VERSION "ZCU_CANFD2"

NS_ :

BS_ :

BU_ :  ETC IHU ZCUD ZCUP

BO_ 427 ZCUDZCUCANFD2Fr34 : 64 ZCUD
 SG_ ActnOfHiBeamDrv : 343|1@0+ (1,0) [0|1] "" IHU
 SG_ ActnOfHiBeamDrv_UB : 342|1@0+ (1,0) [0|1] "" IHU
 SG_ ActnOfLedPosnLamp : 359|1@0+ (1,0) [0|1] "" IHU
 SG_ ActnOfLedPosnLamp_UB : 358|1@0+ (1,0) [0|1] "" IHU
 SG_ ActnOfLedStopLamp_UB : 341|1@0+ (1,0) [0|1] "" IHU
 SG_ ActnOfLedStopLampActnOfLedStopLamp : 340|1@0+ (1,0) [0|1] "" IHU
 SG_ ActnOfLedStopLampChks : 351|8@0+ (1.0,0.0) [0.0|255.0] "Unitless" IHU
 SG_ ActnOfLedStopLampCntr : 339|4@0+ (1.0,0.0) [0.0|15.0] "Unitless" IHU
 SG_ ActnOfLoBeamDrv_UB : 357|1@0+ (1,0) [0|1] "" IHU
 SG_ ActnOfLoBeamDrvChks : 367|8@0+ (1.0,0.0) [0.0|255.0] "Unitless" IHU
 SG_ ActnOfLoBeamDrvCntr : 355|4@0+ (1.0,0.0) [0.0|15.0] "Unitless" IHU
 SG_ ActnOfLoBeamDrvOnOff : 356|1@0+ (1,0) [0|1] "" IHU
 SG_ ActnOfStopLampDrv : 375|1@0+ (1,0) [0|1] "" IHU
 SG_ ActnOfStopLampDrv_UB : 374|1@0+ (1,0) [0|1] "" IHU
 SG_ ActnOfStopLampPass : 373|1@0+ (1,0) [0|1] "" IHU
 SG_ ActnOfStopLampPass_UB : 372|1@0+ (1,0) [0|1] "" IHU
 SG_ ActvnOfAhbc : 371|1@0+ (1,0) [0|1] "" IHU
 SG_ ActvnOfAhbc_UB : 370|1@0+ (1,0) [0|1] "" IHU
 SG_ ActvnOfRvsg : 369|1@0+ (1,0) [0|1] "" IHU
 SG_ ActvnOfRvsg_UB : 368|1@0+ (1,0) [0|1] "" IHU
 SG_ AntithftActvnReq : 334|1@0+ (1,0) [0|1] "" IHU
 SG_ AntithftActvnReq_UB : 333|1@0+ (1,0) [0|1] "" IHU
 SG_ BattLoSts_UB : 407|1@0+ (1,0) [0|1] "" IHU
 SG_ BattLoStsKey0 : 383|2@0+ (1,0) [0|3] "" IHU
 SG_ BattLoStsKey1 : 381|2@0+ (1,0) [0|3] "" IHU
 SG_ BattLoStsKey10 : 395|2@0+ (1,0) [0|3] "" IHU
 SG_ BattLoStsKey11 : 393|2@0+ (1,0) [0|3] "" IHU
 SG_ BattLoStsKey2 : 379|2@0+ (1,0) [0|3] "" IHU
 SG_ BattLoStsKey3 : 377|2@0+ (1,0) [0|3] "" IHU
 SG_ BattLoStsKey4 : 391|2@0+ (1,0) [0|3] "" IHU
 SG_ BattLoStsKey5 : 389|2@0+ (1,0) [0|3] "" IHU
 SG_ BattLoStsKey6 : 387|2@0+ (1,0) [0|3] "" IHU
 SG_ BattLoStsKey7 : 385|2@0+ (1,0) [0|3] "" IHU
 SG_ BattLoStsKey8 : 399|2@0+ (1,0) [0|3] "" IHU
 SG_ BattLoStsKey9 : 397|2@0+ (1,0) [0|3] "" IHU
 SG_ BexvSts_UB : 425|1@0+ (1,0) [0|1] "" IHU
 SG_ BexvStsExvActrPosn : 415|10@0+ (0.2,0.0) [0.0|100.0] "%" IHU
 SG_ BexvStsExvBlkErr : 417|1@0+ (1,0) [0|1] "" IHU
 SG_ BexvStsExvCalibSts : 421|2@0+ (1,0) [0|3] "" IHU
 SG_ BexvStsExvElecStsErr : 431|3@0+ (1,0) [0|7] "" IHU
 SG_ BexvStsExvMovSts : 416|1@0+ (1,0) [0|1] "" IHU
 SG_ BexvStsExvOvrTempErr : 428|1@0+ (1,0) [0|1] "" IHU
 SG_ BexvStsExvOvrTrvlErr : 427|1@0+ (1,0) [0|1] "" IHU
 SG_ BexvStsExvPreHeatgSts : 426|1@0+ (1,0) [0|1] "" IHU
 SG_ BexvStsExvVoltgRangErr : 419|2@0+ (1,0) [0|3] "" IHU
 SG_ BLEKeyBtnTrStsAndKeyId_UB : 406|1@0+ (1,0) [0|1] "" IHU
 SG_ BLEKeyBtnTrStsAndKeyIdBLEBtnSts : 405|2@0+ (1,0) [0|3] "" IHU
 SG_ BLEKeyBtnTrStsAndKeyIdKeyId3 : 403|4@0+ (1,0) [0|15] "" IHU
 SG_ BLEKeyReadStsToKeyRmnWrn_UB : 424|1@0+ (1,0) [0|1] "" IHU
 SG_ BLEKeyReadStsToKeyRmnWrnKey0 : 439|2@0+ (1,0) [0|3] "" IHU
 SG_ BLEKeyReadStsToKeyRmnWrnKey1 : 437|2@0+ (1,0) [0|3] "" IHU
 SG_ BLEKeyReadStsToKeyRmnWrnKey10 : 451|2@0+ (1,0) [0|3] "" IHU
 SG_ BLEKeyReadStsToKeyRmnWrnKey11 : 449|2@0+ (1,0) [0|3] "" IHU
 SG_ BLEKeyReadStsToKeyRmnWrnKey12 : 463|2@0+ (1,0) [0|3] "" IHU
 SG_ BLEKeyReadStsToKeyRmnWrnKey13 : 461|2@0+ (1,0) [0|3] "" IHU
 SG_ BLEKeyReadStsToKeyRmnWrnKey14 : 459|2@0+ (1,0) [0|3] "" IHU
 SG_ BLEKeyReadStsToKeyRmnWrnKey15 : 457|2@0+ (1,0) [0|3] "" IHU
 SG_ BLEKeyReadStsToKeyRmnWrnKey2 : 435|2@0+ (1,0) [0|3] "" IHU
 SG_ BLEKeyReadStsToKeyRmnWrnKey3 : 433|2@0+ (1,0) [0|3] "" IHU
 SG_ BLEKeyReadStsToKeyRmnWrnKey4 : 447|2@0+ (1,0) [0|3] "" IHU
 SG_ BLEKeyReadStsToKeyRmnWrnKey5 : 445|2@0+ (1,0) [0|3] "" IHU
 SG_ BLEKeyReadStsToKeyRmnWrnKey6 : 443|2@0+ (1,0) [0|3] "" IHU
 SG_ BLEKeyReadStsToKeyRmnWrnKey7 : 441|2@0+ (1,0) [0|3] "" IHU
 SG_ BLEKeyReadStsToKeyRmnWrnKey8 : 455|2@0+ (1,0) [0|3] "" IHU
 SG_ BLEKeyReadStsToKeyRmnWrnKey9 : 453|2@0+ (1,0) [0|3] "" IHU
 SG_ BLEKeyReadStsToVMM_UB : 503|1@0+ (1,0) [0|1] "" IHU
 SG_ BLEKeyReadStsToVMMKey0 : 471|2@0+ (1,0) [0|3] "" IHU
 SG_ BLEKeyReadStsToVMMKey1 : 469|2@0+ (1,0) [0|3] "" IHU
 SG_ BLEKeyReadStsToVMMKey10 : 483|2@0+ (1,0) [0|3] "" IHU
 SG_ BLEKeyReadStsToVMMKey11 : 481|2@0+ (1,0) [0|3] "" IHU
 SG_ BLEKeyReadStsToVMMKey12 : 495|2@0+ (1,0) [0|3] "" IHU
 SG_ BLEKeyReadStsToVMMKey13 : 493|2@0+ (1,0) [0|3] "" IHU
 SG_ BLEKeyReadStsToVMMKey14 : 491|2@0+ (1,0) [0|3] "" IHU
 SG_ BLEKeyReadStsToVMMKey15 : 489|2@0+ (1,0) [0|3] "" IHU
 SG_ BLEKeyReadStsToVMMKey2 : 467|2@0+ (1,0) [0|3] "" IHU
 SG_ BLEKeyReadStsToVMMKey3 : 465|2@0+ (1,0) [0|3] "" IHU
 SG_ BLEKeyReadStsToVMMKey4 : 479|2@0+ (1,0) [0|3] "" IHU
 SG_ BLEKeyReadStsToVMMKey5 : 477|2@0+ (1,0) [0|3] "" IHU
 SG_ BLEKeyReadStsToVMMKey6 : 475|2@0+ (1,0) [0|3] "" IHU
 SG_ BLEKeyReadStsToVMMKey7 : 473|2@0+ (1,0) [0|3] "" IHU
 SG_ BLEKeyReadStsToVMMKey8 : 487|2@0+ (1,0) [0|3] "" IHU
 SG_ BLEKeyReadStsToVMMKey9 : 485|2@0+ (1,0) [0|3] "" IHU
 SG_ BtnErsReq : 329|2@0+ (1,0) [0|3] "" IHU
 SG_ BtnErsReq_UB : 330|1@0+ (1,0) [0|1] "" IHU
 SG_ BtnTrSts : 332|1@0+ (1,0) [0|1] "" IHU
 SG_ BtnTrSts_UB : 331|1@0+ (1,0) [0|1] "" IHU
 SG_ CarLoctrAcoustReq : 511|8@0+ (1,0) [0|255] "" IHU
 SG_ CarLoctrAcoustReq_UB : 502|1@0+ (1,0) [0|1] "" IHU
 SG_ CarLoctrAcoustSts : 497|1@0+ (1,0) [0|1] "" IHU
 SG_ CarLoctrAcoustSts_UB : 496|1@0+ (1,0) [0|1] "" IHU
 SG_ CarLoctrExtrLiSts : 499|1@0+ (1,0) [0|1] "" IHU
 SG_ CarLoctrExtrLiSts_UB : 498|1@0+ (1,0) [0|1] "" IHU
 SG_ ChrgHndlStrtEna : 501|1@0+ (1,0) [0|1] "" IHU
 SG_ ChrgHndlStrtEna_UB : 500|1@0+ (1,0) [0|1] "" IHU
 SG_ VoltKL15 : 12|1@0+ (1,0) [0|1] "" IHU
 SG_ VoltKL15_UB : 11|1@0+ (1,0) [0|1] "" IHU
 SG_ WrcActvFlg : 7|8@0+ (1.0,0.0) [0.0|255.0] "Unitless" IHU
 SG_ WrcActvFlg_UB : 15|1@0+ (1,0) [0|1] "" IHU
 SG_ XcuAcc_UB : 10|1@0+ (1,0) [0|1] "" IHU
 SG_ XcuAccPadAnVolt : 23|8@0+ (0.1,0.0) [0.0|25.5] "Unitless" IHU
 SG_ XcuAccPwmDuty : 31|8@0+ (1.0,0.0) [0.0|255.0] "Unitless" IHU
 SG_ XcuCemWakupVolt : 39|8@0+ (0.1,0.0) [0.0|25.5] "Unitless" IHU
 SG_ XcuCemWakupVolt_UB : 9|1@0+ (1,0) [0|1] "" IHU
 SG_ XcuCharge_UB : 130|1@0+ (1,0) [0|1] "" IHU
 SG_ XcuChargeNVolt : 129|10@0+ (1.0,0.0) [0.0|1023.0] "Unitless" IHU
 SG_ XcuChargePVolt : 151|10@0+ (1.0,0.0) [0.0|1023.0] "Unitless" IHU
 SG_ XcuCpuLoad_UB : 8|1@0+ (1,0) [0|1] "" IHU
 SG_ XcuCpuLoadAvgVal : 47|8@0+ (1.0,0.0) [0.0|255.0] "Unitless" IHU
 SG_ XcuCpuLoadMaxVal : 55|8@0+ (1.0,0.0) [0.0|255.0] "Unitless" IHU
 SG_ XcuCpuLoadMinVal : 63|8@0+ (1.0,0.0) [0.0|255.0] "Unitless" IHU
 SG_ XcuDcWakupVolt : 71|8@0+ (0.1,0.0) [0.0|25.5] "Unitless" IHU
 SG_ XcuDcWakupVolt_UB : 135|1@0+ (1,0) [0|1] "" IHU
 SG_ XcuDiagEnblSts : 79|8@0+ (1.0,0.0) [0.0|255.0] "Unitless" IHU
 SG_ XcuDiagEnblSts_UB : 134|1@0+ (1,0) [0|1] "" IHU
 SG_ XcuDseWtTqProp_UB : 133|1@0+ (1,0) [0|1] "" IHU
 SG_ XcuDseWtTqPropFrnt : 87|16@0+ (1.0,-8000.0) [-8000.0|57535.0] "Unitless" IHU
 SG_ XcuDseWtTqPropRear : 103|16@0+ (1.0,-8000.0) [-8000.0|57535.0] "Unitless" IHU
 SG_ XcuHvilDuty : 119|8@0+ (1.0,0.0) [0.0|255.0] "Unitless" IHU
 SG_ XcuHvilDuty_UB : 132|1@0+ (1,0) [0|1] "" IHU
 SG_ XcuLvBatt3Volt : 127|8@0+ (0.1,0.0) [0.0|25.5] "Unitless" IHU
 SG_ XcuLvBatt3Volt_UB : 131|1@0+ (1,0) [0|1] "" IHU
 SG_ XcuPtSnr5v : 167|8@0+ (0.1,0.0) [0.0|25.5] "Unitless" IHU
 SG_ XcuPtSnr5v_UB : 157|1@0+ (1,0) [0|1] "" IHU
 SG_ XcuPwmFanDuty : 175|8@0+ (1.0,0.0) [0.0|255.0] "Unitless" IHU
 SG_ XcuPwmFanDuty_UB : 156|1@0+ (1,0) [0|1] "" IHU
 SG_ XcuReslovSplyVolt : 183|8@0+ (0.1,0.0) [0.0|25.5] "Unitless" IHU
 SG_ XcuReslovSplyVolt_UB : 155|1@0+ (1,0) [0|1] "" IHU
 SG_ XcuSfCEstWhTq_UB : 154|1@0+ (1,0) [0|1] "" IHU
 SG_ XcuSfCEstWhTqFrntBrkTq : 191|16@0+ (1.0,-8000.0) [-8000.0|57535.0] "Unitless" IHU
 SG_ XcuSfCEstWhTqFrntPropTq : 207|16@0+ (1.0,-8000.0) [-8000.0|57535.0] "Unitless" IHU
 SG_ XcuSfCEstWhTqReBrkTq : 223|16@0+ (1.0,-8000.0) [-8000.0|57535.0] "Unitless" IHU
 SG_ XcuSfCEstWhTqRePropTq : 239|16@0+ (1.0,-8000.0) [-8000.0|57535.0] "Unitless" IHU
 SG_ XCUTemp_UB : 153|1@0+ (1,0) [0|1] "" IHU
 SG_ XCUTempXcuMcuTemp : 255|8@0+ (1.0,-40.0) [-40.0|215.0] "degC" IHU
 SG_ XCUTempXcuPcbTemp : 263|8@0+ (1.0,-40.0) [-40.0|215.0] "degC" IHU
 SG_ XcuV_UB : 152|1@0+ (1,0) [0|1] "" IHU
 SG_ XcuVcc5vLsd : 271|8@0+ (0.1,0.0) [0.0|25.5] "Unitless" IHU
 SG_ XcuVcc5VSnr : 279|8@0+ (0.1,0.0) [0.0|25.5] "Unitless" IHU
 SG_ XcuVqco5vT35584 : 287|8@0+ (0.1,0.0) [0.0|25.5] "Unitless" IHU
 SG_ XcuVqt15vT35584 : 295|8@0+ (0.1,0.0) [0.0|25.5] "Unitless" IHU
 SG_ XcuVqt25vT35584 : 303|8@0+ (0.1,0.0) [0.0|25.5] "Unitless" IHU
 SG_ XcuVquc5vT35584 : 311|8@0+ (0.1,0.0) [0.0|25.5] "Unitless" IHU
 SG_ XcuVqvr5vT35584 : 319|8@0+ (0.1,0.0) [0.0|25.5] "Unitless" IHU
 SG_ XcuWakeupReqSrc : 327|8@0+ (1.0,0.0) [0.0|255.0] "Unitless" IHU
 SG_ XcuWakeupReqSrc_UB : 335|1@0+ (1,0) [0|1] "" IHU

BO_ 922 ZCUDZCUCANFD2Fr35 : 64 ZCUD
 SG_ BtnStsOHC_UB : 51|1@0+ (1,0) [0|1] "" IHU
 SG_ BtnStsOHCIntrLiSwtAllOnSts : 55|1@0+ (1,0) [0|1] "" IHU
 SG_ BtnStsOHCIntrLiSwtAutOnSts : 54|1@0+ (1,0) [0|1] "" IHU
 SG_ BtnStsOHCLiBtnReadingLe : 53|1@0+ (1,0) [0|1] "" IHU
 SG_ BtnStsOHCLiBtnReadingRi : 52|1@0+ (1,0) [0|1] "" IHU
 SG_ BtnStsOHCR_UB : 48|1@0+ (1,0) [0|1] "" IHU
 SG_ BtnStsOHCRLiBtnReadingLe : 50|1@0+ (1,0) [0|1] "" IHU
 SG_ BtnStsOHCRLiBtnReadingRi : 49|1@0+ (1,0) [0|1] "" IHU
 SG_ BtnStsOHTR_UB : 61|1@0+ (1,0) [0|1] "" IHU
 SG_ BtnStsOHTRLiBtnReadingLe : 63|1@0+ (1,0) [0|1] "" IHU
 SG_ BtnStsOHTRLiBtnReadingRi : 62|1@0+ (1,0) [0|1] "" IHU
 SG_ IntLightDrvSideDoorSupply : 7|7@0+ (1.0,0.0) [0.0|100.0] "Unitless" IHU
 SG_ IntLightDrvSideDoorSupply_UB : 0|1@0+ (1,0) [0|1] "" IHU
 SG_ IntLightDrvSideSupply : 15|7@0+ (1.0,0.0) [0.0|100.0] "Unitless" IHU
 SG_ IntLightDrvSideSupply_UB : 8|1@0+ (1,0) [0|1] "" IHU
 SG_ IntLightFootwellSupply : 23|7@0+ (1.0,0.0) [0.0|100.0] "Unitless" IHU
 SG_ IntLightFootwellSupply_UB : 16|1@0+ (1,0) [0|1] "" IHU
 SG_ IntLightLuggageSupply : 31|7@0+ (1.0,0.0) [0.0|100.0] "Unitless" IHU
 SG_ IntLightLuggageSupply_UB : 24|1@0+ (1,0) [0|1] "" IHU
 SG_ IntLightReDrvDoorSupply : 39|7@0+ (1.0,0.0) [0.0|100.0] "Unitless" IHU
 SG_ IntLightReDrvDoorSupply_UB : 32|1@0+ (1,0) [0|1] "" IHU
 SG_ IntLightReDrvSideSupply : 47|7@0+ (1.0,0.0) [0.0|100.0] "Unitless" IHU
 SG_ IntLightReDrvSideSupply_UB : 40|1@0+ (1,0) [0|1] "" IHU
 SG_ IntrLiCmdGroup_UB : 60|1@0+ (1,0) [0|1] "" IHU
 SG_ IntrLiCmdGroupIntrLiActvn : 59|1@0+ (1,0) [0|1] "" IHU
 SG_ IntrLiCmdGroupIntrLiRoofDim : 58|1@0+ (1,0) [0|1] "" IHU
 SG_ IntrLiCmdGroupIntrLiRoofDmdOff : 57|1@0+ (1,0) [0|1] "" IHU
 SG_ IntrMirrResp_UB : 56|1@0+ (1,0) [0|1] "" IHU
 SG_ IntrMirrRespIntrMirrDimPerc : 71|8@0+ (0.392156862745,0.0) [0.0|99.999999999975] "%" IHU
 SG_ IntrMirrRespIntrMirrIntFailr : 73|1@0+ (1,0) [0|1] "" IHU
 SG_ IntrMirrRespResdBoolean : 72|1@0+ (1,0) [0|1] "" IHU
 SG_ IntrMirrRespResdUInt6 : 79|6@0+ (1.0,0.0) [0.0|63.0] "Unitless" IHU
 SG_ LiLvrDiagc : 91|2@0+ (1,0) [0|3] "" IHU
 SG_ LiLvrDiagc_UB : 92|1@0+ (1,0) [0|1] "" IHU
 SG_ OHCFrBtnErrSts_UB : 83|1@0+ (1,0) [0|1] "" IHU
 SG_ OHCFrBtnErrStsIntrLiSwtAllOnSts : 87|1@0+ (1,0) [0|1] "" IHU
 SG_ OHCFrBtnErrStsIntrLiSwtAutOnSts : 86|1@0+ (1,0) [0|1] "" IHU
 SG_ OHCFrBtnErrStsLiBtnReadingLe : 85|1@0+ (1,0) [0|1] "" IHU
 SG_ OHCFrBtnErrStsLiBtnReadingRi : 84|1@0+ (1,0) [0|1] "" IHU
 SG_ OHCSecRowBtnErrSts_UB : 80|1@0+ (1,0) [0|1] "" IHU
 SG_ OHCSecRowBtnErrStsLiBtnReadingLe : 82|1@0+ (1,0) [0|1] "" IHU
 SG_ OHCSecRowBtnErrStsLiBtnReadingRi : 81|1@0+ (1,0) [0|1] "" IHU
 SG_ OHCThirdRowBtnErrSts_UB : 93|1@0+ (1,0) [0|1] "" IHU
 SG_ OHCThirdRowBtnErrStsLiBtnReadingLe : 95|1@0+ (1,0) [0|1] "" IHU
 SG_ OHCThirdRowBtnErrStsLiBtnReadingRi : 94|1@0+ (1,0) [0|1] "" IHU
 SG_ RainSnsrDiagc_UB : 96|1@0+ (1,0) [0|1] "" IHU
 SG_ RainSnsrDiagcRainSnsrHiTDetd : 89|1@0+ (1,0) [0|1] "" IHU
 SG_ RainSnsrDiagcRainSnsrHiVoltDetd : 88|1@0+ (1,0) [0|1] "" IHU
 SG_ RainSnsrErr_UB : 107|1@0+ (1,0) [0|1] "" IHU
 SG_ RainSnsrErrCalErr : 111|1@0+ (1,0) [0|1] "" IHU
 SG_ RainSnsrErrCalErrActv : 110|1@0+ (1,0) [0|1] "" IHU
 SG_ RainSnsrErrRainDetnErr : 109|1@0+ (1,0) [0|1] "" IHU
 SG_ RainSnsrErrRainDetnErrActv : 108|1@0+ (1,0) [0|1] "" IHU
 SG_ ReadLiErrSts_UB : 97|1@0+ (1,0) [0|1] "" IHU
 SG_ ReadLiErrStsReadLiStsFirstRowLe : 103|1@0+ (1,0) [0|1] "" IHU
 SG_ ReadLiErrStsReadLiStsFirstRowRi : 102|1@0+ (1,0) [0|1] "" IHU
 SG_ ReadLiErrStsReadLiStsSecondRowLe : 101|1@0+ (1,0) [0|1] "" IHU
 SG_ ReadLiErrStsReadLiStsSecondRowRi : 100|1@0+ (1,0) [0|1] "" IHU
 SG_ ReadLiErrStsReadLiStsThirdRowLe : 99|1@0+ (1,0) [0|1] "" IHU
 SG_ ReadLiErrStsReadLiStsThirdRowRi : 98|1@0+ (1,0) [0|1] "" IHU
 SG_ ReadLiIntensityVal_UB : 154|1@0+ (1,0) [0|1] "" IHU
 SG_ ReadLiIntensityValZone1 : 116|5@0+ (1.0,0.0) [0.0|31.0] "Unitless" IHU
 SG_ ReadLiIntensityValZone2 : 127|5@0+ (1.0,0.0) [0.0|31.0] "Unitless" IHU
 SG_ ReadLiIntensityValZone3 : 135|5@0+ (1.0,0.0) [0.0|31.0] "Unitless" IHU
 SG_ ReadLiIntensityValZone4 : 143|5@0+ (1.0,0.0) [0.0|31.0] "Unitless" IHU
 SG_ ReadLiIntensityValZone5 : 151|5@0+ (1.0,0.0) [0.0|31.0] "Unitless" IHU
 SG_ ReadLiIntensityValZone6 : 159|5@0+ (1.0,0.0) [0.0|31.0] "Unitless" IHU
 SG_ StsOfLogoFolwLoBeam : 105|2@0+ (1,0) [0|3] "" IHU
 SG_ StsOfLogoFolwLoBeam_UB : 106|1@0+ (1,0) [0|1] "" IHU
 SG_ WipgAutFrntMod : 119|2@0+ (1,0) [0|3] "" IHU
 SG_ WipgAutFrntMod_UB : 117|1@0+ (1,0) [0|1] "" IHU
 SG_ WiprLvrDiagc : 153|2@0+ (1,0) [0|3] "" IHU
 SG_ WiprLvrDiagc_UB : 167|1@0+ (1,0) [0|1] "" IHU

BO_ 1264 ZCUDZCUCANFD2Fr36 : 64 ZCUD
 SG_ BswAppVersion : 7|64@0+ (1.0,0.0) [0.0|18446744073709552000.0] "Unitless" IHU
 SG_ BswAppVersion_UB : 183|1@0+ (1,0) [0|1] "" IHU
 SG_ BswCalVersion : 71|64@0+ (1.0,0.0) [0.0|18446744073709552000.0] "Unitless" IHU
 SG_ BswCalVersion_UB : 182|1@0+ (1,0) [0|1] "" IHU
 SG_ BswRervedSignal : 135|32@0+ (1.0,0.0) [0.0|4294967295.0] "Unitless" IHU
 SG_ BswRervedSignal_UB : 181|1@0+ (1,0) [0|1] "" IHU
 SG_ VcEvFehMsgRedPerf : 167|16@0+ (1.0,0.0) [0.0|65535.0] "Unitless" IHU
 SG_ VcEvFehMsgRedPerf_UB : 180|1@0+ (1,0) [0|1] "" IHU

BO_ 431 ZCUDZCUCANFD2Fr37 : 64 ZCUD
 SG_ CarLoctrReq : 55|2@0+ (1.0,0.0) [0.0|3.0] "Unitless" IHU
 SG_ CarLoctrReq_UB : 63|1@0+ (1,0) [0|1] "" IHU
 SG_ CmprSpdIncrReq : 41|1@0+ (1,0) [0|1] "" IHU
 SG_ CmprSpdIncrReq_UB : 40|1@0+ (1,0) [0|1] "" IHU
 SG_ DecUsgModAut : 7|1@0+ (1,0) [0|1] "" IHU
 SG_ DecUsgModAut_UB : 6|1@0+ (1,0) [0|1] "" IHU
 SG_ DecUsgModAut2 : 5|1@0+ (1,0) [0|1] "" IHU
 SG_ DecUsgModAut2_UB : 4|1@0+ (1,0) [0|1] "" IHU
 SG_ DigKeyIntrVldDetd : 3|1@0+ (1,0) [0|1] "" IHU
 SG_ DigKeyIntrVldDetd_UB : 2|1@0+ (1,0) [0|1] "" IHU
 SG_ DlyClsReq : 1|1@0+ (1,0) [0|1] "" IHU
 SG_ DlyClsReq_UB : 0|1@0+ (1,0) [0|1] "" IHU
 SG_ DoorDrvrAcsKeylsReq : 15|2@0+ (1,0) [0|3] "" IHU
 SG_ DoorDrvrAcsKeylsReq_UB : 23|1@0+ (1,0) [0|1] "" IHU
 SG_ DoorDrvrAcsKeylsSts : 43|1@0+ (1,0) [0|1] "" IHU
 SG_ DoorDrvrAcsKeylsSts_UB : 42|1@0+ (1,0) [0|1] "" IHU
 SG_ DoorDrvrHndlCmd : 13|2@0+ (1,0) [0|3] "" IHU
 SG_ DoorDrvrHndlCmd_UB : 22|1@0+ (1,0) [0|1] "" IHU
 SG_ DoorDrvrOpenLowReqOutdSwt1 : 11|2@0+ (1,0) [0|3] "" IHU
 SG_ DoorDrvrOpenLowReqOutdSwt1_UB : 21|1@0+ (1,0) [0|1] "" IHU
 SG_ DoorDrvrOpenReqInsdSwt1 : 9|2@0+ (1,0) [0|3] "" IHU
 SG_ DoorDrvrOpenReqInsdSwt1_UB : 20|1@0+ (1,0) [0|1] "" IHU
 SG_ DoorDrvrRelsReq : 31|2@0+ (1,0) [0|3] "" IHU
 SG_ DoorDrvrRelsReq_UB : 19|1@0+ (1,0) [0|1] "" IHU
 SG_ DoorLeReAcsKeylsReq : 29|2@0+ (1,0) [0|3] "" IHU
 SG_ DoorLeReAcsKeylsReq_UB : 18|1@0+ (1,0) [0|1] "" IHU
 SG_ DoorLeReAcsKeylsSts : 45|1@0+ (1,0) [0|1] "" IHU
 SG_ DoorLeReAcsKeylsSts_UB : 44|1@0+ (1,0) [0|1] "" IHU
 SG_ DoorLeReOpenLowReqOutdSwt1 : 27|2@0+ (1,0) [0|3] "" IHU
 SG_ DoorLeReOpenLowReqOutdSwt1_UB : 17|1@0+ (1,0) [0|1] "" IHU
 SG_ DoorLeReOpenReqInsdSwt1 : 25|2@0+ (1,0) [0|3] "" IHU
 SG_ DoorLeReOpenReqInsdSwt1_UB : 16|1@0+ (1,0) [0|1] "" IHU
 SG_ DoorPassAcsKeylsReq : 39|2@0+ (1,0) [0|3] "" IHU
 SG_ DoorPassAcsKeylsReq_UB : 37|1@0+ (1,0) [0|1] "" IHU
 SG_ DoorPassAcsKeylsSts : 33|1@0+ (1,0) [0|1] "" IHU
 SG_ DoorPassAcsKeylsSts_UB : 32|1@0+ (1,0) [0|1] "" IHU
 SG_ DoorRiReAcsKeylsReq : 35|2@0+ (1,0) [0|3] "" IHU
 SG_ DoorRiReAcsKeylsReq_UB : 36|1@0+ (1,0) [0|1] "" IHU
 SG_ DoorRiReAcsKeylsSts : 47|1@0+ (1,0) [0|1] "" IHU
 SG_ DoorRiReAcsKeylsSts_UB : 46|1@0+ (1,0) [0|1] "" IHU
 SG_ DrvrIntrLockSngSwt : 59|1@0+ (1,0) [0|1] "" IHU
 SG_ DrvrIntrLockSngSwt_UB : 58|1@0+ (1,0) [0|1] "" IHU
 SG_ EasyInOutDrvrReq : 53|2@0+ (1,0) [0|3] "" IHU
 SG_ EasyInOutDrvrReq_UB : 62|1@0+ (1,0) [0|1] "" IHU
 SG_ EngActvnMod1WdReq : 51|2@0+ (1,0) [0|3] "" IHU
 SG_ EngActvnMod1WdReq_UB : 61|1@0+ (1,0) [0|1] "" IHU
 SG_ ErsLockReqByKey : 57|1@0+ (1,0) [0|1] "" IHU
 SG_ ErsLockReqByKey_UB : 56|1@0+ (1,0) [0|1] "" IHU
 SG_ FacQlyForDoorDrvrSts : 49|2@0+ (1,0) [0|3] "" IHU
 SG_ FacQlyForDoorDrvrSts_UB : 60|1@0+ (1,0) [0|1] "" IHU
 SG_ FbOfPrkgLiShow : 119|2@0+ (1,0) [0|3] "" IHU
 SG_ FbOfPrkgLiShow_UB : 117|1@0+ (1,0) [0|1] "" IHU
 SG_ GlvBoxIntrSwtSts : 77|1@0+ (1,0) [0|1] "" IHU
 SG_ GlvBoxIntrSwtSts_UB : 76|1@0+ (1,0) [0|1] "" IHU
 SG_ GrlAutoCalibReq : 75|1@0+ (1,0) [0|1] "" IHU
 SG_ GrlAutoCalibReq_UB : 74|1@0+ (1,0) [0|1] "" IHU
 SG_ GrlHldTrqActive : 73|1@0+ (1,0) [0|1] "" IHU
 SG_ GrlHldTrqActive_UB : 72|1@0+ (1,0) [0|1] "" IHU
 SG_ GrlShttrDmd_UB : 78|1@0+ (1,0) [0|1] "" IHU
 SG_ GrlShttrDmdShttrCalEna : 79|1@0+ (1,0) [0|1] "" IHU
 SG_ GrlShttrDmdShttrPosnReq : 71|8@0+ (1.0,0.0) [0.0|255.0] "Unitless" IHU
 SG_ GrlShttrMoveActive : 106|1@0+ (1,0) [0|1] "" IHU
 SG_ GrlShttrMoveActive_UB : 105|1@0+ (1,0) [0|1] "" IHU
 SG_ GrlShttrSts_UB : 104|1@0+ (1,0) [0|1] "" IHU
 SG_ GrlShttrStsShttrActrFlt : 95|1@0+ (1,0) [0|1] "" IHU
 SG_ GrlShttrStsShttrBlkd : 94|1@0+ (1,0) [0|1] "" IHU
 SG_ GrlShttrStsShttrCalActv : 93|1@0+ (1,0) [0|1] "" IHU
 SG_ GrlShttrStsShttrCalIndcd : 92|1@0+ (1,0) [0|1] "" IHU
 SG_ GrlShttrStsShttrElecErr : 91|1@0+ (1,0) [0|1] "" IHU
 SG_ GrlShttrStsShttrPosnRaw : 87|8@0+ (1.0,0.0) [0.0|255.0] "Unitless" IHU
 SG_ GrlShttrStsShttrSnsrFlt : 90|1@0+ (1,0) [0|1] "" IHU
 SG_ GrlShttrStsShttrTErr : 89|1@0+ (1,0) [0|1] "" IHU
 SG_ GrlShttrStsShttrULoErr : 88|1@0+ (1,0) [0|1] "" IHU
 SG_ HoodSwt1 : 115|2@0+ (1,0) [0|3] "" IHU
 SG_ HoodSwt1_UB : 116|1@0+ (1,0) [0|1] "" IHU
 SG_ KeyDiReq_UB : 107|1@0+ (1,0) [0|1] "" IHU
 SG_ KeyDiReqKey0 : 103|1@0+ (1,0) [0|1] "" IHU
 SG_ KeyDiReqKey1 : 102|1@0+ (1,0) [0|1] "" IHU
 SG_ KeyDiReqKey10 : 109|1@0+ (1,0) [0|1] "" IHU
 SG_ KeyDiReqKey11 : 108|1@0+ (1,0) [0|1] "" IHU
 SG_ KeyDiReqKey2 : 101|1@0+ (1,0) [0|1] "" IHU
 SG_ KeyDiReqKey3 : 100|1@0+ (1,0) [0|1] "" IHU
 SG_ KeyDiReqKey4 : 99|1@0+ (1,0) [0|1] "" IHU
 SG_ KeyDiReqKey5 : 98|1@0+ (1,0) [0|1] "" IHU
 SG_ KeyDiReqKey6 : 97|1@0+ (1,0) [0|1] "" IHU
 SG_ KeyDiReqKey7 : 96|1@0+ (1,0) [0|1] "" IHU
 SG_ KeyDiReqKey8 : 111|1@0+ (1,0) [0|1] "" IHU
 SG_ KeyDiReqKey9 : 110|1@0+ (1,0) [0|1] "" IHU
 SG_ KeyReadReqFromKeyRmn : 127|4@0+ (1,0) [0|15] "" IHU
 SG_ KeyReadReqFromKeyRmn_UB : 113|1@0+ (1,0) [0|1] "" IHU
 SG_ KeyReadReqFromKeyWarn : 123|4@0+ (1,0) [0|15] "" IHU
 SG_ KeyReadReqFromKeyWarn_UB : 112|1@0+ (1,0) [0|1] "" IHU
 SG_ KeyReadStsToKeyRmn_UB : 159|1@0+ (1,0) [0|1] "" IHU
 SG_ KeyReadStsToKeyRmnKey0 : 135|2@0+ (1,0) [0|3] "" IHU
 SG_ KeyReadStsToKeyRmnKey1 : 133|2@0+ (1,0) [0|3] "" IHU
 SG_ KeyReadStsToKeyRmnKey10 : 147|2@0+ (1,0) [0|3] "" IHU
 SG_ KeyReadStsToKeyRmnKey11 : 145|2@0+ (1,0) [0|3] "" IHU
 SG_ KeyReadStsToKeyRmnKey2 : 131|2@0+ (1,0) [0|3] "" IHU
 SG_ KeyReadStsToKeyRmnKey3 : 129|2@0+ (1,0) [0|3] "" IHU
 SG_ KeyReadStsToKeyRmnKey4 : 143|2@0+ (1,0) [0|3] "" IHU
 SG_ KeyReadStsToKeyRmnKey5 : 141|2@0+ (1,0) [0|3] "" IHU
 SG_ KeyReadStsToKeyRmnKey6 : 139|2@0+ (1,0) [0|3] "" IHU
 SG_ KeyReadStsToKeyRmnKey7 : 137|2@0+ (1,0) [0|3] "" IHU
 SG_ KeyReadStsToKeyRmnKey8 : 151|2@0+ (1,0) [0|3] "" IHU
 SG_ KeyReadStsToKeyRmnKey9 : 149|2@0+ (1,0) [0|3] "" IHU
 SG_ KeyReadStsToKeyWarn_UB : 158|1@0+ (1,0) [0|1] "" IHU
 SG_ KeyReadStsToKeyWarnKey0 : 167|2@0+ (1,0) [0|3] "" IHU
 SG_ KeyReadStsToKeyWarnKey1 : 165|2@0+ (1,0) [0|3] "" IHU
 SG_ KeyReadStsToKeyWarnKey10 : 179|2@0+ (1,0) [0|3] "" IHU
 SG_ KeyReadStsToKeyWarnKey11 : 177|2@0+ (1,0) [0|3] "" IHU
 SG_ KeyReadStsToKeyWarnKey2 : 163|2@0+ (1,0) [0|3] "" IHU
 SG_ KeyReadStsToKeyWarnKey3 : 161|2@0+ (1,0) [0|3] "" IHU
 SG_ KeyReadStsToKeyWarnKey4 : 175|2@0+ (1,0) [0|3] "" IHU
 SG_ KeyReadStsToKeyWarnKey5 : 173|2@0+ (1,0) [0|3] "" IHU
 SG_ KeyReadStsToKeyWarnKey6 : 171|2@0+ (1,0) [0|3] "" IHU
 SG_ KeyReadStsToKeyWarnKey7 : 169|2@0+ (1,0) [0|3] "" IHU
 SG_ KeyReadStsToKeyWarnKey8 : 183|2@0+ (1,0) [0|3] "" IHU
 SG_ KeyReadStsToKeyWarnKey9 : 181|2@0+ (1,0) [0|3] "" IHU
 SG_ KeyReadStsToVmm_UB : 157|1@0+ (1,0) [0|1] "" IHU
 SG_ KeyReadStsToVmmKey0 : 191|2@0+ (1,0) [0|3] "" IHU
 SG_ KeyReadStsToVmmKey1 : 189|2@0+ (1,0) [0|3] "" IHU
 SG_ KeyReadStsToVmmKey10 : 203|2@0+ (1,0) [0|3] "" IHU
 SG_ KeyReadStsToVmmKey11 : 201|2@0+ (1,0) [0|3] "" IHU
 SG_ KeyReadStsToVmmKey2 : 187|2@0+ (1,0) [0|3] "" IHU
 SG_ KeyReadStsToVmmKey3 : 185|2@0+ (1,0) [0|3] "" IHU
 SG_ KeyReadStsToVmmKey4 : 199|2@0+ (1,0) [0|3] "" IHU
 SG_ KeyReadStsToVmmKey5 : 197|2@0+ (1,0) [0|3] "" IHU
 SG_ KeyReadStsToVmmKey6 : 195|2@0+ (1,0) [0|3] "" IHU
 SG_ KeyReadStsToVmmKey7 : 193|2@0+ (1,0) [0|3] "" IHU
 SG_ KeyReadStsToVmmKey8 : 207|2@0+ (1,0) [0|3] "" IHU
 SG_ KeyReadStsToVmmKey9 : 205|2@0+ (1,0) [0|3] "" IHU
 SG_ KeyReadStsToVMMNFC_UB : 156|1@0+ (1,0) [0|1] "" IHU
 SG_ KeyReadStsToVMMNFCKey0 : 215|2@0+ (1,0) [0|3] "" IHU
 SG_ KeyReadStsToVMMNFCKey1 : 213|2@0+ (1,0) [0|3] "" IHU
 SG_ KeyReadStsToVMMNFCKey10 : 227|2@0+ (1,0) [0|3] "" IHU
 SG_ KeyReadStsToVMMNFCKey11 : 225|2@0+ (1,0) [0|3] "" IHU
 SG_ KeyReadStsToVMMNFCKey12 : 239|2@0+ (1,0) [0|3] "" IHU
 SG_ KeyReadStsToVMMNFCKey13 : 237|2@0+ (1,0) [0|3] "" IHU
 SG_ KeyReadStsToVMMNFCKey14 : 235|2@0+ (1,0) [0|3] "" IHU
 SG_ KeyReadStsToVMMNFCKey15 : 233|2@0+ (1,0) [0|3] "" IHU
 SG_ KeyReadStsToVMMNFCKey2 : 211|2@0+ (1,0) [0|3] "" IHU
 SG_ KeyReadStsToVMMNFCKey3 : 209|2@0+ (1,0) [0|3] "" IHU
 SG_ KeyReadStsToVMMNFCKey4 : 223|2@0+ (1,0) [0|3] "" IHU
 SG_ KeyReadStsToVMMNFCKey5 : 221|2@0+ (1,0) [0|3] "" IHU
 SG_ KeyReadStsToVMMNFCKey6 : 219|2@0+ (1,0) [0|3] "" IHU
 SG_ KeyReadStsToVMMNFCKey7 : 217|2@0+ (1,0) [0|3] "" IHU
 SG_ KeyReadStsToVMMNFCKey8 : 231|2@0+ (1,0) [0|3] "" IHU
 SG_ KeyReadStsToVMMNFCKey9 : 229|2@0+ (1,0) [0|3] "" IHU
 SG_ LiOprnMod : 247|2@0+ (1,0) [0|3] "" IHU
 SG_ LiOprnMod_UB : 245|1@0+ (1,0) [0|1] "" IHU
 SG_ MobDeBtnCarLctrSts : 244|1@0+ (1,0) [0|1] "" IHU
 SG_ MobDeBtnCarLctrSts_UB : 243|1@0+ (1,0) [0|1] "" IHU
 SG_ MobDeBtnPanicAlarmSts : 241|2@0+ (1,0) [0|3] "" IHU
 SG_ MobDeBtnPanicAlarmSts_UB : 242|1@0+ (1,0) [0|1] "" IHU
 SG_ MobDevAVPReq : 249|1@0+ (1,0) [0|1] "" IHU
 SG_ MobDevAVPReq_UB : 248|1@0+ (1,0) [0|1] "" IHU
 SG_ MobDevBtnLockStsAndKeyId_UB : 250|1@0+ (1,0) [0|1] "" IHU
 SG_ MobDevBtnLockStsAndKeyIdKeyId3 : 255|4@0+ (1,0) [0|15] "" IHU
 SG_ MobDevBtnLockStsAndKeyIdPsdNotPsd : 251|1@0+ (1,0) [0|1] "" IHU
 SG_ MobDevBtnTrReq : 327|3@0+ (1,0) [0|7] "" IHU
 SG_ MobDevBtnTrReq_UB : 324|1@0+ (1,0) [0|1] "" IHU
 SG_ MobDevBtnUnlckStsAndKeyId_UB : 258|1@0+ (1,0) [0|1] "" IHU
 SG_ MobDevBtnUnlckStsAndKeyIdKeyId3 : 263|4@0+ (1,0) [0|15] "" IHU
 SG_ MobDevBtnUnlckStsAndKeyIdPsdNotPsd : 259|1@0+ (1,0) [0|1] "" IHU
 SG_ MobDevChrgngLidOpnReq : 257|1@0+ (1,0) [0|1] "" IHU
 SG_ MobDevChrgngLidOpnReq_UB : 256|1@0+ (1,0) [0|1] "" IHU
 SG_ MobDevKeyDiReq_UB : 287|1@0+ (1,0) [0|1] "" IHU
 SG_ MobDevKeyDiReqKeySts0 : 271|1@0+ (1,0) [0|1] "" IHU
 SG_ MobDevKeyDiReqKeySts1 : 270|1@0+ (1,0) [0|1] "" IHU
 SG_ MobDevKeyDiReqKeySts10 : 277|1@0+ (1,0) [0|1] "" IHU
 SG_ MobDevKeyDiReqKeySts11 : 276|1@0+ (1,0) [0|1] "" IHU
 SG_ MobDevKeyDiReqKeySts12 : 275|1@0+ (1,0) [0|1] "" IHU
 SG_ MobDevKeyDiReqKeySts13 : 274|1@0+ (1,0) [0|1] "" IHU
 SG_ MobDevKeyDiReqKeySts14 : 273|1@0+ (1,0) [0|1] "" IHU
 SG_ MobDevKeyDiReqKeySts15 : 272|1@0+ (1,0) [0|1] "" IHU
 SG_ MobDevKeyDiReqKeySts2 : 269|1@0+ (1,0) [0|1] "" IHU
 SG_ MobDevKeyDiReqKeySts3 : 268|1@0+ (1,0) [0|1] "" IHU
 SG_ MobDevKeyDiReqKeySts4 : 267|1@0+ (1,0) [0|1] "" IHU
 SG_ MobDevKeyDiReqKeySts5 : 266|1@0+ (1,0) [0|1] "" IHU
 SG_ MobDevKeyDiReqKeySts6 : 265|1@0+ (1,0) [0|1] "" IHU
 SG_ MobDevKeyDiReqKeySts7 : 264|1@0+ (1,0) [0|1] "" IHU
 SG_ MobDevKeyDiReqKeySts8 : 279|1@0+ (1,0) [0|1] "" IHU
 SG_ MobDevKeyDiReqKeySts9 : 278|1@0+ (1,0) [0|1] "" IHU
 SG_ MobDevKeyEnaSts_UB : 286|1@0+ (1,0) [0|1] "" IHU
 SG_ MobDevKeyEnaStsKey0 : 295|2@0+ (1,0) [0|3] "" IHU
 SG_ MobDevKeyEnaStsKey1 : 293|2@0+ (1,0) [0|3] "" IHU
 SG_ MobDevKeyEnaStsKey10 : 307|2@0+ (1,0) [0|3] "" IHU
 SG_ MobDevKeyEnaStsKey11 : 305|2@0+ (1,0) [0|3] "" IHU
 SG_ MobDevKeyEnaStsKey12 : 319|2@0+ (1,0) [0|3] "" IHU
 SG_ MobDevKeyEnaStsKey13 : 317|2@0+ (1,0) [0|3] "" IHU
 SG_ MobDevKeyEnaStsKey14 : 315|2@0+ (1,0) [0|3] "" IHU
 SG_ MobDevKeyEnaStsKey15 : 313|2@0+ (1,0) [0|3] "" IHU
 SG_ MobDevKeyEnaStsKey2 : 291|2@0+ (1,0) [0|3] "" IHU
 SG_ MobDevKeyEnaStsKey3 : 289|2@0+ (1,0) [0|3] "" IHU
 SG_ MobDevKeyEnaStsKey4 : 303|2@0+ (1,0) [0|3] "" IHU
 SG_ MobDevKeyEnaStsKey5 : 301|2@0+ (1,0) [0|3] "" IHU
 SG_ MobDevKeyEnaStsKey6 : 299|2@0+ (1,0) [0|3] "" IHU
 SG_ MobDevKeyEnaStsKey7 : 297|2@0+ (1,0) [0|3] "" IHU
 SG_ MobDevKeyEnaStsKey8 : 311|2@0+ (1,0) [0|3] "" IHU
 SG_ MobDevKeyEnaStsKey9 : 309|2@0+ (1,0) [0|3] "" IHU
 SG_ MobDevOpenClsCmftReq : 285|2@0+ (1,0) [0|3] "" IHU
 SG_ MobDevOpenClsCmftReq_UB : 283|1@0+ (1,0) [0|1] "" IHU
 SG_ MobDevRoofOpnClsReq : 281|2@0+ (1,0) [0|3] "" IHU
 SG_ MobDevRoofOpnClsReq_UB : 282|1@0+ (1,0) [0|1] "" IHU
 SG_ MobDevVldUserStsToVMM : 384|1@0+ (1,0) [0|1] "" IHU
 SG_ MobDevVldUserStsToVMM_UB : 368|1@0+ (1,0) [0|1] "" IHU
 SG_ MobDevWinOpnClsReq : 323|2@0+ (1,0) [0|3] "" IHU
 SG_ MobDevWinOpnClsReq_UB : 321|1@0+ (1,0) [0|1] "" IHU
 SG_ NFCKeyReadStsToKeyRmnWrn_UB : 320|1@0+ (1,0) [0|1] "" IHU
 SG_ NFCKeyReadStsToKeyRmnWrnKey0 : 335|2@0+ (1,0) [0|3] "" IHU
 SG_ NFCKeyReadStsToKeyRmnWrnKey1 : 333|2@0+ (1,0) [0|3] "" IHU
 SG_ NFCKeyReadStsToKeyRmnWrnKey10 : 347|2@0+ (1,0) [0|3] "" IHU
 SG_ NFCKeyReadStsToKeyRmnWrnKey11 : 345|2@0+ (1,0) [0|3] "" IHU
 SG_ NFCKeyReadStsToKeyRmnWrnKey12 : 359|2@0+ (1,0) [0|3] "" IHU
 SG_ NFCKeyReadStsToKeyRmnWrnKey13 : 357|2@0+ (1,0) [0|3] "" IHU
 SG_ NFCKeyReadStsToKeyRmnWrnKey14 : 355|2@0+ (1,0) [0|3] "" IHU
 SG_ NFCKeyReadStsToKeyRmnWrnKey15 : 353|2@0+ (1,0) [0|3] "" IHU
 SG_ NFCKeyReadStsToKeyRmnWrnKey2 : 331|2@0+ (1,0) [0|3] "" IHU
 SG_ NFCKeyReadStsToKeyRmnWrnKey3 : 329|2@0+ (1,0) [0|3] "" IHU
 SG_ NFCKeyReadStsToKeyRmnWrnKey4 : 343|2@0+ (1,0) [0|3] "" IHU
 SG_ NFCKeyReadStsToKeyRmnWrnKey5 : 341|2@0+ (1,0) [0|3] "" IHU
 SG_ NFCKeyReadStsToKeyRmnWrnKey6 : 339|2@0+ (1,0) [0|3] "" IHU
 SG_ NFCKeyReadStsToKeyRmnWrnKey7 : 337|2@0+ (1,0) [0|3] "" IHU
 SG_ NFCKeyReadStsToKeyRmnWrnKey8 : 351|2@0+ (1,0) [0|3] "" IHU
 SG_ NFCKeyReadStsToKeyRmnWrnKey9 : 349|2@0+ (1,0) [0|3] "" IHU
 SG_ OutdBri_UB : 369|1@0+ (1,0) [0|1] "" IHU
 SG_ OutdBriChks : 367|8@0+ (1.0,0.0) [0.0|255.0] "Unitless" IHU
 SG_ OutdBriCntr : 375|4@0+ (1.0,0.0) [0.0|15.0] "Unitless" IHU
 SG_ OutdBriHw_UB : 385|1@0+ (1,0) [0|1] "" IHU
 SG_ OutdBriHwChks : 383|8@0+ (1.0,0.0) [0.0|255.0] "Unitless" IHU
 SG_ OutdBriHwCntr : 391|4@0+ (1.0,0.0) [0.0|15.0] "Unitless" IHU
 SG_ OutdBriHwOutdBriSts : 387|2@0+ (1,0) [0|3] "" IHU
 SG_ OutdBriSts : 371|2@0+ (1,0) [0|3] "" IHU
 SG_ SteerLockChk_UB : 454|1@0+ (1,0) [0|1] "" IHU
 SG_ SteerLockChkSteerLockDataChk0 : 399|8@0+ (1.0,0.0) [0.0|255.0] "Unitless" IHU
 SG_ SteerLockChkSteerLockDataChk1 : 407|8@0+ (1.0,0.0) [0.0|255.0] "Unitless" IHU
 SG_ SteerLockChkSteerLockDataChk2 : 415|8@0+ (1.0,0.0) [0.0|255.0] "Unitless" IHU
 SG_ SteerLockChkSteerLockDataChk3 : 423|8@0+ (1.0,0.0) [0.0|255.0] "Unitless" IHU
 SG_ SteerLockChkSteerLockDataChk4 : 431|8@0+ (1.0,0.0) [0.0|255.0] "Unitless" IHU
 SG_ SteerLockChkSteerLockDataChk5 : 439|8@0+ (1.0,0.0) [0.0|255.0] "Unitless" IHU
 SG_ SteerLockChkSteerLockDataChk6 : 447|8@0+ (1.0,0.0) [0.0|255.0] "Unitless" IHU
 SG_ SteerLockChkSts : 455|1@0+ (1,0) [0|1] "" IHU
 SG_ SteerLockReq_UB : 450|1@0+ (1,0) [0|1] "" IHU
 SG_ SteerLockReqCommand : 449|2@0+ (1,0) [0|3] "" IHU
 SG_ SteerLockReqSteerLockDataReq0 : 463|8@0+ (1.0,0.0) [0.0|255.0] "Unitless" IHU
 SG_ SteerLockReqSteerLockDataReq1 : 471|8@0+ (1.0,0.0) [0.0|255.0] "Unitless" IHU
 SG_ SteerLockReqSteerLockDataReq2 : 479|8@0+ (1.0,0.0) [0.0|255.0] "Unitless" IHU
 SG_ SteerLockReqSteerLockDataReq3 : 487|8@0+ (1.0,0.0) [0.0|255.0] "Unitless" IHU
 SG_ SteerLockReqSteerLockDataReq4 : 495|8@0+ (1.0,0.0) [0.0|255.0] "Unitless" IHU
 SG_ SteerLockReqSteerLockDataReq5 : 503|8@0+ (1.0,0.0) [0.0|255.0] "Unitless" IHU
 SG_ SteerLockReqSteerLockDataReq6 : 511|8@0+ (1.0,0.0) [0.0|255.0] "Unitless" IHU
 SG_ WinWshrLvrCmd : 453|2@0+ (1,0) [0|3] "" IHU
 SG_ WinWshrLvrCmd_UB : 451|1@0+ (1,0) [0|1] "" IHU

BO_ 1189 ZCUDZCUCANFD2Fr38 : 64 ZCUD
 SG_ EtpZeroCrc_UB : 127|1@0+ (1,0) [0|1] "" IHU
 SG_ EtpZeroCrc1 : 7|8@0+ (1.0,0.0) [0.0|255.0] "Unitless" IHU
 SG_ EtpZeroCrc2 : 15|8@0+ (1.0,0.0) [0.0|255.0] "Unitless" IHU
 SG_ EtpZeroCrcEtpZeroCrc : 23|8@0+ (1.0,0.0) [0.0|255.0] "Unitless" IHU
 SG_ EtpZeroDegrVal_UB : 126|1@0+ (1,0) [0|1] "" IHU
 SG_ EtpZeroDegrVal1 : 31|16@0+ (1.0,0.0) [0.0|65535.0] "Unitless" IHU
 SG_ EtpZeroDegrVal2 : 47|16@0+ (1.0,0.0) [0.0|65535.0] "Unitless" IHU
 SG_ EtpZeroDegrValEtpZeroDegrVal : 63|16@0+ (1.0,0.0) [0.0|65535.0] "Unitless" IHU
 SG_ EtpZeroSuccessFlag_UB : 125|1@0+ (1,0) [0|1] "" IHU
 SG_ EtpZeroSuccessFlag1 : 79|16@0+ (1.0,0.0) [0.0|65535.0] "Unitless" IHU
 SG_ EtpZeroSuccessFlag2 : 95|16@0+ (1.0,0.0) [0.0|65535.0] "Unitless" IHU
 SG_ EtpZeroSuccessFlagEtpZeroSuccessFlag : 111|16@0+ (1.0,0.0) [0.0|65535.0] "Unitless" IHU
 SG_ SnsrInclnCmd : 121|1@0+ (1,0) [0|1] "" IHU
 SG_ SnsrInclnCmd_UB : 120|1@0+ (1,0) [0|1] "" IHU
 SG_ SnsrIntrScanCmd_UB : 146|1@0+ (1,0) [0|1] "" IHU
 SG_ SnsrIntrScanCmdAirFanSts : 151|1@0+ (1,0) [0|1] "" IHU
 SG_ SnsrIntrScanCmdArmReq : 150|1@0+ (1,0) [0|1] "" IHU
 SG_ SnsrIntrScanCmdCurtRollUpDwn : 149|1@0+ (1,0) [0|1] "" IHU
 SG_ SnsrIntrScanCmdRoofPosn : 148|1@0+ (1,0) [0|1] "" IHU
 SG_ SnsrIntrScanCmdTemp : 143|8@0+ (1.0,0.0) [0.0|255.0] "Unitless" IHU
 SG_ SnsrIntrScanCmdWinPosn : 147|1@0+ (1,0) [0|1] "" IHU
 SG_ SnsrSoundrBattBackedCmd_UB : 153|1@0+ (1,0) [0|1] "" IHU
 SG_ SnsrSoundrBattBackedCmdArmCmd : 156|1@0+ (1,0) [0|1] "" IHU
 SG_ SnsrSoundrBattBackedCmdChirpTyp : 159|3@0+ (1.0,0.0) [0.0|7.0] "Unitless" IHU
 SG_ SnsrSoundrBattBackedCmdChrgReq : 155|1@0+ (1,0) [0|1] "" IHU
 SG_ SnsrSoundrBattBackedCmdSoundReq : 154|1@0+ (1,0) [0|1] "" IHU
 SG_ SunRoofAndCurtPosnCmd_UB : 128|1@0+ (1,0) [0|1] "" IHU
 SG_ SunRoofAndCurtPosnCmdOpenPerc : 135|5@0+ (1,0) [0|31] "" IHU
 SG_ SunRoofAndCurtPosnCmdSel : 130|2@0+ (1,0) [0|3] "" IHU
 SG_ SunRoofEna : 123|2@0+ (1,0) [0|3] "" IHU
 SG_ SunRoofEna_UB : 124|1@0+ (1,0) [0|1] "" IHU
 SG_ TCSDcdcactvdReq : 145|2@0+ (1,0) [0|3] "" IHU
 SG_ TCSDcdcactvdReq_UB : 152|1@0+ (1,0) [0|1] "" IHU
 SG_ TCSUsgModReq : 181|1@0+ (1,0) [0|1] "" IHU
 SG_ TCSUsgModReq_UB : 180|1@0+ (1,0) [0|1] "" IHU
 SG_ ThirdRowLeReadLiReq : 167|8@0+ (1.0,0.0) [0.0|100.0] "%" IHU
 SG_ ThirdRowLeReadLiReq_UB : 183|1@0+ (1,0) [0|1] "" IHU
 SG_ ThirdRowRiReadLiReq : 175|8@0+ (1.0,0.0) [0.0|100.0] "%" IHU
 SG_ ThirdRowRiReadLiReq_UB : 182|1@0+ (1,0) [0|1] "" IHU
 SG_ TrlrLiBrkActvt : 179|1@0+ (1,0) [0|1] "" IHU
 SG_ TrlrLiBrkActvt_UB : 178|1@0+ (1,0) [0|1] "" IHU
 SG_ TrlrLiFogActvt : 177|1@0+ (1,0) [0|1] "" IHU
 SG_ TrlrLiFogActvt_UB : 176|1@0+ (1,0) [0|1] "" IHU
 SG_ TrlrLiPosnActvt : 191|2@0+ (1,0) [0|3] "" IHU
 SG_ TrlrLiPosnActvt_UB : 189|1@0+ (1,0) [0|1] "" IHU
 SG_ TrlrLiRvsgActvt : 188|1@0+ (1,0) [0|1] "" IHU
 SG_ TrlrLiRvsgActvt_UB : 187|1@0+ (1,0) [0|1] "" IHU
 SG_ VcEvFehMsgHybridFlt : 199|24@0+ (1.0,0.0) [0.0|16777215.0] "Unitless" IHU
 SG_ VcEvFehMsgHybridFlt_UB : 186|1@0+ (1,0) [0|1] "" IHU
 SG_ VcEvFehMsgStopSafely : 223|8@0+ (1.0,0.0) [0.0|255.0] "Unitless" IHU
 SG_ VcEvFehMsgStopSafely_UB : 185|1@0+ (1,0) [0|1] "" IHU
 SG_ VcEvFunction21 : 231|16@0+ (1.0,0.0) [0.0|65535.0] "Unitless" IHU
 SG_ VcEvFunction21_UB : 184|1@0+ (1,0) [0|1] "" IHU
 SG_ VcEvPowerUpFail : 247|16@0+ (1.0,0.0) [0.0|65535.0] "Unitless" IHU
 SG_ VcEvPowerUpFail_UB : 327|1@0+ (1,0) [0|1] "" IHU
 SG_ VcEvPropStartInhibit : 263|8@0+ (1.0,0.0) [0.0|255.0] "Unitless" IHU
 SG_ VcEvPropStartInhibit_UB : 326|1@0+ (1,0) [0|1] "" IHU
 SG_ VcEvSymCC : 271|8@0+ (1.0,0.0) [0.0|255.0] "Unitless" IHU
 SG_ VcEvSymCC_UB : 325|1@0+ (1,0) [0|1] "" IHU
 SG_ VcEvSymRed : 279|16@0+ (1.0,0.0) [0.0|65535.0] "Unitless" IHU
 SG_ VcEvSymRed_UB : 324|1@0+ (1,0) [0|1] "" IHU
 SG_ VcEvUnexpctClearDCA : 295|16@0+ (1.0,0.0) [0.0|65535.0] "Unitless" IHU
 SG_ VcEvUnexpctClearDCA_UB : 323|1@0+ (1,0) [0|1] "" IHU
 SG_ VcEvUnexpPowerDown : 311|16@0+ (1.0,0.0) [0.0|65535.0] "Unitless" IHU
 SG_ VcEvUnexpPowerDown_UB : 322|1@0+ (1,0) [0|1] "" IHU
 SG_ WindCorrnVal_UB : 359|1@0+ (1,0) [0|1] "" IHU
 SG_ WindCorrnValAmb : 335|8@0+ (1.0,0.0) [0.0|255.0] "Unitless" IHU
 SG_ WindCorrnValFrnt : 343|8@0+ (1.0,0.0) [0.0|255.0] "Unitless" IHU
 SG_ WindCorrnValHud : 351|8@0+ (1.0,0.0) [0.0|255.0] "Unitless" IHU
 SG_ WinDsblLeftSts : 321|1@0+ (1,0) [0|1] "" IHU
 SG_ WinDsblLeftSts_UB : 320|1@0+ (1,0) [0|1] "" IHU
 SG_ WinHwSwtDrvrReDoor : 355|3@0+ (1,0) [0|7] "" IHU
 SG_ WinHwSwtDrvrReDoor_UB : 352|1@0+ (1,0) [0|1] "" IHU
 SG_ WipgPwrActvnNotSafe_UB : 358|1@0+ (1,0) [0|1] "" IHU
 SG_ WipgPwrActvnNotSafeAcsyMode : 357|1@0+ (1,0) [0|1] "" IHU
 SG_ WipgPwrActvnNotSafeDrvgMod : 356|1@0+ (1,0) [0|1] "" IHU
 SG_ WipgPwrActvnSafe_UB : 363|1@0+ (1,0) [0|1] "" IHU
 SG_ WipgPwrActvnSafeWipgPwrAcsyModSafe : 367|2@0+ (1,0) [0|3] "" IHU
 SG_ WipgPwrActvnSafeWipgPwrDrvgModSafe : 365|2@0+ (1,0) [0|3] "" IHU
 SG_ WiprActvMech : 362|1@0+ (1,0) [0|1] "" IHU
 SG_ WiprActvMech_UB : 361|1@0+ (1,0) [0|1] "" IHU
 SG_ WiprInPrkgPosnLo : 407|1@0+ (1,0) [0|1] "" IHU
 SG_ WiprInPrkgPosnLo_UB : 406|1@0+ (1,0) [0|1] "" IHU
 SG_ WiprInWipgArMech : 405|1@0+ (1,0) [0|1] "" IHU
 SG_ WiprInWipgArMech_UB : 404|1@0+ (1,0) [0|1] "" IHU
 SG_ WiprLvrComErrDetd : 403|1@0+ (1,0) [0|1] "" IHU
 SG_ WiprLvrComErrDetd_UB : 402|1@0+ (1,0) [0|1] "" IHU
 SG_ WiprLvrNodErrDetd : 401|1@0+ (1,0) [0|1] "" IHU
 SG_ WiprLvrNodErrDetd_UB : 400|1@0+ (1,0) [0|1] "" IHU
 SG_ WiprMotComErrDetd : 415|1@0+ (1,0) [0|1] "" IHU
 SG_ WiprMotComErrDetd_UB : 414|1@0+ (1,0) [0|1] "" IHU
 SG_ WiprMotErr : 413|1@0+ (1,0) [0|1] "" IHU
 SG_ WiprMotErr_UB : 412|1@0+ (1,0) [0|1] "" IHU
 SG_ WiprMotErrSafeMech : 411|2@0+ (1,0) [0|3] "" IHU
 SG_ WiprMotErrSafeMech_UB : 409|1@0+ (1,0) [0|1] "" IHU
 SG_ WiprMotFrntLvrCmdNotSafe_UB : 408|1@0+ (1,0) [0|1] "" IHU
 SG_ WiprMotFrntLvrCmdNotSafeLvrInHiSpdPosn : 423|1@0+ (1,0) [0|1] "" IHU
 SG_ WiprMotFrntLvrCmdNotSafeLvrInIntlPosn : 422|1@0+ (1,0) [0|1] "" IHU
 SG_ WiprMotFrntLvrCmdNotSafeLvrInLoSpdPosn : 421|1@0+ (1,0) [0|1] "" IHU
 SG_ WiprMotFrntLvrCmdNotSafeLvrInSnglStrokePos : 420|1@0+ (1,0) [0|1] "" IHU
 SG_ WiprMotFrntOffsAg : 431|4@0+ (1.0,0.0) [0.0|15.0] "Deg" IHU
 SG_ WiprMotFrntOffsAg_UB : 427|1@0+ (1,0) [0|1] "" IHU
 SG_ WiprMotIntlCmd : 419|3@0+ (1,0) [0|7] "" IHU
 SG_ WiprMotIntlCmd_UB : 416|1@0+ (1,0) [0|1] "" IHU
 SG_ WiprMotNodErrDetd : 426|1@0+ (1,0) [0|1] "" IHU
 SG_ WiprMotNodErrDetd_UB : 425|1@0+ (1,0) [0|1] "" IHU
 SG_ WiprMotRelayMech : 439|1@0+ (1,0) [0|1] "" IHU
 SG_ WiprMotRelayMech_UB : 438|1@0+ (1,0) [0|1] "" IHU
 SG_ WiprPosnForSrvReq : 437|1@0+ (1,0) [0|1] "" IHU
 SG_ WiprPosnForSrvReq_UB : 436|1@0+ (1,0) [0|1] "" IHU
 SG_ WiprReInWipgAr : 435|1@0+ (1,0) [0|1] "" IHU
 SG_ WiprReInWipgAr_UB : 434|1@0+ (1,0) [0|1] "" IHU
 SG_ WiprWshrMgrErrDetd : 433|1@0+ (1,0) [0|1] "" IHU
 SG_ WiprWshrMgrErrDetd_UB : 432|1@0+ (1,0) [0|1] "" IHU
 SG_ WshngCycActv : 455|1@0+ (1,0) [0|1] "" IHU
 SG_ WshngCycActv_UB : 454|1@0+ (1,0) [0|1] "" IHU
 SG_ WshngCycActvMech : 453|1@0+ (1,0) [0|1] "" IHU
 SG_ WshngCycActvMech_UB : 452|1@0+ (1,0) [0|1] "" IHU
 SG_ WshrFldLvlDetdLo : 451|1@0+ (1,0) [0|1] "" IHU
 SG_ WshrFldLvlDetdLo_UB : 450|1@0+ (1,0) [0|1] "" IHU
 SG_ WshrHeatgSig : 447|8@0+ (0.1,0.0) [0.0|25.0] "Volt" IHU
 SG_ WshrHeatgSig_UB : 424|1@0+ (1,0) [0|1] "" IHU
 SG_ WshrLvrPosnNotSafe : 449|1@0+ (1,0) [0|1] "" IHU
 SG_ WshrLvrPosnNotSafe_UB : 448|1@0+ (1,0) [0|1] "" IHU
 SG_ WshrLvrPosnSafe : 463|2@0+ (1,0) [0|3] "" IHU
 SG_ WshrLvrPosnSafe_UB : 461|1@0+ (1,0) [0|1] "" IHU
 SG_ XCUPcodeStatus : 375|32@0+ (1.0,0.0) [0.0|4294967295.0] "Unitless" IHU
 SG_ XCUPcodeStatus_UB : 360|1@0+ (1,0) [0|1] "" IHU

BO_ 1348 ZCUDZCUCANFD2VFCVectorFr : 8 ZCUD
 SG_ VFCVectorZCUDMBlockID : 1|2@0+ (1.0,0.0) [0.0|3.0] "Unitless" IHU
 SG_ VFCVectorZCUDMVFCid0 : 2|1@0+ (1,0) [0|1] "" IHU
 SG_ VFCVectorZCUDMVFCid1 : 3|1@0+ (1,0) [0|1] "" IHU
 SG_ VFCVectorZCUDMVFCid10 : 12|1@0+ (1,0) [0|1] "" IHU
 SG_ VFCVectorZCUDMVFCid11 : 13|1@0+ (1,0) [0|1] "" IHU
 SG_ VFCVectorZCUDMVFCid12 : 14|1@0+ (1,0) [0|1] "" IHU
 SG_ VFCVectorZCUDMVFCid13 : 15|1@0+ (1,0) [0|1] "" IHU
 SG_ VFCVectorZCUDMVFCid14 : 16|1@0+ (1,0) [0|1] "" IHU
 SG_ VFCVectorZCUDMVFCid15 : 17|1@0+ (1,0) [0|1] "" IHU
 SG_ VFCVectorZCUDMVFCid16 : 18|1@0+ (1,0) [0|1] "" IHU
 SG_ VFCVectorZCUDMVFCid17 : 19|1@0+ (1,0) [0|1] "" IHU
 SG_ VFCVectorZCUDMVFCid18 : 20|1@0+ (1,0) [0|1] "" IHU
 SG_ VFCVectorZCUDMVFCid19 : 21|1@0+ (1,0) [0|1] "" IHU
 SG_ VFCVectorZCUDMVFCid2 : 4|1@0+ (1,0) [0|1] "" IHU
 SG_ VFCVectorZCUDMVFCid20 : 22|1@0+ (1,0) [0|1] "" IHU
 SG_ VFCVectorZCUDMVFCid21 : 23|1@0+ (1,0) [0|1] "" IHU
 SG_ VFCVectorZCUDMVFCid22 : 24|1@0+ (1,0) [0|1] "" IHU
 SG_ VFCVectorZCUDMVFCid23 : 25|1@0+ (1,0) [0|1] "" IHU
 SG_ VFCVectorZCUDMVFCid24 : 26|1@0+ (1,0) [0|1] "" IHU
 SG_ VFCVectorZCUDMVFCid25 : 27|1@0+ (1,0) [0|1] "" IHU
 SG_ VFCVectorZCUDMVFCid26 : 28|1@0+ (1,0) [0|1] "" IHU
 SG_ VFCVectorZCUDMVFCid27 : 29|1@0+ (1,0) [0|1] "" IHU
 SG_ VFCVectorZCUDMVFCid28 : 30|1@0+ (1,0) [0|1] "" IHU
 SG_ VFCVectorZCUDMVFCid29 : 31|1@0+ (1,0) [0|1] "" IHU
 SG_ VFCVectorZCUDMVFCid3 : 5|1@0+ (1,0) [0|1] "" IHU
 SG_ VFCVectorZCUDMVFCid30 : 32|1@0+ (1,0) [0|1] "" IHU
 SG_ VFCVectorZCUDMVFCid31 : 33|1@0+ (1,0) [0|1] "" IHU
 SG_ VFCVectorZCUDMVFCid32 : 34|1@0+ (1,0) [0|1] "" IHU
 SG_ VFCVectorZCUDMVFCid33 : 35|1@0+ (1,0) [0|1] "" IHU
 SG_ VFCVectorZCUDMVFCid34 : 36|1@0+ (1,0) [0|1] "" IHU
 SG_ VFCVectorZCUDMVFCid35 : 37|1@0+ (1,0) [0|1] "" IHU
 SG_ VFCVectorZCUDMVFCid36 : 38|1@0+ (1,0) [0|1] "" IHU
 SG_ VFCVectorZCUDMVFCid37 : 39|1@0+ (1,0) [0|1] "" IHU
 SG_ VFCVectorZCUDMVFCid38 : 40|1@0+ (1,0) [0|1] "" IHU
 SG_ VFCVectorZCUDMVFCid39 : 41|1@0+ (1,0) [0|1] "" IHU
 SG_ VFCVectorZCUDMVFCid4 : 6|1@0+ (1,0) [0|1] "" IHU
 SG_ VFCVectorZCUDMVFCid40 : 42|1@0+ (1,0) [0|1] "" IHU
 SG_ VFCVectorZCUDMVFCid41 : 43|1@0+ (1,0) [0|1] "" IHU
 SG_ VFCVectorZCUDMVFCid42 : 44|1@0+ (1,0) [0|1] "" IHU
 SG_ VFCVectorZCUDMVFCid43 : 45|1@0+ (1,0) [0|1] "" IHU
 SG_ VFCVectorZCUDMVFCid44 : 46|1@0+ (1,0) [0|1] "" IHU
 SG_ VFCVectorZCUDMVFCid45 : 47|1@0+ (1,0) [0|1] "" IHU
 SG_ VFCVectorZCUDMVFCid46 : 48|1@0+ (1,0) [0|1] "" IHU
 SG_ VFCVectorZCUDMVFCid47 : 49|1@0+ (1,0) [0|1] "" IHU
 SG_ VFCVectorZCUDMVFCid48 : 50|1@0+ (1,0) [0|1] "" IHU
 SG_ VFCVectorZCUDMVFCid49 : 51|1@0+ (1,0) [0|1] "" IHU
 SG_ VFCVectorZCUDMVFCid5 : 7|1@0+ (1,0) [0|1] "" IHU
 SG_ VFCVectorZCUDMVFCid50 : 52|1@0+ (1,0) [0|1] "" IHU
 SG_ VFCVectorZCUDMVFCid51 : 53|1@0+ (1,0) [0|1] "" IHU
 SG_ VFCVectorZCUDMVFCid52 : 54|1@0+ (1,0) [0|1] "" IHU
 SG_ VFCVectorZCUDMVFCid53 : 55|1@0+ (1,0) [0|1] "" IHU
 SG_ VFCVectorZCUDMVFCid54 : 56|1@0+ (1,0) [0|1] "" IHU
 SG_ VFCVectorZCUDMVFCid55 : 57|1@0+ (1,0) [0|1] "" IHU
 SG_ VFCVectorZCUDMVFCid56 : 58|1@0+ (1,0) [0|1] "" IHU
 SG_ VFCVectorZCUDMVFCid57 : 59|1@0+ (1,0) [0|1] "" IHU
 SG_ VFCVectorZCUDMVFCid58 : 60|1@0+ (1,0) [0|1] "" IHU
 SG_ VFCVectorZCUDMVFCid59 : 61|1@0+ (1,0) [0|1] "" IHU
 SG_ VFCVectorZCUDMVFCid6 : 8|1@0+ (1,0) [0|1] "" IHU
 SG_ VFCVectorZCUDMVFCid60 : 62|1@0+ (1,0) [0|1] "" IHU
 SG_ VFCVectorZCUDMVFCid61 : 63|1@0+ (1,0) [0|1] "" IHU
 SG_ VFCVectorZCUDMVFCid7 : 9|1@0+ (1,0) [0|1] "" IHU
 SG_ VFCVectorZCUDMVFCid8 : 10|1@0+ (1,0) [0|1] "" IHU
 SG_ VFCVectorZCUDMVFCid9 : 11|1@0+ (1,0) [0|1] "" IHU

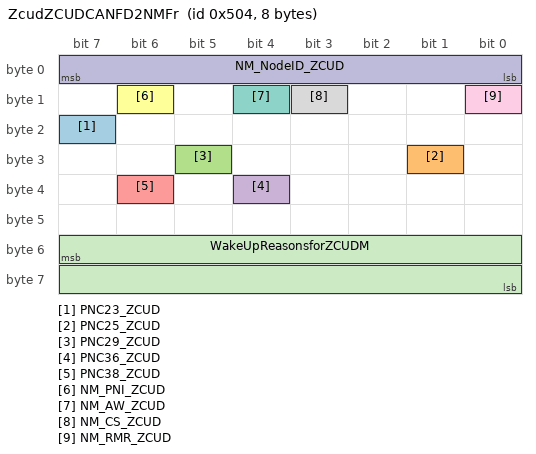
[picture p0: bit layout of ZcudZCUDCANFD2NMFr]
BO_ 1284 ZcudZCUDCANFD2NMFr : 8 ZCUD
 SG_ PNC23_ZCUD : 23|1@0+ (1,0) [0|0] "" Vector__XXX
 SG_ PNC25_ZCUD : 25|1@0+ (1,0) [0|0] "" Vector__XXX
 SG_ PNC29_ZCUD : 29|1@0+ (1,0) [0|0] "" Vector__XXX
 SG_ PNC36_ZCUD : 36|1@0+ (1,0) [0|0] "" Vector__XXX
 SG_ PNC38_ZCUD : 38|1@0+ (1,0) [0|0] "" Vector__XXX
 SG_ NM_PNI_ZCUD : 14|1@0+ (1,0) [0|0] "" Vector__XXX
 SG_ NM_AW_ZCUD : 12|1@0+ (1,0) [0|0] "" Vector__XXX
 SG_ NM_CS_ZCUD : 11|1@0+ (1,0) [0|0] "" Vector__XXX
 SG_ NM_RMR_ZCUD : 8|1@0+ (1,0) [0|0] "" Vector__XXX
 SG_ NM_NodeID_ZCUD : 7|8@0+ (1,0) [0|0] "" Vector__XXX

 SG_ WakeUpReasonsforZCUDM : 55|16@0+ (1,0) [0|65535] "" Vector__XXX

BO_ 1569 ZcudZcudsToDhuZCUCANFD2DiagResFr : 64 ZCUD

BO_ 1538 ZcupToDhuZCUCANFD2DiagResFr : 64 ZCUP

BO_ 1379 ZCUPZCUCANFD2DEVFr01 : 64 ZCUP
 SG_ ZCUPdevelpsignalgroupResp_UB : 504|1@0+ (1,0) [0|1] "" ETC
 SG_ ZCUPdevelpsignalgroupRespFunctiondevpsignalgroup1 : 7|8@0+ (1.0,0.0) [0.0|255.0] "Unitless" ETC
 SG_ ZCUPdevelpsignalgroupRespFunctiondevpsignalgroup2 : 15|8@0+ (1.0,0.0) [0.0|255.0] "Unitless" ETC
 SG_ ZCUPdevelpsignalgroupRespFunctiondevpsignalgroup3 : 23|8@0+ (1.0,0.0) [0.0|255.0] "Unitless" ETC
 SG_ ZCUPdevelpsignalgroupRespFunctiondevpsignalgroup4 : 31|8@0+ (1.0,0.0) [0.0|255.0] "Unitless" ETC
 SG_ ZCUPdevelpsignalgroupRespFunctiondevpsignalgroup5 : 39|8@0+ (1.0,0.0) [0.0|255.0] "Unitless" ETC
 SG_ ZCUPdevelpsignalgroupRespFunctiondevpsignalgroup6 : 47|8@0+ (1.0,0.0) [0.0|255.0] "Unitless" ETC
 SG_ ZCUPdevelpsignalgroupRespFunctiondevpsignalgroup7 : 55|8@0+ (1.0,0.0) [0.0|255.0] "Unitless" ETC
 SG_ ZCUPdevelpsignalgroupRespFunctiondevpsignalgroup8 : 63|8@0+ (1.0,0.0) [0.0|255.0] "Unitless" ETC

CM_ SG_ 427 ActnOfHiBeamDrv "Activate high beam of driver side";
CM_ SG_ 427 ActnOfLedPosnLamp "Activate LED Position Lamp.";
CM_ SG_ 427 ActnOfLedStopLampActnOfLedStopLamp "Activation of Stop Lamps by HCM";
CM_ SG_ 427 ActnOfLedStopLampChks "Stop Lamps Check Sum ASIL B";
CM_ SG_ 427 ActnOfLedStopLampCntr "Stop Lamps Counter ASIL B";
CM_ SG_ 427 ActnOfLoBeamDrvChks "Low Beam Check Sum ASIL B";
CM_ SG_ 427 ActnOfLoBeamDrvCntr "Low Beam Counter ASIL B";
CM_ SG_ 427 ActnOfLoBeamDrvOnOff "Activation of Low Beam function";
CM_ SG_ 427 ActnOfStopLampDrv "Activate stop Lamp of driver side";
CM_ SG_ 427 ActnOfStopLampPass "Activate stop Lamp of passenger side";
CM_ SG_ 427 ActvnOfAhbc "Activate Auto High Beam Control.";
CM_ SG_ 427 ActvnOfRvsg "Activation of Reverse Light";
CM_ SG_ 427 AntithftActvnReq "Set to On when all retries to get a valid mobilisation of target 1 (ECM-node) have failed.";
CM_ SG_ 427 BattLoStsKey0 "Battery Low warning information per key (battery OK, battery low, No new info).";
CM_ SG_ 427 BattLoStsKey1 "Battery Low warning information per key (battery OK, battery low, No new info).";
CM_ SG_ 427 BattLoStsKey10 "Battery Low warning information per key (battery OK, battery low, No new info).";
CM_ SG_ 427 BattLoStsKey11 "Battery Low warning information per key (battery OK, battery low, No new info).";
CM_ SG_ 427 BattLoStsKey2 "Battery Low warning information per key (battery OK, battery low, No new info).";
CM_ SG_ 427 BattLoStsKey3 "Battery Low warning information per key (battery OK, battery low, No new info).";
CM_ SG_ 427 BattLoStsKey4 "Battery Low warning information per key (battery OK, battery low, No new info).";
CM_ SG_ 427 BattLoStsKey5 "Battery Low warning information per key (battery OK, battery low, No new info).";
CM_ SG_ 427 BattLoStsKey6 "Battery Low warning information per key (battery OK, battery low, No new info).";
CM_ SG_ 427 BattLoStsKey7 "Battery Low warning information per key (battery OK, battery low, No new info).";
CM_ SG_ 427 BattLoStsKey8 "Battery Low warning information per key (battery OK, battery low, No new info).";
CM_ SG_ 427 BattLoStsKey9 "Battery Low warning information per key (battery OK, battery low, No new info).";
CM_ SG_ 427 BexvStsExvActrPosn "Bexv actual position";
CM_ SG_ 427 BexvStsExvBlkErr "Bexv blocked error";
CM_ SG_ 427 BexvStsExvCalibSts "Bexv calibration status.";
CM_ SG_ 427 BexvStsExvElecStsErr "Bexv electrical error";
CM_ SG_ 427 BexvStsExvMovSts "Bexv move status.";
CM_ SG_ 427 BexvStsExvOvrTempErr "Bexv over-temp error";
CM_ SG_ 427 BexvStsExvOvrTrvlErr "Bexv over-travel error";
CM_ SG_ 427 BexvStsExvPreHeatgSts "Bexv pre-heating status.";
CM_ SG_ 427 BexvStsExvVoltgRangErr "Bexv voltage range error";
CM_ SG_ 427 BLEKeyBtnTrStsAndKeyIdBLEBtnSts "button pressed status";
CM_ SG_ 427 BLEKeyBtnTrStsAndKeyIdKeyId3 "key id";
CM_ SG_ 427 BLEKeyReadStsToKeyRmnWrnKey0 "key read status";
CM_ SG_ 427 BLEKeyReadStsToKeyRmnWrnKey1 "key read status";
CM_ SG_ 427 BLEKeyReadStsToKeyRmnWrnKey10 "key read status";
CM_ SG_ 427 BLEKeyReadStsToKeyRmnWrnKey11 "key read status";
CM_ SG_ 427 BLEKeyReadStsToKeyRmnWrnKey12 "key read status";
CM_ SG_ 427 BLEKeyReadStsToKeyRmnWrnKey13 "key read status";
CM_ SG_ 427 BLEKeyReadStsToKeyRmnWrnKey14 "key read status";
CM_ SG_ 427 BLEKeyReadStsToKeyRmnWrnKey15 "key read status";
CM_ SG_ 427 BLEKeyReadStsToKeyRmnWrnKey2 "key read status";
CM_ SG_ 427 BLEKeyReadStsToKeyRmnWrnKey3 "key read status";
CM_ SG_ 427 BLEKeyReadStsToKeyRmnWrnKey4 "key read status";
CM_ SG_ 427 BLEKeyReadStsToKeyRmnWrnKey5 "key read status";
CM_ SG_ 427 BLEKeyReadStsToKeyRmnWrnKey6 "key read status";
CM_ SG_ 427 BLEKeyReadStsToKeyRmnWrnKey7 "key read status";
CM_ SG_ 427 BLEKeyReadStsToKeyRmnWrnKey8 "key read status";
CM_ SG_ 427 BLEKeyReadStsToKeyRmnWrnKey9 "key read status";
CM_ SG_ 427 BLEKeyReadStsToVMMKey0 "key0 read status";
CM_ SG_ 427 BLEKeyReadStsToVMMKey1 "key1 read status";
CM_ SG_ 427 BLEKeyReadStsToVMMKey10 "key10 read status";
CM_ SG_ 427 BLEKeyReadStsToVMMKey11 "key11 read status";
CM_ SG_ 427 BLEKeyReadStsToVMMKey12 "key12 read status";
CM_ SG_ 427 BLEKeyReadStsToVMMKey13 "key13 read status";
CM_ SG_ 427 BLEKeyReadStsToVMMKey14 "key14 read status";
CM_ SG_ 427 BLEKeyReadStsToVMMKey15 "key15 read status";
CM_ SG_ 427 BLEKeyReadStsToVMMKey2 "key2 read status";
CM_ SG_ 427 BLEKeyReadStsToVMMKey3 "key3 read status";
CM_ SG_ 427 BLEKeyReadStsToVMMKey4 "key4 read status";
CM_ SG_ 427 BLEKeyReadStsToVMMKey5 "key5 read status";
CM_ SG_ 427 BLEKeyReadStsToVMMKey6 "key6 read status";
CM_ SG_ 427 BLEKeyReadStsToVMMKey7 "key7 read status";
CM_ SG_ 427 BLEKeyReadStsToVMMKey8 "key8 read status";
CM_ SG_ 427 BLEKeyReadStsToVMMKey9 "key9 read status";
CM_ SG_ 427 BtnErsReq "Request Engine Remote Start from the Remote. Idle (ErsCmdNotSet), Start request (ErsCmdOn) and Stop request (ErsCmdOff). Some Logic is placed in the key, and the RF telegram holds the request for Start or Stop.";
CM_ SG_ 427 BtnTrSts "Trunk button on the remote (pressed - not pressed)";
CM_ SG_ 427 CarLoctrAcoustReq "Request from Car Locator to Sound Signaling to sound the vehicle horn when vehicle search is active.";
CM_ SG_ 427 CarLoctrAcoustSts "Inform theft protaction if the acoustic request was successful or not.";
CM_ SG_ 427 CarLoctrExtrLiSts "Car Locator Extr Light Status";
CM_ SG_ 427 ChrgHndlStrtEna "This data element is written by HV system to indicate a charge request to UsgModMgr.";
CM_ SG_ 427 VoltKL15 "Controller ignition status";
CM_ SG_ 427 WrcActvFlg "WRC Active Flag";
CM_ SG_ 427 XcuAccPadAnVolt "Acc_Pad Voltage";
CM_ SG_ 427 XcuAccPwmDuty "Acc_Pwm_Duty";
CM_ SG_ 427 XcuCemWakupVolt "CEM_Wakeup Voltage";
CM_ SG_ 427 XcuChargeNVolt "Charge_N Voltage";
CM_ SG_ 427 XcuChargePVolt "Charge_P Voltage";
CM_ SG_ 427 XcuCpuLoadAvgVal "CpuLoad average value";
CM_ SG_ 427 XcuCpuLoadMaxVal "CpuLoad Max value";
CM_ SG_ 427 XcuCpuLoadMinVal "CpuLoad Min value";
CM_ SG_ 427 XcuDcWakupVolt "DC_Wakeup Voltage";
CM_ SG_ 427 XcuDiagEnblSts "XcuDiagEnblSts";
CM_ SG_ 427 XcuDseWtTqPropFrnt "Actual front axle propulsion torque";
CM_ SG_ 427 XcuDseWtTqPropRear "Actual Propuslion Torque on rear wheels";
CM_ SG_ 427 XcuHvilDuty "HVIL Duty";
CM_ SG_ 427 XcuLvBatt3Volt "LvBatt3 Voltage";
CM_ SG_ 427 XcuPtSnr5v "PTSnr_5V power supply";
CM_ SG_ 427 XcuPwmFanDuty "Pwm Fan Duty";
CM_ SG_ 427 XcuReslovSplyVolt "Resolver Supply voltage";
CM_ SG_ 427 XcuSfCEstWhTqFrntBrkTq "Front wheel brake torque for function safety";
CM_ SG_ 427 XcuSfCEstWhTqFrntPropTq "Front wheel propulsive torque for function safety";
CM_ SG_ 427 XcuSfCEstWhTqReBrkTq "Rear wheel brake torque for function safety";
CM_ SG_ 427 XcuSfCEstWhTqRePropTq "Rear wheel propulsive torque for function safety";
CM_ SG_ 427 XCUTempXcuMcuTemp "MCU Temperature";
CM_ SG_ 427 XCUTempXcuPcbTemp "PCB Temperature";
CM_ SG_ 427 XcuVcc5vLsd "VCC5V_Lsd power supply";
CM_ SG_ 427 XcuVcc5VSnr "VCC5V_Sensor1 power supply";
CM_ SG_ 427 XcuVqco5vT35584 "5V power supply";
CM_ SG_ 427 XcuVqt15vT35584 "5V power supply";
CM_ SG_ 427 XcuVqt25vT35584 "5V power supply";
CM_ SG_ 427 XcuVquc5vT35584 "5V power supply";
CM_ SG_ 427 XcuVqvr5vT35584 "5V power supply";
CM_ SG_ 427 XcuWakeupReqSrc "Wakeup request source";
CM_ SG_ 922 BtnStsOHCIntrLiSwtAllOnSts " All On Switch status";
CM_ SG_ 922 BtnStsOHCIntrLiSwtAutOnSts " Auto On button status";
CM_ SG_ 922 BtnStsOHCLiBtnReadingLe " Left reading light button status";
CM_ SG_ 922 BtnStsOHCLiBtnReadingRi " Right reading light button status";
CM_ SG_ 922 BtnStsOHCRLiBtnReadingLe " Left reading light button status";
CM_ SG_ 922 BtnStsOHCRLiBtnReadingRi " Right reading light button status";
CM_ SG_ 922 BtnStsOHTRLiBtnReadingLe " Left reading light button status";
CM_ SG_ 922 BtnStsOHTRLiBtnReadingRi " Right reading light button status";
CM_ SG_ 922 IntLightDrvSideDoorSupply "PWM control status signal of Driver Side step lights illumination .";
CM_ SG_ 922 IntLightDrvSideSupply "PWM control status signal of Driver (Front and Rear)Side step lights illumination .";
CM_ SG_ 922 IntLightFootwellSupply "PWM control status signal of single-color Lamps illumination in Footwell.
";
CM_ SG_ 922 IntLightLuggageSupply "PWM control status signal of Luggage Illumination.";
CM_ SG_ 922 IntLightReDrvDoorSupply "PWM control status signal of Driver Side rear door step lights illumination .";
CM_ SG_ 922 IntLightReDrvSideSupply "PWM control status signal of Driver Rear Side step lights illumination .";
CM_ SG_ 922 IntrLiCmdGroupIntrLiActvn "Signalgroup that contains the signals IntrLiActvn, IntrLiRoofDim and IntrLiDmdOff. Which tells the interior lighting when and how to dim (speed) and when to force the illumination to go off.";
CM_ SG_ 922 IntrLiCmdGroupIntrLiRoofDim "Signalgroup that contains the signals IntrLiActvn, IntrLiRoofDim and IntrLiDmdOff. Which tells the interior lighting when and how to dim (speed) and when to force the illumination to go off.";
CM_ SG_ 922 IntrLiCmdGroupIntrLiRoofDmdOff "Signalgroup that contains the signals IntrLiActvn, IntrLiRoofDim and IntrLiDmdOff. Which tells the interior lighting when and how to dim (speed) and when to force the illumination to go off.";
CM_ SG_ 922 IntrMirrRespIntrMirrDimPerc "Response signals from IRMM (slave) to CEM (master). Dec 0 = 0 % (Mirror not dimmed), Dec 255 = 100 % (Mirror fully dimmed)";
CM_ SG_ 922 IntrMirrRespIntrMirrIntFailr "Response signals from IRMM (slave) to CEM (master). Internal failure: 0 = No fault, 1 = Internal failure";
CM_ SG_ 922 IntrMirrRespResdBoolean "Response signals from IRMM (slave) to CEM (master). Reserved for future use";
CM_ SG_ 922 IntrMirrRespResdUInt6 "Response signals from IRMM (slave) to CEM (master). Reserved for future use";
CM_ SG_ 922 LiLvrDiagc "Signal used for diagnostic - to make sure that light stalk is connected to SWM.
0-Lever not connected, 1-Lever button stuck, 2-Lever switch undefined(impossible combinations), 3-Lvr OK";
CM_ SG_ 922 OHCFrBtnErrStsIntrLiSwtAllOnSts "OHC All On Button Error";
CM_ SG_ 922 OHCFrBtnErrStsIntrLiSwtAutOnSts "OHC Auto On Button Error";
CM_ SG_ 922 OHCFrBtnErrStsLiBtnReadingLe "OHC Front Left Button Error";
CM_ SG_ 922 OHCFrBtnErrStsLiBtnReadingRi "OHC Front Right Button Error";
CM_ SG_ 922 OHCSecRowBtnErrStsLiBtnReadingLe "OHC Second Row Left Button Error";
CM_ SG_ 922 OHCSecRowBtnErrStsLiBtnReadingRi "OHC Second Row Right Button Error";
CM_ SG_ 922 OHCThirdRowBtnErrStsLiBtnReadingLe "OHC Third Row Left Button Error";
CM_ SG_ 922 OHCThirdRowBtnErrStsLiBtnReadingRi "OHC Third Row Right Button Error";
CM_ SG_ 922 RainSnsrDiagcRainSnsrHiTDetd " High temperature detected";
CM_ SG_ 922 RainSnsrDiagcRainSnsrHiVoltDetd " High voltage detected";
CM_ SG_ 922 RainSnsrErrCalErr "Rain Sensor Error.";
CM_ SG_ 922 RainSnsrErrCalErrActv "Rain Sensor Error.";
CM_ SG_ 922 RainSnsrErrRainDetnErr "Rain Sensor Error.";
CM_ SG_ 922 RainSnsrErrRainDetnErrActv "Rain Sensor Error.";
CM_ SG_ 922 ReadLiErrStsReadLiStsFirstRowLe "Frist Row Left reading light error";
CM_ SG_ 922 ReadLiErrStsReadLiStsFirstRowRi "Frist Row Right reading light error";
CM_ SG_ 922 ReadLiErrStsReadLiStsSecondRowLe "Second Row Left reading light error";
CM_ SG_ 922 ReadLiErrStsReadLiStsSecondRowRi "Second Row Right reading light error";
CM_ SG_ 922 ReadLiErrStsReadLiStsThirdRowLe "Third Row Left reading light error";
CM_ SG_ 922 ReadLiErrStsReadLiStsThirdRowRi "Third Row Right reading light error";
CM_ SG_ 922 ReadLiIntensityValZone1 "It indicates the intensity value of zone1 reading light";
CM_ SG_ 922 ReadLiIntensityValZone2 "It indicates the intensity value of zone2 reading light";
CM_ SG_ 922 ReadLiIntensityValZone3 "It indicates the intensity value of zone3 reading light";
CM_ SG_ 922 ReadLiIntensityValZone4 "It indicates the intensity value of zone4 reading light";
CM_ SG_ 922 ReadLiIntensityValZone5 "It indicates the intensity value of zone5 reading light";
CM_ SG_ 922 ReadLiIntensityValZone6 "It indicates the intensity value of zone6 reading light";
CM_ SG_ 922 StsOfLogoFolwLoBeam "status of logo light lit follow low beam";
CM_ SG_ 922 WipgAutFrntMod "Information regarding rain sensor operational mode.";
CM_ SG_ 922 WiprLvrDiagc "Signal used for diagnostic - to make sure that wiper stalk is connected to SWM.
0-Lever not connected, 1-Lever button stuck, 2-Lever switch undefined(impossible combinations), 3-Lvr OK";
CM_ SG_ 1264 BswAppVersion "Software version number

";
CM_ SG_ 1264 BswCalVersion "Calibration version number

";
CM_ SG_ 1264 BswRervedSignal "Bottom reserved signal

";
CM_ SG_ 1264 VcEvFehMsgRedPerf "Monitoring of Fault Information in Power Restricted High Voltage Systems

";
CM_ SG_ 431 CarLoctrReq "Car locator request from remote key. 0 Car locator not requested. 1 Activate Car locator. 2 Cancel Car locator. 3 Not used";
CM_ SG_ 431 CmprSpdIncrReq "Compressor Speed Increasing Request";
CM_ SG_ 431 DecUsgModAut "This signal is a request from subsystem Locking to subsystem VMM to decrease usage mode.
This request is made when user requests central locking of the vehicle and usage mode conditions for central locking are not fulfilled.
TRUE means that a request is currently made. Default value is FALSE.";
CM_ SG_ 431 DecUsgModAut2 "This signal is a request from subsystem Locking to subsystem VMM to decrease usage mode.(Only when approach lock can use this signal)
This request is made when user requests central locking of the vehicle and usage mode conditions for central locking are not fulfilled.
TRUE means that a request is currently made. Default value is FALSE.";
CM_ SG_ 431 DigKeyIntrVldDetd "Valid digital key internal vehicle detected.";
CM_ SG_ 431 DlyClsReq "request to close tailgate";
CM_ SG_ 431 DoorDrvrAcsKeylsReq "Request signal for passive locking and unlocking, read from driver door capacitive door handle.";
CM_ SG_ 431 DoorDrvrAcsKeylsSts "Status signal for pressed and not pressed, read from driver door capacitive flush door handle.";
CM_ SG_ 431 DoorDrvrHndlCmd "Shall send command to operate the deployable driver door handle according to
DoorDrvrHndlCmd
- Idle
- Deploy
- Retract";
CM_ SG_ 431 DoorDrvrOpenLowReqOutdSwt1 "DoorDrvrOpenLowReqOutdSwt1 - Driver Door Open Request from Outside Switch 1 - Traditional door (No Power operated). Button status of the outside driver door handle switch connection 1.
Psd - Pressed
NotPsd - Not Pressed
NoInfo1/2 - Invalid";
CM_ SG_ 431 DoorDrvrOpenReqInsdSwt1 "DoorDrvrOpenReqInsdSwt1 - Driver Door Open Request from Inside Switch 1
Button status of the inside driver door handle switch connection 1
Psd - Pressed
NotPsd - Not Pressed
NoInfo1/2 - Invalid";
CM_ SG_ 431 DoorDrvrRelsReq "DoorDrvrRelsReq - Driver Door Release Request
Request to release the driver door.
On - Release request
Off - No release request
Invalid1and2 - No release request";
CM_ SG_ 431 DoorLeReAcsKeylsReq "Request signal for passive locking and unlocking, read from driver side rear door capacitive door handle.";
CM_ SG_ 431 DoorLeReAcsKeylsSts "Status signal for pressed and not pressed, read from driver side rear door capacitive flush door handle.";
CM_ SG_ 431 DoorLeReOpenLowReqOutdSwt1 "DoorLeReOpenLowReqOutdSwt1 - Left Rear Door Open Request from Outside Switch 1 - Traditional door (No Power operated). Button status of the outside Left Rear door handle switch connection 1.
Psd - Pressed
NotPsd - Not Pressed
NoInfo1/2 - Invalid";
CM_ SG_ 431 DoorLeReOpenReqInsdSwt1 "DoorDrvrOpenReqInsdSwt1 - Left Rear Door Open Request from Inside Switch 1
Button status of the inside left rear door handle switch connection 1
Psd - Pressed
NotPsd - Not Pressed
NoInfo1/2 - Invalid";
CM_ SG_ 431 DoorPassAcsKeylsReq "Request signal for passive locking and unlocking, read from passenger door capacitive door handle.";
CM_ SG_ 431 DoorPassAcsKeylsSts "Status signal for pressed and not pressed, read from passenger door capacitive flush door handle.";
CM_ SG_ 431 DoorRiReAcsKeylsReq "Request signal for passive locking and unlocking, read from passenger side rear door capacitive door handle.";
CM_ SG_ 431 DoorRiReAcsKeylsSts "Status signal for pressed and not pressed, read from passenger side rear door capacitive flush door handle.";
CM_ SG_ 431 DrvrIntrLockSngSwt "Driver side interior central lock single button switch ";
CM_ SG_ 431 EasyInOutDrvrReq "Easy in out request";
CM_ SG_ 431 EngActvnMod1WdReq "Wake up signal sent to ECM";
CM_ SG_ 431 ErsLockReqByKey "Lock Request, by Engine remote start.
Logic in key gives that Engine Remote Start, can only be requested if lock button is pressed before.
Longer range on the Engine Remote Start message can result in only ERS start message is received (not lock request),
then Lock will be requested from RemInfo, if Engine Remote Start is requested without any Lock request.";
CM_ SG_ 431 FacQlyForDoorDrvrSts "Driver door status quality factor is set according to diagnosis.";
CM_ SG_ 431 FbOfPrkgLiShow "feedback to DHU which the status of Parking light show";
CM_ SG_ 431 GlvBoxIntrSwtSts "GlvBoxIntrSwtSts - Glove Box Interior Switch Status

Button status of the interior glove box opening switch:

Psd - Pressed
NotPsd - Not Pressed";
CM_ SG_ 431 GrlAutoCalibReq "AGM Automatic calibration request.";
CM_ SG_ 431 GrlHldTrqActive "AGM hold torque active.";
CM_ SG_ 431 GrlShttrDmdShttrCalEna "AGM shutter calculation enable";
CM_ SG_ 431 GrlShttrDmdShttrPosnReq "AGM shutter position request";
CM_ SG_ 431 GrlShttrMoveActive "Grill shutter move active.";
CM_ SG_ 431 GrlShttrStsShttrActrFlt "Indicate malfunctioning mechanical coupling between actuator and grill shutter vanes";
CM_ SG_ 431 GrlShttrStsShttrBlkd "Grill shutter actuator stuck";
CM_ SG_ 431 GrlShttrStsShttrCalActv "Grill shutter actuator end stop adaptation is ongoing";
CM_ SG_ 431 GrlShttrStsShttrCalIndcd "Indicate grill shutter actuator end stop adaptation necessary";
CM_ SG_ 431 GrlShttrStsShttrElecErr "Grill shutter actuator internal electrical fault";
CM_ SG_ 431 GrlShttrStsShttrPosnRaw "Current position of grill shutter actuator. ";
CM_ SG_ 431 GrlShttrStsShttrSnsrFlt "Grill shutter position sensor fault";
CM_ SG_ 431 GrlShttrStsShttrTErr "Grill shutter actuator over temperature";
CM_ SG_ 431 GrlShttrStsShttrULoErr "Grill shutter actuator supply voltage too low/high for movement";
CM_ SG_ 431 HoodSwt1 "Primary Hood Switch information.";
CM_ SG_ 431 KeyDiReqKey0 "Request key disabling, per key (On - disable, Off - not disabled)";
CM_ SG_ 431 KeyDiReqKey1 "Request key disabling, per key (On - disable, Off - not disabled)";
CM_ SG_ 431 KeyDiReqKey10 "Request key disabling, per key (On - disable, Off - not disabled)";
CM_ SG_ 431 KeyDiReqKey11 "Request key disabling, per key (On - disable, Off - not disabled)";
CM_ SG_ 431 KeyDiReqKey2 "Request key disabling, per key (On - disable, Off - not disabled)";
CM_ SG_ 431 KeyDiReqKey3 "Request key disabling, per key (On - disable, Off - not disabled)";
CM_ SG_ 431 KeyDiReqKey4 "Request key disabling, per key (On - disable, Off - not disabled)";
CM_ SG_ 431 KeyDiReqKey5 "Request key disabling, per key (On - disable, Off - not disabled)";
CM_ SG_ 431 KeyDiReqKey6 "Request key disabling, per key (On - disable, Off - not disabled)";
CM_ SG_ 431 KeyDiReqKey7 "Request key disabling, per key (On - disable, Off - not disabled)";
CM_ SG_ 431 KeyDiReqKey8 "Request key disabling, per key (On - disable, Off - not disabled)";
CM_ SG_ 431 KeyDiReqKey9 "Request key disabling, per key (On - disable, Off - not disabled)";
CM_ SG_ 431 KeyReadReqFromKeyRmn "Key search request from the Key Reminder function. Search is requested by location (Idle needed between each search). ";
CM_ SG_ 431 KeyReadReqFromKeyWarn "Key search request from the Key Warning function. Search is requested by location (Idle needed between each search). ";
CM_ SG_ 431 KeyReadStsToKeyRmnKey0 "Key search answer back to the Key Reminder function, per key ID.

KeyPrsntStsIdle - Idle (default value)
KeyPrsntStsInProgs - Search in progress
KeyPrsntStsNotPsnt - Key not present/found
KeyPrsntStsPrsnt - Key present/found";
CM_ SG_ 431 KeyReadStsToKeyRmnKey1 "Key search answer back to the Key Reminder function, per key ID.

KeyPrsntStsIdle - Idle (default value)
KeyPrsntStsInProgs - Search in progress
KeyPrsntStsNotPsnt - Key not present/found
KeyPrsntStsPrsnt - Key present/found";
CM_ SG_ 431 KeyReadStsToKeyRmnKey10 "Key search answer back to the Key Reminder function, per key ID.

KeyPrsntStsIdle - Idle (default value)
KeyPrsntStsInProgs - Search in progress
KeyPrsntStsNotPsnt - Key not present/found
KeyPrsntStsPrsnt - Key present/found";
CM_ SG_ 431 KeyReadStsToKeyRmnKey11 "Key search answer back to the Key Reminder function, per key ID.

KeyPrsntStsIdle - Idle (default value)
KeyPrsntStsInProgs - Search in progress
KeyPrsntStsNotPsnt - Key not present/found
KeyPrsntStsPrsnt - Key present/found";
CM_ SG_ 431 KeyReadStsToKeyRmnKey2 "Key search answer back to the Key Reminder function, per key ID.

KeyPrsntStsIdle - Idle (default value)
KeyPrsntStsInProgs - Search in progress
KeyPrsntStsNotPsnt - Key not present/found
KeyPrsntStsPrsnt - Key present/found";
CM_ SG_ 431 KeyReadStsToKeyRmnKey3 "Key search answer back to the Key Reminder function, per key ID.

KeyPrsntStsIdle - Idle (default value)
KeyPrsntStsInProgs - Search in progress
KeyPrsntStsNotPsnt - Key not present/found
KeyPrsntStsPrsnt - Key present/found";
CM_ SG_ 431 KeyReadStsToKeyRmnKey4 "Key search answer back to the Key Reminder function, per key ID.

KeyPrsntStsIdle - Idle (default value)
KeyPrsntStsInProgs - Search in progress
KeyPrsntStsNotPsnt - Key not present/found
KeyPrsntStsPrsnt - Key present/found";
CM_ SG_ 431 KeyReadStsToKeyRmnKey5 "Key search answer back to the Key Reminder function, per key ID.

KeyPrsntStsIdle - Idle (default value)
KeyPrsntStsInProgs - Search in progress
KeyPrsntStsNotPsnt - Key not present/found
KeyPrsntStsPrsnt - Key present/found";
CM_ SG_ 431 KeyReadStsToKeyRmnKey6 "Key search answer back to the Key Reminder function, per key ID.

KeyPrsntStsIdle - Idle (default value)
KeyPrsntStsInProgs - Search in progress
KeyPrsntStsNotPsnt - Key not present/found
KeyPrsntStsPrsnt - Key present/found";
CM_ SG_ 431 KeyReadStsToKeyRmnKey7 "Key search answer back to the Key Reminder function, per key ID.

KeyPrsntStsIdle - Idle (default value)
KeyPrsntStsInProgs - Search in progress
KeyPrsntStsNotPsnt - Key not present/found
KeyPrsntStsPrsnt - Key present/found";
CM_ SG_ 431 KeyReadStsToKeyRmnKey8 "Key search answer back to the Key Reminder function, per key ID.

KeyPrsntStsIdle - Idle (default value)
KeyPrsntStsInProgs - Search in progress
KeyPrsntStsNotPsnt - Key not present/found
KeyPrsntStsPrsnt - Key present/found";
CM_ SG_ 431 KeyReadStsToKeyRmnKey9 "Key search answer back to the Key Reminder function, per key ID.

KeyPrsntStsIdle - Idle (default value)
KeyPrsntStsInProgs - Search in progress
KeyPrsntStsNotPsnt - Key not present/found
KeyPrsntStsPrsnt - Key present/found";
CM_ SG_ 431 KeyReadStsToKeyWarnKey0 "Key search answer back to the Key Warning function, per key ID.

KeyPrsntStsIdle - Idle (default value)
KeyPrsntStsInProgs - Search in progress
KeyPrsntStsNotPsnt - Key not present/found
KeyPrsntStsPrsnt - Key present/found";
CM_ SG_ 431 KeyReadStsToKeyWarnKey1 "Key search answer back to the Key Warning function, per key ID.

KeyPrsntStsIdle - Idle (default value)
KeyPrsntStsInProgs - Search in progress
KeyPrsntStsNotPsnt - Key not present/found
KeyPrsntStsPrsnt - Key present/found";
CM_ SG_ 431 KeyReadStsToKeyWarnKey10 "Key search answer back to the Key Warning function, per key ID.

KeyPrsntStsIdle - Idle (default value)
KeyPrsntStsInProgs - Search in progress
KeyPrsntStsNotPsnt - Key not present/found
KeyPrsntStsPrsnt - Key present/found";
CM_ SG_ 431 KeyReadStsToKeyWarnKey11 "Key search answer back to the Key Warning function, per key ID.

KeyPrsntStsIdle - Idle (default value)
KeyPrsntStsInProgs - Search in progress
KeyPrsntStsNotPsnt - Key not present/found
KeyPrsntStsPrsnt - Key present/found";
CM_ SG_ 431 KeyReadStsToKeyWarnKey2 "Key search answer back to the Key Warning function, per key ID.

KeyPrsntStsIdle - Idle (default value)
KeyPrsntStsInProgs - Search in progress
KeyPrsntStsNotPsnt - Key not present/found
KeyPrsntStsPrsnt - Key present/found";
CM_ SG_ 431 KeyReadStsToKeyWarnKey3 "Key search answer back to the Key Warning function, per key ID.

KeyPrsntStsIdle - Idle (default value)
KeyPrsntStsInProgs - Search in progress
KeyPrsntStsNotPsnt - Key not present/found
KeyPrsntStsPrsnt - Key present/found";
CM_ SG_ 431 KeyReadStsToKeyWarnKey4 "Key search answer back to the Key Warning function, per key ID.

KeyPrsntStsIdle - Idle (default value)
KeyPrsntStsInProgs - Search in progress
KeyPrsntStsNotPsnt - Key not present/found
KeyPrsntStsPrsnt - Key present/found";
CM_ SG_ 431 KeyReadStsToKeyWarnKey5 "Key search answer back to the Key Warning function, per key ID.

KeyPrsntStsIdle - Idle (default value)
KeyPrsntStsInProgs - Search in progress
KeyPrsntStsNotPsnt - Key not present/found
KeyPrsntStsPrsnt - Key present/found";
CM_ SG_ 431 KeyReadStsToKeyWarnKey6 "Key search answer back to the Key Warning function, per key ID.

KeyPrsntStsIdle - Idle (default value)
KeyPrsntStsInProgs - Search in progress
KeyPrsntStsNotPsnt - Key not present/found
KeyPrsntStsPrsnt - Key present/found";
CM_ SG_ 431 KeyReadStsToKeyWarnKey7 "Key search answer back to the Key Warning function, per key ID.

KeyPrsntStsIdle - Idle (default value)
KeyPrsntStsInProgs - Search in progress
KeyPrsntStsNotPsnt - Key not present/found
KeyPrsntStsPrsnt - Key present/found";
CM_ SG_ 431 KeyReadStsToKeyWarnKey8 "Key search answer back to the Key Warning function, per key ID.

KeyPrsntStsIdle - Idle (default value)
KeyPrsntStsInProgs - Search in progress
KeyPrsntStsNotPsnt - Key not present/found
KeyPrsntStsPrsnt - Key present/found";
CM_ SG_ 431 KeyReadStsToKeyWarnKey9 "Key search answer back to the Key Warning function, per key ID.

KeyPrsntStsIdle - Idle (default value)
KeyPrsntStsInProgs - Search in progress
KeyPrsntStsNotPsnt - Key not present/found
KeyPrsntStsPrsnt - Key present/found";
CM_ SG_ 431 KeyReadStsToVmmKey0 "Key search answer back to the VMM Subsystem, per key ID.

KeyPrsntStsIdle - Idle (default value)
KeyPrsntStsInProgs - Search in progress
KeyPrsntStsNotPsnt - Key not present/found
KeyPrsntStsPrsnt - Key present/found";
CM_ SG_ 431 KeyReadStsToVmmKey1 "Key search answer back to the VMM Subsystem, per key ID.

KeyPrsntStsIdle - Idle (default value)
KeyPrsntStsInProgs - Search in progress
KeyPrsntStsNotPsnt - Key not present/found
KeyPrsntStsPrsnt - Key present/found";
CM_ SG_ 431 KeyReadStsToVmmKey10 "Key search answer back to the VMM Subsystem, per key ID.

KeyPrsntStsIdle - Idle (default value)
KeyPrsntStsInProgs - Search in progress
KeyPrsntStsNotPsnt - Key not present/found
KeyPrsntStsPrsnt - Key present/found";
CM_ SG_ 431 KeyReadStsToVmmKey11 "Key search answer back to the VMM Subsystem, per key ID.

KeyPrsntStsIdle - Idle (default value)
KeyPrsntStsInProgs - Search in progress
KeyPrsntStsNotPsnt - Key not present/found
KeyPrsntStsPrsnt - Key present/found";
CM_ SG_ 431 KeyReadStsToVmmKey2 "Key search answer back to the VMM Subsystem, per key ID.

KeyPrsntStsIdle - Idle (default value)
KeyPrsntStsInProgs - Search in progress
KeyPrsntStsNotPsnt - Key not present/found
KeyPrsntStsPrsnt - Key present/found";
CM_ SG_ 431 KeyReadStsToVmmKey3 "Key search answer back to the VMM Subsystem, per key ID.

KeyPrsntStsIdle - Idle (default value)
KeyPrsntStsInProgs - Search in progress
KeyPrsntStsNotPsnt - Key not present/found
KeyPrsntStsPrsnt - Key present/found";
CM_ SG_ 431 KeyReadStsToVmmKey4 "Key search answer back to the VMM Subsystem, per key ID.

KeyPrsntStsIdle - Idle (default value)
KeyPrsntStsInProgs - Search in progress
KeyPrsntStsNotPsnt - Key not present/found
KeyPrsntStsPrsnt - Key present/found";
CM_ SG_ 431 KeyReadStsToVmmKey5 "Key search answer back to the VMM Subsystem, per key ID.

KeyPrsntStsIdle - Idle (default value)
KeyPrsntStsInProgs - Search in progress
KeyPrsntStsNotPsnt - Key not present/found
KeyPrsntStsPrsnt - Key present/found";
CM_ SG_ 431 KeyReadStsToVmmKey6 "Key search answer back to the VMM Subsystem, per key ID.

KeyPrsntStsIdle - Idle (default value)
KeyPrsntStsInProgs - Search in progress
KeyPrsntStsNotPsnt - Key not present/found
KeyPrsntStsPrsnt - Key present/found";
CM_ SG_ 431 KeyReadStsToVmmKey7 "Key search answer back to the VMM Subsystem, per key ID.

KeyPrsntStsIdle - Idle (default value)
KeyPrsntStsInProgs - Search in progress
KeyPrsntStsNotPsnt - Key not present/found
KeyPrsntStsPrsnt - Key present/found";
CM_ SG_ 431 KeyReadStsToVmmKey8 "Key search answer back to the VMM Subsystem, per key ID.

KeyPrsntStsIdle - Idle (default value)
KeyPrsntStsInProgs - Search in progress
KeyPrsntStsNotPsnt - Key not present/found
KeyPrsntStsPrsnt - Key present/found";
CM_ SG_ 431 KeyReadStsToVmmKey9 "Key search answer back to the VMM Subsystem, per key ID.

KeyPrsntStsIdle - Idle (default value)
KeyPrsntStsInProgs - Search in progress
KeyPrsntStsNotPsnt - Key not present/found
KeyPrsntStsPrsnt - Key present/found";
CM_ SG_ 431 KeyReadStsToVMMNFCKey0 "key read status";
CM_ SG_ 431 KeyReadStsToVMMNFCKey1 "key read status";
CM_ SG_ 431 KeyReadStsToVMMNFCKey10 "key read status";
CM_ SG_ 431 KeyReadStsToVMMNFCKey11 "key read status";
CM_ SG_ 431 KeyReadStsToVMMNFCKey12 "key read status";
CM_ SG_ 431 KeyReadStsToVMMNFCKey13 "key read status";
CM_ SG_ 431 KeyReadStsToVMMNFCKey14 "key read status";
CM_ SG_ 431 KeyReadStsToVMMNFCKey15 "key read status";
CM_ SG_ 431 KeyReadStsToVMMNFCKey2 "key read status";
CM_ SG_ 431 KeyReadStsToVMMNFCKey3 "key read status";
CM_ SG_ 431 KeyReadStsToVMMNFCKey4 "key read status";
CM_ SG_ 431 KeyReadStsToVMMNFCKey5 "key read status";
CM_ SG_ 431 KeyReadStsToVMMNFCKey6 "key read status";
CM_ SG_ 431 KeyReadStsToVMMNFCKey7 "key read status";
CM_ SG_ 431 KeyReadStsToVMMNFCKey8 "key read status";
CM_ SG_ 431 KeyReadStsToVMMNFCKey9 "key read status";
CM_ SG_ 431 LiOprnMod "Information about day, night, twilight and tunnel detection.";
CM_ SG_ 431 MobDeBtnCarLctrSts "Mobile Device Car locator button pressed.";
CM_ SG_ 431 MobDeBtnPanicAlarmSts "Panic alarm button status";
CM_ SG_ 431 MobDevAVPReq "Automaic Remote Parking Request sent by telematics";
CM_ SG_ 431 MobDevBtnLockStsAndKeyIdKeyId3 "key id";
CM_ SG_ 431 MobDevBtnLockStsAndKeyIdPsdNotPsd "button pressed status";
CM_ SG_ 431 MobDevBtnTrReq "Trunk button on the Mobile Device.
0:Idle
1:Trunk Unlock/Open
2:Trunk Lock/Close
3:Trunk Stop
4:Trunk Enable";
CM_ SG_ 431 MobDevBtnUnlckStsAndKeyIdKeyId3 "key id";
CM_ SG_ 431 MobDevBtnUnlckStsAndKeyIdPsdNotPsd "button pressed status";
CM_ SG_ 431 MobDevChrgngLidOpnReq "Charge Lid Open request via BLE.";
CM_ SG_ 431 MobDevKeyDiReqKeySts0 "Request digital key disabling, per key (On - disable, Off - not disabled)";
CM_ SG_ 431 MobDevKeyDiReqKeySts1 "Request digital key disabling, per key (On - disable, Off - not disabled)";
CM_ SG_ 431 MobDevKeyDiReqKeySts10 "Request digital key disabling, per key (On - disable, Off - not disabled)";
CM_ SG_ 431 MobDevKeyDiReqKeySts11 "Request digital key disabling, per key (On - disable, Off - not disabled)";
CM_ SG_ 431 MobDevKeyDiReqKeySts12 "Request digital key disabling, per key (On - disable, Off - not disabled)";
CM_ SG_ 431 MobDevKeyDiReqKeySts13 "Request digital key disabling, per key (On - disable, Off - not disabled)";
CM_ SG_ 431 MobDevKeyDiReqKeySts14 "Request digital key disabling, per key (On - disable, Off - not disabled)";
CM_ SG_ 431 MobDevKeyDiReqKeySts15 "Request digital key disabling, per key (On - disable, Off - not disabled)";
CM_ SG_ 431 MobDevKeyDiReqKeySts2 "Request digital key disabling, per key (On - disable, Off - not disabled)";
CM_ SG_ 431 MobDevKeyDiReqKeySts3 "Request digital key disabling, per key (On - disable, Off - not disabled)";
CM_ SG_ 431 MobDevKeyDiReqKeySts4 "Request digital key disabling, per key (On - disable, Off - not disabled)";
CM_ SG_ 431 MobDevKeyDiReqKeySts5 "Request digital key disabling, per key (On - disable, Off - not disabled)";
CM_ SG_ 431 MobDevKeyDiReqKeySts6 "Request digital key disabling, per key (On - disable, Off - not disabled)";
CM_ SG_ 431 MobDevKeyDiReqKeySts7 "Request digital key disabling, per key (On - disable, Off - not disabled)";
CM_ SG_ 431 MobDevKeyDiReqKeySts8 "Request digital key disabling, per key (On - disable, Off - not disabled)";
CM_ SG_ 431 MobDevKeyDiReqKeySts9 "Request digital key disabling, per key (On - disable, Off - not disabled)";
CM_ SG_ 431 MobDevKeyEnaStsKey0 "key enabled status";
CM_ SG_ 431 MobDevKeyEnaStsKey1 "key enabled status";
CM_ SG_ 431 MobDevKeyEnaStsKey10 "key enabled status";
CM_ SG_ 431 MobDevKeyEnaStsKey11 "key enabled status";
CM_ SG_ 431 MobDevKeyEnaStsKey12 "key enabled status";
CM_ SG_ 431 MobDevKeyEnaStsKey13 "key enabled status";
CM_ SG_ 431 MobDevKeyEnaStsKey14 "key enabled status";
CM_ SG_ 431 MobDevKeyEnaStsKey15 "key enabled status";
CM_ SG_ 431 MobDevKeyEnaStsKey2 "key enabled status";
CM_ SG_ 431 MobDevKeyEnaStsKey3 "key enabled status";
CM_ SG_ 431 MobDevKeyEnaStsKey4 "key enabled status";
CM_ SG_ 431 MobDevKeyEnaStsKey5 "key enabled status";
CM_ SG_ 431 MobDevKeyEnaStsKey6 "key enabled status";
CM_ SG_ 431 MobDevKeyEnaStsKey7 "key enabled status";
CM_ SG_ 431 MobDevKeyEnaStsKey8 "key enabled status";
CM_ SG_ 431 MobDevKeyEnaStsKey9 "key enabled status";
CM_ SG_ 431 MobDevOpenClsCmftReq "Open Close Comfort Request by mobile device ";
CM_ SG_ 431 MobDevRoofOpnClsReq "Roof Open Close Request by Mobile Device";
CM_ SG_ 431 MobDevVldUserStsToVMM "Valid user request for Automaic Remote Parking sent by telematics";
CM_ SG_ 431 MobDevWinOpnClsReq "Power Windows Open Close Request by Mobile Device";
CM_ SG_ 431 NFCKeyReadStsToKeyRmnWrnKey0 "key read status";
CM_ SG_ 431 NFCKeyReadStsToKeyRmnWrnKey1 "key read status";
CM_ SG_ 431 NFCKeyReadStsToKeyRmnWrnKey10 "key read status";
CM_ SG_ 431 NFCKeyReadStsToKeyRmnWrnKey11 "key read status";
CM_ SG_ 431 NFCKeyReadStsToKeyRmnWrnKey12 "key read status";
CM_ SG_ 431 NFCKeyReadStsToKeyRmnWrnKey13 "key read status";
CM_ SG_ 431 NFCKeyReadStsToKeyRmnWrnKey14 "key read status";
CM_ SG_ 431 NFCKeyReadStsToKeyRmnWrnKey15 "key read status";
CM_ SG_ 431 NFCKeyReadStsToKeyRmnWrnKey2 "key read status";
CM_ SG_ 431 NFCKeyReadStsToKeyRmnWrnKey3 "key read status";
CM_ SG_ 431 NFCKeyReadStsToKeyRmnWrnKey4 "key read status";
CM_ SG_ 431 NFCKeyReadStsToKeyRmnWrnKey5 "key read status";
CM_ SG_ 431 NFCKeyReadStsToKeyRmnWrnKey6 "key read status";
CM_ SG_ 431 NFCKeyReadStsToKeyRmnWrnKey7 "key read status";
CM_ SG_ 431 NFCKeyReadStsToKeyRmnWrnKey8 "key read status";
CM_ SG_ 431 NFCKeyReadStsToKeyRmnWrnKey9 "key read status";
CM_ SG_ 431 OutdBriChks "Input for controlling lights on and off automatically. Checksum";
CM_ SG_ 431 OutdBriCntr "Input for controlling lights on and off automatically. Counter";
CM_ SG_ 431 OutdBriHwChks "Input for controlling lights on and off automatically. Checksum.";
CM_ SG_ 431 OutdBriHwCntr "Input for controlling lights on and off automatically. Counter.";
CM_ SG_ 431 OutdBriHwOutdBriSts "Input for controlling lights on and off automatically. Status information.";
CM_ SG_ 431 OutdBriSts "Input for controlling lights on and off automatically. Status information.";
CM_ SG_ 431 SteerLockChkSteerLockDataChk0 "Challenge from SCL to CEM Byte 0";
CM_ SG_ 431 SteerLockChkSteerLockDataChk1 "Challenge from SCL to CEM Byte 1";
CM_ SG_ 431 SteerLockChkSteerLockDataChk2 "Challenge from SCL to CEM Byte 2";
CM_ SG_ 431 SteerLockChkSteerLockDataChk3 "Challenge from SCL to CEM Byte 3";
CM_ SG_ 431 SteerLockChkSteerLockDataChk4 "Challenge from SCL to CEM Byte 4";
CM_ SG_ 431 SteerLockChkSteerLockDataChk5 "Challenge from SCL to CEM Byte 5";
CM_ SG_ 431 SteerLockChkSteerLockDataChk6 "Challenge from SCL to CEM Byte 6";
CM_ SG_ 431 SteerLockChkSts "Challenge from SCL to CEM Challenge available";
CM_ SG_ 431 SteerLockReqCommand "Command to lock or unlock SCL and 7 bytes response ";
CM_ SG_ 431 SteerLockReqSteerLockDataReq0 "Command to lock or unlock SCL and 7 bytes response  Byte 0";
CM_ SG_ 431 SteerLockReqSteerLockDataReq1 "Command to lock or unlock SCL and 7 bytes response  Byte 1";
CM_ SG_ 431 SteerLockReqSteerLockDataReq2 "Command to lock or unlock SCL and 7 bytes response  Byte 2";
CM_ SG_ 431 SteerLockReqSteerLockDataReq3 "Command to lock or unlock SCL and 7 bytes response  Byte 3";
CM_ SG_ 431 SteerLockReqSteerLockDataReq4 "Command to lock or unlock SCL and 7 bytes response  Byte 4";
CM_ SG_ 431 SteerLockReqSteerLockDataReq5 "Command to lock or unlock SCL and 7 bytes response  Byte 5";
CM_ SG_ 431 SteerLockReqSteerLockDataReq6 "Command to lock or unlock SCL and 7 bytes response  Byte 6";
CM_ SG_ 431 WinWshrLvrCmd "STALK SWITCH(slider in housing)
Wiper stalk moving PUSH/PULL
Activating front wash when pulling
Activating rear wash when pushing

";
CM_ SG_ 1189 EtpZeroCrc1 "Zero Checksum = Byte0 XOR Byte1";
CM_ SG_ 1189 EtpZeroCrc2 "Zero Checksum = Byte0 XOR Byte1";
CM_ SG_ 1189 EtpZeroCrcEtpZeroCrc "Zero Checksum = Byte0 XOR Byte1";
CM_ SG_ 1189 EtpZeroDegrVal1 "zero degree value ";
CM_ SG_ 1189 EtpZeroDegrVal2 "zero degree value ";
CM_ SG_ 1189 EtpZeroDegrValEtpZeroDegrVal "zero degree value ";
CM_ SG_ 1189 EtpZeroSuccessFlag1 "zero success flag";
CM_ SG_ 1189 EtpZeroSuccessFlag2 "zero success flag";
CM_ SG_ 1189 EtpZeroSuccessFlagEtpZeroSuccessFlag "zero success flag";
CM_ SG_ 1189 SnsrInclnCmd "Sensor command sent by CEM, to arm or disarm inclination sensor.";
CM_ SG_ 1189 SnsrIntrScanCmdAirFanSts "Command to IMS including arm and disarm request, climatisation status, window and roof and suncurtain position and outside temperature.";
CM_ SG_ 1189 SnsrIntrScanCmdArmReq "Command to IMS including arm and disarm request, climatisation status, window and roof and suncurtain position and outside temperature.";
CM_ SG_ 1189 SnsrIntrScanCmdCurtRollUpDwn "Command to IMS including arm and disarm request, climatisation status, window and roof and suncurtain position and outside temperature.";
CM_ SG_ 1189 SnsrIntrScanCmdRoofPosn "Command to IMS including arm and disarm request, climatisation status, window and roof and suncurtain position and outside temperature.";
CM_ SG_ 1189 SnsrIntrScanCmdTemp "Command to IMS including arm and disarm request, climatisation status, window and roof and suncurtain position and outside temperature.";
CM_ SG_ 1189 SnsrIntrScanCmdWinPosn "Command to IMS including arm and disarm request, climatisation status, window and roof and suncurtain position and outside temperature.";
CM_ SG_ 1189 SnsrSoundrBattBackedCmdArmCmd "Command to BBS including arm and disarm request, sound request, charging allowed signal and chirp request.";
CM_ SG_ 1189 SnsrSoundrBattBackedCmdChirpTyp "Command to BBS including arm and disarm request, sound request, charging allowed signal and chirp request.";
CM_ SG_ 1189 SnsrSoundrBattBackedCmdChrgReq "Command to BBS including arm and disarm request, sound request, charging allowed signal and chirp request.";
CM_ SG_ 1189 SnsrSoundrBattBackedCmdSoundReq "Command to BBS including arm and disarm request, sound request, charging allowed signal and chirp request.";
CM_ SG_ 1189 SunRoofAndCurtPosnCmdOpenPerc "What is the target position";
CM_ SG_ 1189 SunRoofAndCurtPosnCmdSel "Should the Roof or the Curtain listen to the percentage commans";
CM_ SG_ 1189 SunRoofEna "Authorize the glass panel to move";
CM_ SG_ 1189 TCSDcdcactvdReq "TCSDcdcactvdReq";
CM_ SG_ 1189 TCSUsgModReq "TCSUsgModReq";
CM_ SG_ 1189 ThirdRowLeReadLiReq "The Third row Left side reading light request with intensity level.";
CM_ SG_ 1189 ThirdRowRiReadLiReq "The Third row right side reading light request with intensity level.";
CM_ SG_ 1189 TrlrLiBrkActvt "Brake Light request for trailer if connected.";
CM_ SG_ 1189 TrlrLiFogActvt "Controls the trailer foglight on and off.";
CM_ SG_ 1189 TrlrLiPosnActvt "Activation of rear position light including rear SML (Side Marker Light).";
CM_ SG_ 1189 TrlrLiRvsgActvt "Activation of reverse light.";
CM_ SG_ 1189 VcEvFehMsgHybridFlt "Monitoring of Fault Information of High Voltage Front High Voltage System on Vehicles

";
CM_ SG_ 1189 VcEvFehMsgStopSafely "Monitoring of High Voltage System Fault Information during Vehicle Operation

";
CM_ SG_ 1189 VcEvFunction21 "Monitoring of Fault Information in Vehicle Charging High Voltage Systems

";
CM_ SG_ 1189 VcEvPowerUpFail "Unable to power on fault information monitoring

";
CM_ SG_ 1189 VcEvPropStartInhibit "Power system unavailable fault information monitoring

";
CM_ SG_ 1189 VcEvSymCC "Cruise fault information monitoring

";
CM_ SG_ 1189 VcEvSymRed "Torque monitoring fault information monitoring

";
CM_ SG_ 1189 VcEvUnexpctClearDCA "Accidental clearing of DCA fault information monitoring

";
CM_ SG_ 1189 VcEvUnexpPowerDown "Accidental high-voltage fault information monitoring

";
CM_ SG_ 1189 WindCorrnValAmb "Three different windscreen correction values used to calibrate the light sensors in the rain sensor for different windscreen types. Windscreen correction value ambient light sensor";
CM_ SG_ 1189 WindCorrnValFrnt "Three different windscreen correction values used to calibrate the light sensors in the rain sensor for different windscreen types. Windscreen correction value front light sensor";
CM_ SG_ 1189 WindCorrnValHud "Three different windscreen correction values used to calibrate the light sensors in the rain sensor for different windscreen types. Windscreen correction value HUD sensor";
CM_ SG_ 1189 WinDsblLeftSts "Signal sent from the rear driver door module to the Driver door module that informs of the local status of the power window disable functionality.
";
CM_ SG_ 1189 WinHwSwtDrvrReDoor "Signal from the driver rear door hardwired switch to the door control modules containing the state of the window switches. ";
CM_ SG_ 1189 WipgPwrActvnNotSafeAcsyMode "Convenience Mode or above (Terminal X)";
CM_ SG_ 1189 WipgPwrActvnNotSafeDrvgMod "Driving Mode (Terminal 15)";
CM_ SG_ 1189 WipgPwrActvnSafeWipgPwrAcsyModSafe "Signals controlling operational mode of the wiper motor. Convenience mode or above (former Terminal X)";
CM_ SG_ 1189 WipgPwrActvnSafeWipgPwrDrvgModSafe "Signals controlling operational mode of the wiper motor. Driving mode (former Terminal 15)";
CM_ SG_ 1189 WiprActvMech "Information regarding if the Mechanical wiper is active or not.";
CM_ SG_ 1189 WiprInPrkgPosnLo "Wiper position on the windscreen. Wiper lever in, below or above extended parking position";
CM_ SG_ 1189 WiprInWipgArMech "Information regarding wiper position on the windscreen.
";
CM_ SG_ 1189 WiprLvrComErrDetd "Wiper Lever Communication Error Detected.";
CM_ SG_ 1189 WiprLvrNodErrDetd "Wiper Lever Node Error Detected.";
CM_ SG_ 1189 WiprMotComErrDetd "Wiper Motor Communication Error Detected.";
CM_ SG_ 1189 WiprMotErr "Sends information if there is a wiper relay detected";
CM_ SG_ 1189 WiprMotErrSafeMech "Wiper Motor Error.";
CM_ SG_ 1189 WiprMotFrntLvrCmdNotSafeLvrInHiSpdPosn "Wiper Lever In High Speed Position";
CM_ SG_ 1189 WiprMotFrntLvrCmdNotSafeLvrInIntlPosn "Stalk in Interval Position";
CM_ SG_ 1189 WiprMotFrntLvrCmdNotSafeLvrInLoSpdPosn "Wiper Lever in Low Speed Position";
CM_ SG_ 1189 WiprMotFrntLvrCmdNotSafeLvrInSnglStrokePos "Wiper level in Single Stroke";
CM_ SG_ 1189 WiprMotFrntOffsAg "Information used to calibrate the upper reversal position of the wiper arm ";
CM_ SG_ 1189 WiprMotIntlCmd "Rain sensor rensitivity ring setting on the wiper stalk as selected by the driver.";
CM_ SG_ 1189 WiprMotNodErrDetd "Wiper Motor Node Error Detected.";
CM_ SG_ 1189 WiprMotRelayMech "Detects if there is a wiper relay installed";
CM_ SG_ 1189 WiprPosnForSrvReq "Request to the wiper motor to raise the wiper arm to a service position";
CM_ SG_ 1189 WiprReInWipgAr "Information regarding rear wiper position.";
CM_ SG_ 1189 WiprWshrMgrErrDetd "Wiper Washer Manager Error Detected.";
CM_ SG_ 1189 WshngCycActv "Off, No front washing cycle active. On, Front washing active (pre-washing, washing or afterwiping)";
CM_ SG_ 1189 WshngCycActvMech "Information regarding front washing cycle active or not.";
CM_ SG_ 1189 WshrFldLvlDetdLo "Internal raw data in CEM with the washer fluid level low detection information.";
CM_ SG_ 1189 WshrHeatgSig "Control the heated nozzles (RMS voltage 0-16V)";
CM_ SG_ 1189 WshrLvrPosnNotSafe "Indicates when front washing is requested so that front wiping will be started by the wiper motor.";
CM_ SG_ 1189 WshrLvrPosnSafe "Washer Lever Position.";
CM_ SG_ 1189 XCUPcodeStatus "XCU internal DTC rotation display";
CM_ SG_ 1348 VFCVectorZCUDMBlockID "BlockID";
CM_ SG_ 1348 VFCVectorZCUDMVFCid0 "SettingsComfort";
CM_ SG_ 1348 VFCVectorZCUDMVFCid1 "ParkingDrivingClimatization";
CM_ SG_ 1348 VFCVectorZCUDMVFCid10 "ExteriorLighting";
CM_ SG_ 1348 VFCVectorZCUDMVFCid11 "VFC11";
CM_ SG_ 1348 VFCVectorZCUDMVFCid12 "Alarm";
CM_ SG_ 1348 VFCVectorZCUDMVFCid13 "VFC13";
CM_ SG_ 1348 VFCVectorZCUDMVFCid14 "InteriorLighting";
CM_ SG_ 1348 VFCVectorZCUDMVFCid15 "VFC15";
CM_ SG_ 1348 VFCVectorZCUDMVFCid16 "Locking";
CM_ SG_ 1348 VFCVectorZCUDMVFCid17 "RemoteKeyFunctionality";
CM_ SG_ 1348 VFCVectorZCUDMVFCid18 "PropulsionStart";
CM_ SG_ 1348 VFCVectorZCUDMVFCid19 "VFC19";
CM_ SG_ 1348 VFCVectorZCUDMVFCid2 "PostClimatisation";
CM_ SG_ 1348 VFCVectorZCUDMVFCid20 "VFC20";
CM_ SG_ 1348 VFCVectorZCUDMVFCid21 "PowerClosures";
CM_ SG_ 1348 VFCVectorZCUDMVFCid22 "VehicleDriving";
CM_ SG_ 1348 VFCVectorZCUDMVFCid23 "VFC23";
CM_ SG_ 1348 VFCVectorZCUDMVFCid24 "SettingsProfile";
CM_ SG_ 1348 VFCVectorZCUDMVFCid25 "SeatComfortFunctions";
CM_ SG_ 1348 VFCVectorZCUDMVFCid26 "Brake";
CM_ SG_ 1348 VFCVectorZCUDMVFCid27 "InfotainmentPoll";
CM_ SG_ 1348 VFCVectorZCUDMVFCid28 "HVEnergyStorage";
CM_ SG_ 1348 VFCVectorZCUDMVFCid29 "VFC29";
CM_ SG_ 1348 VFCVectorZCUDMVFCid3 "PowertrainParkingClimatization";
CM_ SG_ 1348 VFCVectorZCUDMVFCid30 "TelematicsConnectivity";
CM_ SG_ 1348 VFCVectorZCUDMVFCid31 "VFC31";
CM_ SG_ 1348 VFCVectorZCUDMVFCid32 "VFC32";
CM_ SG_ 1348 VFCVectorZCUDMVFCid33 "Diagnostics";
CM_ SG_ 1348 VFCVectorZCUDMVFCid34 "VehicleModeManagement";
CM_ SG_ 1348 VFCVectorZCUDMVFCid35 "TrailerCaravanFunctions";
CM_ SG_ 1348 VFCVectorZCUDMVFCid36 "Immobilizer";
CM_ SG_ 1348 VFCVectorZCUDMVFCid37 "Windows";
CM_ SG_ 1348 VFCVectorZCUDMVFCid38 "Visibility";
CM_ SG_ 1348 VFCVectorZCUDMVFCid39 "VFC39";
CM_ SG_ 1348 VFCVectorZCUDMVFCid4 "VFC4";
CM_ SG_ 1348 VFCVectorZCUDMVFCid40 "VFC40";
CM_ SG_ 1348 VFCVectorZCUDMVFCid41 "InfotainmentPush";
CM_ SG_ 1348 VFCVectorZCUDMVFCid42 "ChargingHV";
CM_ SG_ 1348 VFCVectorZCUDMVFCid43 "BodyPreClimatisation";
CM_ SG_ 1348 VFCVectorZCUDMVFCid44 "Crash";
CM_ SG_ 1348 VFCVectorZCUDMVFCid45 "GlobalShortDuration";
CM_ SG_ 1348 VFCVectorZCUDMVFCid46 "ExteriorLightsHazard";
CM_ SG_ 1348 VFCVectorZCUDMVFCid47 "VFC47";
CM_ SG_ 1348 VFCVectorZCUDMVFCid48 "DoorOpenWarning";
CM_ SG_ 1348 VFCVectorZCUDMVFCid49 "ChargingLVInit";
CM_ SG_ 1348 VFCVectorZCUDMVFCid5 "VFC5";
CM_ SG_ 1348 VFCVectorZCUDMVFCid50 "VFC50";
CM_ SG_ 1348 VFCVectorZCUDMVFCid51 "VFC51";
CM_ SG_ 1348 VFCVectorZCUDMVFCid52 "HVBatteryThermalEventWarning";
CM_ SG_ 1348 VFCVectorZCUDMVFCid53 "VisualAssist";
CM_ SG_ 1348 VFCVectorZCUDMVFCid54 "PassiveSafety";
CM_ SG_ 1348 VFCVectorZCUDMVFCid55 "LifeDetection";
CM_ SG_ 1348 VFCVectorZCUDMVFCid56 "BackboneFlexray";
CM_ SG_ 1348 VFCVectorZCUDMVFCid57 "Functionmarket";
CM_ SG_ 1348 VFCVectorZCUDMVFCid58 "VFCid58";
CM_ SG_ 1348 VFCVectorZCUDMVFCid59 "VFCid59";
CM_ SG_ 1348 VFCVectorZCUDMVFCid6 "SettingsVehicle";
CM_ SG_ 1348 VFCVectorZCUDMVFCid60 "VFCid60";
CM_ SG_ 1348 VFCVectorZCUDMVFCid61 "VFCid61";
CM_ SG_ 1348 VFCVectorZCUDMVFCid7 "VFC7";
CM_ SG_ 1348 VFCVectorZCUDMVFCid8 "VFC8";
CM_ SG_ 1348 VFCVectorZCUDMVFCid9 "IPWakeup";
CM_ SG_ 1284 WakeUpReasonsforZCUDM "WakeUpReasons";
CM_ SG_ 1379 ZCUPdevelpsignalgroupRespFunctiondevpsignalgroup1 "develop signal group";
CM_ SG_ 1379 ZCUPdevelpsignalgroupRespFunctiondevpsignalgroup2 "develop signal group";
CM_ SG_ 1379 ZCUPdevelpsignalgroupRespFunctiondevpsignalgroup3 "develop signal group";
CM_ SG_ 1379 ZCUPdevelpsignalgroupRespFunctiondevpsignalgroup4 "develop signal group";
CM_ SG_ 1379 ZCUPdevelpsignalgroupRespFunctiondevpsignalgroup5 "develop signal group";
CM_ SG_ 1379 ZCUPdevelpsignalgroupRespFunctiondevpsignalgroup6 "develop signal group";
CM_ SG_ 1379 ZCUPdevelpsignalgroupRespFunctiondevpsignalgroup7 "develop signal group";
CM_ SG_ 1379 ZCUPdevelpsignalgroupRespFunctiondevpsignalgroup8 "develop signal group";
BA_DEF_ BO_ "CANFD_BRS" ENUM "0","1";
BA_DEF_ BO_ "GenMsgCycleTime" INT 0 65536;
BA_DEF_ BO_ "GenMsgDelayTime" INT 0 65536;
BA_DEF_ BO_ "GenMsgSendType" ENUM "cyclic", "spontaneous", "not-used", "not-used", "not-used", "cyclicAndSpontaneous", "not-used", "cyclicIfActive", "NoMsgSendType";
BA_DEF_ BO_ "GenMsgStartDelayTime" INT 0 65536;
BA_DEF_ BO_ "VFrameFormat" ENUM "StandardCAN","ExtendedCAN","reserved","J1939PG","reserved","reserved","reserved","reserved","reserved","reserved","reserved","reserved","reserved","reserved","StandardCAN_FD","ExtendedCAN_FD";
BA_DEF_ SG_ "GenSigSendType" ENUM "Cyclic","OnWrite","OnWriteWithRepetition","OnChange","OnChangeWithRepetition","IfActive","IfActiveWithRepetition","NoSigSendType";
BA_DEF_ SG_ "GenSigStartValue" HEX 0 80000000;
BA_DEF_ BO_ "GenMsgILSupport" ENUM "No","Yes";
BA_DEF_ BO_ "NmAsrMessage" ENUM "No","Yes";
BA_DEF_ SG_ "GenSigFuncType" ENUM "NoFunction","n/a","n/a","n/a","n/a","n/a","n/a","n/a","n/a","n/a","n/a","n/a","n/a","n/a","n/a","CHK","CNTR","n/a","n/a","n/a","CNTR_AR_01","CRC_AR_01_BOTH","CRC_AR_01_ALT","CRC_AR_01_LOW","CRC_AR_01_NIBBLE","CNTR_AR_04","CRC_AR_04A","CNTR_AR_05","CRC_AR_05";
BA_DEF_ SG_ "GenSigDataID" STRING;
BA_DEF_DEF_ "CANFD_BRS" "1";
BA_DEF_DEF_ "GenSigStartValue" 0;
BA_DEF_DEF_ "VFrameFormat" "J1939PG";
BA_DEF_DEF_ "GenSigSendType" "NoSigSendType";
BA_DEF_DEF_ "GenMsgCycleTime" 0;
BA_DEF_DEF_ "GenMsgDelayTime" 0;
BA_DEF_DEF_ "GenMsgStartDelayTime" 0;
BA_DEF_DEF_ "GenMsgSendType" "NoMsgSendType";
BA_DEF_DEF_ "GenMsgILSupport" "Yes";
BA_DEF_DEF_ "NmAsrMessage" "No";
BA_DEF_DEF_ "GenSigFuncType" "NoFunction";
BA_DEF_DEF_ "GenSigDataID" "";

BA_ "GenMsgCycleTime" BO_ 427 100.000;
BA_ "GenMsgSendType" BO_ 427 0;
BA_ "VFrameFormat" BO_ 427 14;

BA_ "GenMsgCycleTime" BO_ 922 800.000;
BA_ "GenMsgSendType" BO_ 922 0;
BA_ "VFrameFormat" BO_ 922 14;

BA_ "GenMsgCycleTime" BO_ 1264 10000.000;
BA_ "GenMsgSendType" BO_ 1264 0;
BA_ "VFrameFormat" BO_ 1264 14;

BA_ "GenMsgCycleTime" BO_ 431 100.000;
BA_ "GenMsgSendType" BO_ 431 0;
BA_ "VFrameFormat" BO_ 431 14;

BA_ "GenMsgCycleTime" BO_ 1189 1000.000;
BA_ "GenMsgSendType" BO_ 1189 0;
BA_ "VFrameFormat" BO_ 1189 14;

BA_ "GenMsgCycleTime" BO_ 1348 500.000;
BA_ "GenMsgSendType" BO_ 1348 0;
BA_ "VFrameFormat" BO_ 1348 0;

BA_ "GenMsgDelayTime" BO_ 1379 100.000;
BA_ "GenMsgSendType" BO_ 1379 1;
BA_ "VFrameFormat" BO_ 1379 14;

BA_ "GenMsgDelayTime" BO_ 1284 20.000;
BA_ "GenMsgSendType" BO_ 1284 1;
BA_ "VFrameFormat" BO_ 1284 0;

BA_ "GenMsgDelayTime" BO_ 1569 5.000;
BA_ "GenMsgSendType" BO_ 1569 1;
BA_ "VFrameFormat" BO_ 1569 14;

BA_ "GenMsgDelayTime" BO_ 1538 5.000;
BA_ "GenMsgSendType" BO_ 1538 1;
BA_ "VFrameFormat" BO_ 1538 14;
BA_ "GenMsgILSupport" BO_ 1284 0;
BA_ "NmAsrMessage" BO_ 1284 1;
BA_ "GenSigSendType" SG_ 427 ActnOfHiBeamDrv 0;
BA_ "GenSigSendType" SG_ 427 ActnOfLedPosnLamp 0;
BA_ "GenSigSendType" SG_ 427 ActnOfLedStopLampActnOfLedStopLamp 0;
BA_ "GenSigSendType" SG_ 427 ActnOfLedStopLampChks 0;
BA_ "GenSigSendType" SG_ 427 ActnOfLedStopLampCntr 0;
BA_ "GenSigSendType" SG_ 427 ActnOfLoBeamDrvChks 0;
BA_ "GenSigSendType" SG_ 427 ActnOfLoBeamDrvCntr 0;
BA_ "GenSigSendType" SG_ 427 ActnOfLoBeamDrvOnOff 0;
BA_ "GenSigSendType" SG_ 427 ActnOfStopLampDrv 0;
BA_ "GenSigSendType" SG_ 427 ActnOfStopLampPass 0;
BA_ "GenSigSendType" SG_ 427 ActvnOfAhbc 0;
BA_ "GenSigSendType" SG_ 427 ActvnOfRvsg 0;
BA_ "GenSigSendType" SG_ 427 AntithftActvnReq 0;
BA_ "GenSigSendType" SG_ 427 BLEKeyBtnTrStsAndKeyIdBLEBtnSts 0;
BA_ "GenSigSendType" SG_ 427 BLEKeyBtnTrStsAndKeyIdKeyId3 0;
BA_ "GenSigSendType" SG_ 427 BLEKeyReadStsToKeyRmnWrnKey0 0;
BA_ "GenSigSendType" SG_ 427 BLEKeyReadStsToKeyRmnWrnKey1 0;
BA_ "GenSigSendType" SG_ 427 BLEKeyReadStsToKeyRmnWrnKey10 0;
BA_ "GenSigSendType" SG_ 427 BLEKeyReadStsToKeyRmnWrnKey11 0;
BA_ "GenSigSendType" SG_ 427 BLEKeyReadStsToKeyRmnWrnKey12 0;
BA_ "GenSigSendType" SG_ 427 BLEKeyReadStsToKeyRmnWrnKey13 0;
BA_ "GenSigSendType" SG_ 427 BLEKeyReadStsToKeyRmnWrnKey14 0;
BA_ "GenSigSendType" SG_ 427 BLEKeyReadStsToKeyRmnWrnKey15 0;
BA_ "GenSigSendType" SG_ 427 BLEKeyReadStsToKeyRmnWrnKey2 0;
BA_ "GenSigSendType" SG_ 427 BLEKeyReadStsToKeyRmnWrnKey3 0;
BA_ "GenSigSendType" SG_ 427 BLEKeyReadStsToKeyRmnWrnKey4 0;
BA_ "GenSigSendType" SG_ 427 BLEKeyReadStsToKeyRmnWrnKey5 0;
BA_ "GenSigSendType" SG_ 427 BLEKeyReadStsToKeyRmnWrnKey6 0;
BA_ "GenSigSendType" SG_ 427 BLEKeyReadStsToKeyRmnWrnKey7 0;
BA_ "GenSigSendType" SG_ 427 BLEKeyReadStsToKeyRmnWrnKey8 0;
BA_ "GenSigSendType" SG_ 427 BLEKeyReadStsToKeyRmnWrnKey9 0;
BA_ "GenSigSendType" SG_ 427 BLEKeyReadStsToVMMKey0 0;
BA_ "GenSigSendType" SG_ 427 BLEKeyReadStsToVMMKey1 0;
BA_ "GenSigSendType" SG_ 427 BLEKeyReadStsToVMMKey10 0;
BA_ "GenSigSendType" SG_ 427 BLEKeyReadStsToVMMKey11 0;
BA_ "GenSigSendType" SG_ 427 BLEKeyReadStsToVMMKey12 0;
BA_ "GenSigSendType" SG_ 427 BLEKeyReadStsToVMMKey13 0;
BA_ "GenSigSendType" SG_ 427 BLEKeyReadStsToVMMKey14 0;
BA_ "GenSigSendType" SG_ 427 BLEKeyReadStsToVMMKey15 0;
BA_ "GenSigSendType" SG_ 427 BLEKeyReadStsToVMMKey2 0;
BA_ "GenSigSendType" SG_ 427 BLEKeyReadStsToVMMKey3 0;
BA_ "GenSigSendType" SG_ 427 BLEKeyReadStsToVMMKey4 0;
BA_ "GenSigSendType" SG_ 427 BLEKeyReadStsToVMMKey5 0;
BA_ "GenSigSendType" SG_ 427 BLEKeyReadStsToVMMKey6 0;
BA_ "GenSigSendType" SG_ 427 BLEKeyReadStsToVMMKey7 0;
BA_ "GenSigSendType" SG_ 427 BLEKeyReadStsToVMMKey8 0;
BA_ "GenSigSendType" SG_ 427 BLEKeyReadStsToVMMKey9 0;
BA_ "GenSigSendType" SG_ 427 BattLoStsKey0 0;
BA_ "GenSigSendType" SG_ 427 BattLoStsKey1 0;
BA_ "GenSigSendType" SG_ 427 BattLoStsKey10 0;
BA_ "GenSigSendType" SG_ 427 BattLoStsKey11 0;
BA_ "GenSigSendType" SG_ 427 BattLoStsKey2 0;
BA_ "GenSigSendType" SG_ 427 BattLoStsKey3 0;
BA_ "GenSigSendType" SG_ 427 BattLoStsKey4 0;
BA_ "GenSigSendType" SG_ 427 BattLoStsKey5 0;
BA_ "GenSigSendType" SG_ 427 BattLoStsKey6 0;
BA_ "GenSigSendType" SG_ 427 BattLoStsKey7 0;
BA_ "GenSigSendType" SG_ 427 BattLoStsKey8 0;
BA_ "GenSigSendType" SG_ 427 BattLoStsKey9 0;
BA_ "GenSigSendType" SG_ 427 BexvStsExvActrPosn 0;
BA_ "GenSigSendType" SG_ 427 BexvStsExvBlkErr 0;
BA_ "GenSigSendType" SG_ 427 BexvStsExvCalibSts 0;
BA_ "GenSigSendType" SG_ 427 BexvStsExvElecStsErr 0;
BA_ "GenSigSendType" SG_ 427 BexvStsExvMovSts 0;
BA_ "GenSigSendType" SG_ 427 BexvStsExvOvrTempErr 0;
BA_ "GenSigSendType" SG_ 427 BexvStsExvOvrTrvlErr 0;
BA_ "GenSigSendType" SG_ 427 BexvStsExvPreHeatgSts 0;
BA_ "GenSigSendType" SG_ 427 BexvStsExvVoltgRangErr 0;
BA_ "GenSigSendType" SG_ 1264 BswAppVersion 0;
BA_ "GenSigSendType" SG_ 1264 BswCalVersion 0;
BA_ "GenSigSendType" SG_ 1264 BswRervedSignal 0;
BA_ "GenSigSendType" SG_ 427 BtnErsReq 0;
BA_ "GenSigSendType" SG_ 922 BtnStsOHCIntrLiSwtAllOnSts 0;
BA_ "GenSigSendType" SG_ 922 BtnStsOHCIntrLiSwtAutOnSts 0;
BA_ "GenSigSendType" SG_ 922 BtnStsOHCLiBtnReadingLe 0;
BA_ "GenSigSendType" SG_ 922 BtnStsOHCLiBtnReadingRi 0;
BA_ "GenSigSendType" SG_ 922 BtnStsOHCRLiBtnReadingLe 0;
BA_ "GenSigSendType" SG_ 922 BtnStsOHCRLiBtnReadingRi 0;
BA_ "GenSigSendType" SG_ 922 BtnStsOHTRLiBtnReadingLe 0;
BA_ "GenSigSendType" SG_ 922 BtnStsOHTRLiBtnReadingRi 0;
BA_ "GenSigSendType" SG_ 427 BtnTrSts 0;
BA_ "GenSigSendType" SG_ 427 CarLoctrAcoustReq 0;
BA_ "GenSigSendType" SG_ 427 CarLoctrAcoustSts 0;
BA_ "GenSigSendType" SG_ 427 CarLoctrExtrLiSts 0;
BA_ "GenSigSendType" SG_ 431 CarLoctrReq 0;
BA_ "GenSigSendType" SG_ 427 ChrgHndlStrtEna 0;
BA_ "GenSigSendType" SG_ 431 CmprSpdIncrReq 0;
BA_ "GenSigSendType" SG_ 431 DecUsgModAut 0;
BA_ "GenSigSendType" SG_ 431 DecUsgModAut2 0;
BA_ "GenSigSendType" SG_ 431 DigKeyIntrVldDetd 0;
BA_ "GenSigSendType" SG_ 431 DlyClsReq 0;
BA_ "GenSigSendType" SG_ 431 DoorDrvrAcsKeylsReq 0;
BA_ "GenSigSendType" SG_ 431 DoorDrvrAcsKeylsSts 0;
BA_ "GenSigSendType" SG_ 431 DoorDrvrHndlCmd 0;
BA_ "GenSigSendType" SG_ 431 DoorDrvrOpenLowReqOutdSwt1 0;
BA_ "GenSigStartValue" SG_ 431 DoorDrvrOpenLowReqOutdSwt1 2;
BA_ "GenSigSendType" SG_ 431 DoorDrvrOpenReqInsdSwt1 0;
BA_ "GenSigStartValue" SG_ 431 DoorDrvrOpenReqInsdSwt1 2;
BA_ "GenSigSendType" SG_ 431 DoorDrvrRelsReq 0;
BA_ "GenSigSendType" SG_ 431 DoorLeReAcsKeylsReq 0;
BA_ "GenSigSendType" SG_ 431 DoorLeReAcsKeylsSts 0;
BA_ "GenSigSendType" SG_ 431 DoorLeReOpenLowReqOutdSwt1 0;
BA_ "GenSigStartValue" SG_ 431 DoorLeReOpenLowReqOutdSwt1 2;
BA_ "GenSigSendType" SG_ 431 DoorLeReOpenReqInsdSwt1 0;
BA_ "GenSigStartValue" SG_ 431 DoorLeReOpenReqInsdSwt1 2;
BA_ "GenSigSendType" SG_ 431 DoorPassAcsKeylsReq 0;
BA_ "GenSigSendType" SG_ 431 DoorPassAcsKeylsSts 0;
BA_ "GenSigSendType" SG_ 431 DoorRiReAcsKeylsReq 0;
BA_ "GenSigSendType" SG_ 431 DoorRiReAcsKeylsSts 0;
BA_ "GenSigSendType" SG_ 431 DrvrIntrLockSngSwt 0;
BA_ "GenSigSendType" SG_ 431 EasyInOutDrvrReq 0;
BA_ "GenSigSendType" SG_ 431 EngActvnMod1WdReq 0;
BA_ "GenSigSendType" SG_ 431 ErsLockReqByKey 0;
BA_ "GenSigSendType" SG_ 1189 EtpZeroCrc1 0;
BA_ "GenSigSendType" SG_ 1189 EtpZeroCrc2 0;
BA_ "GenSigSendType" SG_ 1189 EtpZeroCrcEtpZeroCrc 0;
BA_ "GenSigSendType" SG_ 1189 EtpZeroDegrVal1 0;
BA_ "GenSigSendType" SG_ 1189 EtpZeroDegrVal2 0;
BA_ "GenSigSendType" SG_ 1189 EtpZeroDegrValEtpZeroDegrVal 0;
BA_ "GenSigSendType" SG_ 1189 EtpZeroSuccessFlag1 0;
BA_ "GenSigSendType" SG_ 1189 EtpZeroSuccessFlag2 0;
BA_ "GenSigSendType" SG_ 1189 EtpZeroSuccessFlagEtpZeroSuccessFlag 0;
BA_ "GenSigSendType" SG_ 431 FacQlyForDoorDrvrSts 0;
BA_ "GenSigSendType" SG_ 431 FbOfPrkgLiShow 0;
BA_ "GenSigSendType" SG_ 431 GlvBoxIntrSwtSts 0;
BA_ "GenSigSendType" SG_ 431 GrlAutoCalibReq 0;
BA_ "GenSigSendType" SG_ 431 GrlHldTrqActive 0;
BA_ "GenSigSendType" SG_ 431 GrlShttrDmdShttrCalEna 0;
BA_ "GenSigSendType" SG_ 431 GrlShttrDmdShttrPosnReq 0;
BA_ "GenSigSendType" SG_ 431 GrlShttrMoveActive 0;
BA_ "GenSigSendType" SG_ 431 GrlShttrStsShttrActrFlt 0;
BA_ "GenSigSendType" SG_ 431 GrlShttrStsShttrBlkd 0;
BA_ "GenSigSendType" SG_ 431 GrlShttrStsShttrCalActv 0;
BA_ "GenSigSendType" SG_ 431 GrlShttrStsShttrCalIndcd 0;
BA_ "GenSigSendType" SG_ 431 GrlShttrStsShttrElecErr 0;
BA_ "GenSigSendType" SG_ 431 GrlShttrStsShttrPosnRaw 0;
BA_ "GenSigSendType" SG_ 431 GrlShttrStsShttrSnsrFlt 0;
BA_ "GenSigSendType" SG_ 431 GrlShttrStsShttrTErr 0;
BA_ "GenSigSendType" SG_ 431 GrlShttrStsShttrULoErr 0;
BA_ "GenSigSendType" SG_ 431 HoodSwt1 0;
BA_ "GenSigSendType" SG_ 922 IntLightDrvSideDoorSupply 0;
BA_ "GenSigSendType" SG_ 922 IntLightDrvSideSupply 0;
BA_ "GenSigSendType" SG_ 922 IntLightFootwellSupply 0;
BA_ "GenSigSendType" SG_ 922 IntLightLuggageSupply 0;
BA_ "GenSigSendType" SG_ 922 IntLightReDrvDoorSupply 0;
BA_ "GenSigSendType" SG_ 922 IntLightReDrvSideSupply 0;
BA_ "GenSigSendType" SG_ 922 IntrLiCmdGroupIntrLiActvn 0;
BA_ "GenSigSendType" SG_ 922 IntrLiCmdGroupIntrLiRoofDim 0;
BA_ "GenSigSendType" SG_ 922 IntrLiCmdGroupIntrLiRoofDmdOff 0;
BA_ "GenSigSendType" SG_ 922 IntrMirrRespIntrMirrDimPerc 0;
BA_ "GenSigSendType" SG_ 922 IntrMirrRespIntrMirrIntFailr 0;
BA_ "GenSigSendType" SG_ 922 IntrMirrRespResdBoolean 0;
BA_ "GenSigSendType" SG_ 922 IntrMirrRespResdUInt6 0;
BA_ "GenSigSendType" SG_ 431 KeyDiReqKey0 0;
BA_ "GenSigSendType" SG_ 431 KeyDiReqKey1 0;
BA_ "GenSigSendType" SG_ 431 KeyDiReqKey10 0;
BA_ "GenSigSendType" SG_ 431 KeyDiReqKey11 0;
BA_ "GenSigSendType" SG_ 431 KeyDiReqKey2 0;
BA_ "GenSigSendType" SG_ 431 KeyDiReqKey3 0;
BA_ "GenSigSendType" SG_ 431 KeyDiReqKey4 0;
BA_ "GenSigSendType" SG_ 431 KeyDiReqKey5 0;
BA_ "GenSigSendType" SG_ 431 KeyDiReqKey6 0;
BA_ "GenSigSendType" SG_ 431 KeyDiReqKey7 0;
BA_ "GenSigSendType" SG_ 431 KeyDiReqKey8 0;
BA_ "GenSigSendType" SG_ 431 KeyDiReqKey9 0;
BA_ "GenSigSendType" SG_ 431 KeyReadReqFromKeyRmn 0;
BA_ "GenSigSendType" SG_ 431 KeyReadReqFromKeyWarn 0;
BA_ "GenSigSendType" SG_ 431 KeyReadStsToKeyRmnKey0 0;
BA_ "GenSigSendType" SG_ 431 KeyReadStsToKeyRmnKey1 0;
BA_ "GenSigSendType" SG_ 431 KeyReadStsToKeyRmnKey10 0;
BA_ "GenSigSendType" SG_ 431 KeyReadStsToKeyRmnKey11 0;
BA_ "GenSigSendType" SG_ 431 KeyReadStsToKeyRmnKey2 0;
BA_ "GenSigSendType" SG_ 431 KeyReadStsToKeyRmnKey3 0;
BA_ "GenSigSendType" SG_ 431 KeyReadStsToKeyRmnKey4 0;
BA_ "GenSigSendType" SG_ 431 KeyReadStsToKeyRmnKey5 0;
BA_ "GenSigSendType" SG_ 431 KeyReadStsToKeyRmnKey6 0;
BA_ "GenSigSendType" SG_ 431 KeyReadStsToKeyRmnKey7 0;
BA_ "GenSigSendType" SG_ 431 KeyReadStsToKeyRmnKey8 0;
BA_ "GenSigSendType" SG_ 431 KeyReadStsToKeyRmnKey9 0;
BA_ "GenSigSendType" SG_ 431 KeyReadStsToKeyWarnKey0 0;
BA_ "GenSigSendType" SG_ 431 KeyReadStsToKeyWarnKey1 0;
BA_ "GenSigSendType" SG_ 431 KeyReadStsToKeyWarnKey10 0;
BA_ "GenSigSendType" SG_ 431 KeyReadStsToKeyWarnKey11 0;
BA_ "GenSigSendType" SG_ 431 KeyReadStsToKeyWarnKey2 0;
BA_ "GenSigSendType" SG_ 431 KeyReadStsToKeyWarnKey3 0;
BA_ "GenSigSendType" SG_ 431 KeyReadStsToKeyWarnKey4 0;
BA_ "GenSigSendType" SG_ 431 KeyReadStsToKeyWarnKey5 0;
BA_ "GenSigSendType" SG_ 431 KeyReadStsToKeyWarnKey6 0;
BA_ "GenSigSendType" SG_ 431 KeyReadStsToKeyWarnKey7 0;
BA_ "GenSigSendType" SG_ 431 KeyReadStsToKeyWarnKey8 0;
BA_ "GenSigSendType" SG_ 431 KeyReadStsToKeyWarnKey9 0;
BA_ "GenSigSendType" SG_ 431 KeyReadStsToVMMNFCKey0 0;
BA_ "GenSigSendType" SG_ 431 KeyReadStsToVMMNFCKey1 0;
BA_ "GenSigSendType" SG_ 431 KeyReadStsToVMMNFCKey10 0;
BA_ "GenSigSendType" SG_ 431 KeyReadStsToVMMNFCKey11 0;
BA_ "GenSigSendType" SG_ 431 KeyReadStsToVMMNFCKey12 0;
BA_ "GenSigSendType" SG_ 431 KeyReadStsToVMMNFCKey13 0;
BA_ "GenSigSendType" SG_ 431 KeyReadStsToVMMNFCKey14 0;
BA_ "GenSigSendType" SG_ 431 KeyReadStsToVMMNFCKey15 0;
BA_ "GenSigSendType" SG_ 431 KeyReadStsToVMMNFCKey2 0;
BA_ "GenSigSendType" SG_ 431 KeyReadStsToVMMNFCKey3 0;
BA_ "GenSigSendType" SG_ 431 KeyReadStsToVMMNFCKey4 0;
BA_ "GenSigSendType" SG_ 431 KeyReadStsToVMMNFCKey5 0;
BA_ "GenSigSendType" SG_ 431 KeyReadStsToVMMNFCKey6 0;
BA_ "GenSigSendType" SG_ 431 KeyReadStsToVMMNFCKey7 0;
BA_ "GenSigSendType" SG_ 431 KeyReadStsToVMMNFCKey8 0;
BA_ "GenSigSendType" SG_ 431 KeyReadStsToVMMNFCKey9 0;
BA_ "GenSigSendType" SG_ 431 KeyReadStsToVmmKey0 0;
BA_ "GenSigSendType" SG_ 431 KeyReadStsToVmmKey1 0;
BA_ "GenSigSendType" SG_ 431 KeyReadStsToVmmKey10 0;
BA_ "GenSigSendType" SG_ 431 KeyReadStsToVmmKey11 0;
BA_ "GenSigSendType" SG_ 431 KeyReadStsToVmmKey2 0;
BA_ "GenSigSendType" SG_ 431 KeyReadStsToVmmKey3 0;
BA_ "GenSigSendType" SG_ 431 KeyReadStsToVmmKey4 0;
BA_ "GenSigSendType" SG_ 431 KeyReadStsToVmmKey5 0;
BA_ "GenSigSendType" SG_ 431 KeyReadStsToVmmKey6 0;
BA_ "GenSigSendType" SG_ 431 KeyReadStsToVmmKey7 0;
BA_ "GenSigSendType" SG_ 431 KeyReadStsToVmmKey8 0;
BA_ "GenSigSendType" SG_ 431 KeyReadStsToVmmKey9 0;
BA_ "GenSigSendType" SG_ 922 LiLvrDiagc 0;
BA_ "GenSigStartValue" SG_ 922 LiLvrDiagc 3;
BA_ "GenSigSendType" SG_ 431 LiOprnMod 0;
BA_ "GenSigSendType" SG_ 431 MobDeBtnCarLctrSts 0;
BA_ "GenSigSendType" SG_ 431 MobDeBtnPanicAlarmSts 0;
BA_ "GenSigSendType" SG_ 431 MobDevAVPReq 0;
BA_ "GenSigSendType" SG_ 431 MobDevBtnLockStsAndKeyIdKeyId3 0;
BA_ "GenSigSendType" SG_ 431 MobDevBtnLockStsAndKeyIdPsdNotPsd 0;
BA_ "GenSigSendType" SG_ 431 MobDevBtnTrReq 0;
BA_ "GenSigSendType" SG_ 431 MobDevBtnUnlckStsAndKeyIdKeyId3 0;
BA_ "GenSigSendType" SG_ 431 MobDevBtnUnlckStsAndKeyIdPsdNotPsd 0;
BA_ "GenSigSendType" SG_ 431 MobDevChrgngLidOpnReq 0;
BA_ "GenSigSendType" SG_ 431 MobDevKeyDiReqKeySts0 0;
BA_ "GenSigSendType" SG_ 431 MobDevKeyDiReqKeySts1 0;
BA_ "GenSigSendType" SG_ 431 MobDevKeyDiReqKeySts10 0;
BA_ "GenSigSendType" SG_ 431 MobDevKeyDiReqKeySts11 0;
BA_ "GenSigSendType" SG_ 431 MobDevKeyDiReqKeySts12 0;
BA_ "GenSigSendType" SG_ 431 MobDevKeyDiReqKeySts13 0;
BA_ "GenSigSendType" SG_ 431 MobDevKeyDiReqKeySts14 0;
BA_ "GenSigSendType" SG_ 431 MobDevKeyDiReqKeySts15 0;
BA_ "GenSigSendType" SG_ 431 MobDevKeyDiReqKeySts2 0;
BA_ "GenSigSendType" SG_ 431 MobDevKeyDiReqKeySts3 0;
BA_ "GenSigSendType" SG_ 431 MobDevKeyDiReqKeySts4 0;
BA_ "GenSigSendType" SG_ 431 MobDevKeyDiReqKeySts5 0;
BA_ "GenSigSendType" SG_ 431 MobDevKeyDiReqKeySts6 0;
BA_ "GenSigSendType" SG_ 431 MobDevKeyDiReqKeySts7 0;
BA_ "GenSigSendType" SG_ 431 MobDevKeyDiReqKeySts8 0;
BA_ "GenSigSendType" SG_ 431 MobDevKeyDiReqKeySts9 0;
BA_ "GenSigSendType" SG_ 431 MobDevKeyEnaStsKey0 0;
BA_ "GenSigSendType" SG_ 431 MobDevKeyEnaStsKey1 0;
BA_ "GenSigSendType" SG_ 431 MobDevKeyEnaStsKey10 0;
BA_ "GenSigSendType" SG_ 431 MobDevKeyEnaStsKey11 0;
BA_ "GenSigSendType" SG_ 431 MobDevKeyEnaStsKey12 0;
BA_ "GenSigSendType" SG_ 431 MobDevKeyEnaStsKey13 0;
BA_ "GenSigSendType" SG_ 431 MobDevKeyEnaStsKey14 0;
BA_ "GenSigSendType" SG_ 431 MobDevKeyEnaStsKey15 0;
BA_ "GenSigSendType" SG_ 431 MobDevKeyEnaStsKey2 0;
BA_ "GenSigSendType" SG_ 431 MobDevKeyEnaStsKey3 0;
BA_ "GenSigSendType" SG_ 431 MobDevKeyEnaStsKey4 0;
BA_ "GenSigSendType" SG_ 431 MobDevKeyEnaStsKey5 0;
BA_ "GenSigSendType" SG_ 431 MobDevKeyEnaStsKey6 0;
BA_ "GenSigSendType" SG_ 431 MobDevKeyEnaStsKey7 0;
BA_ "GenSigSendType" SG_ 431 MobDevKeyEnaStsKey8 0;
BA_ "GenSigSendType" SG_ 431 MobDevKeyEnaStsKey9 0;
BA_ "GenSigSendType" SG_ 431 MobDevOpenClsCmftReq 0;
BA_ "GenSigSendType" SG_ 431 MobDevRoofOpnClsReq 0;
BA_ "GenSigSendType" SG_ 431 MobDevVldUserStsToVMM 0;
BA_ "GenSigSendType" SG_ 431 MobDevWinOpnClsReq 0;
BA_ "GenSigSendType" SG_ 431 NFCKeyReadStsToKeyRmnWrnKey0 0;
BA_ "GenSigSendType" SG_ 431 NFCKeyReadStsToKeyRmnWrnKey1 0;
BA_ "GenSigSendType" SG_ 431 NFCKeyReadStsToKeyRmnWrnKey10 0;
BA_ "GenSigSendType" SG_ 431 NFCKeyReadStsToKeyRmnWrnKey11 0;
BA_ "GenSigSendType" SG_ 431 NFCKeyReadStsToKeyRmnWrnKey12 0;
BA_ "GenSigSendType" SG_ 431 NFCKeyReadStsToKeyRmnWrnKey13 0;
BA_ "GenSigSendType" SG_ 431 NFCKeyReadStsToKeyRmnWrnKey14 0;
BA_ "GenSigSendType" SG_ 431 NFCKeyReadStsToKeyRmnWrnKey15 0;
BA_ "GenSigSendType" SG_ 431 NFCKeyReadStsToKeyRmnWrnKey2 0;
BA_ "GenSigSendType" SG_ 431 NFCKeyReadStsToKeyRmnWrnKey3 0;
BA_ "GenSigSendType" SG_ 431 NFCKeyReadStsToKeyRmnWrnKey4 0;
BA_ "GenSigSendType" SG_ 431 NFCKeyReadStsToKeyRmnWrnKey5 0;
BA_ "GenSigSendType" SG_ 431 NFCKeyReadStsToKeyRmnWrnKey6 0;
BA_ "GenSigSendType" SG_ 431 NFCKeyReadStsToKeyRmnWrnKey7 0;
BA_ "GenSigSendType" SG_ 431 NFCKeyReadStsToKeyRmnWrnKey8 0;
BA_ "GenSigSendType" SG_ 431 NFCKeyReadStsToKeyRmnWrnKey9 0;
BA_ "GenSigSendType" SG_ 922 OHCFrBtnErrStsIntrLiSwtAllOnSts 0;
BA_ "GenSigSendType" SG_ 922 OHCFrBtnErrStsIntrLiSwtAutOnSts 0;
BA_ "GenSigSendType" SG_ 922 OHCFrBtnErrStsLiBtnReadingLe 0;
BA_ "GenSigSendType" SG_ 922 OHCFrBtnErrStsLiBtnReadingRi 0;
BA_ "GenSigSendType" SG_ 922 OHCSecRowBtnErrStsLiBtnReadingLe 0;
BA_ "GenSigSendType" SG_ 922 OHCSecRowBtnErrStsLiBtnReadingRi 0;
BA_ "GenSigSendType" SG_ 922 OHCThirdRowBtnErrStsLiBtnReadingLe 0;
BA_ "GenSigSendType" SG_ 922 OHCThirdRowBtnErrStsLiBtnReadingRi 0;
BA_ "GenSigDataID" SG_ 431 OutdBriChks "0x1F42";
BA_ "GenSigFuncType" SG_ 431 OutdBriChks 15;
BA_ "GenSigSendType" SG_ 431 OutdBriChks 0;
BA_ "GenSigFuncType" SG_ 431 OutdBriCntr 16;
BA_ "GenSigSendType" SG_ 431 OutdBriCntr 0;
BA_ "GenSigSendType" SG_ 431 OutdBriHwChks 0;
BA_ "GenSigSendType" SG_ 431 OutdBriHwCntr 0;
BA_ "GenSigSendType" SG_ 431 OutdBriHwOutdBriSts 0;
BA_ "GenSigSendType" SG_ 431 OutdBriSts 0;
BA_ "GenSigSendType" SG_ 922 RainSnsrDiagcRainSnsrHiTDetd 0;
BA_ "GenSigSendType" SG_ 922 RainSnsrDiagcRainSnsrHiVoltDetd 0;
BA_ "GenSigSendType" SG_ 922 RainSnsrErrCalErr 0;
BA_ "GenSigSendType" SG_ 922 RainSnsrErrCalErrActv 0;
BA_ "GenSigSendType" SG_ 922 RainSnsrErrRainDetnErr 0;
BA_ "GenSigSendType" SG_ 922 RainSnsrErrRainDetnErrActv 0;
BA_ "GenSigSendType" SG_ 922 ReadLiErrStsReadLiStsFirstRowLe 0;
BA_ "GenSigSendType" SG_ 922 ReadLiErrStsReadLiStsFirstRowRi 0;
BA_ "GenSigSendType" SG_ 922 ReadLiErrStsReadLiStsSecondRowLe 0;
BA_ "GenSigSendType" SG_ 922 ReadLiErrStsReadLiStsSecondRowRi 0;
BA_ "GenSigSendType" SG_ 922 ReadLiErrStsReadLiStsThirdRowLe 0;
BA_ "GenSigSendType" SG_ 922 ReadLiErrStsReadLiStsThirdRowRi 0;
BA_ "GenSigSendType" SG_ 922 ReadLiIntensityValZone1 0;
BA_ "GenSigSendType" SG_ 922 ReadLiIntensityValZone2 0;
BA_ "GenSigSendType" SG_ 922 ReadLiIntensityValZone3 0;
BA_ "GenSigSendType" SG_ 922 ReadLiIntensityValZone4 0;
BA_ "GenSigSendType" SG_ 922 ReadLiIntensityValZone5 0;
BA_ "GenSigSendType" SG_ 922 ReadLiIntensityValZone6 0;
BA_ "GenSigSendType" SG_ 1189 SnsrInclnCmd 0;
BA_ "GenSigSendType" SG_ 1189 SnsrIntrScanCmdAirFanSts 0;
BA_ "GenSigSendType" SG_ 1189 SnsrIntrScanCmdArmReq 0;
BA_ "GenSigSendType" SG_ 1189 SnsrIntrScanCmdCurtRollUpDwn 0;
BA_ "GenSigSendType" SG_ 1189 SnsrIntrScanCmdRoofPosn 0;
BA_ "GenSigSendType" SG_ 1189 SnsrIntrScanCmdTemp 0;
BA_ "GenSigSendType" SG_ 1189 SnsrIntrScanCmdWinPosn 0;
BA_ "GenSigSendType" SG_ 1189 SnsrSoundrBattBackedCmdArmCmd 0;
BA_ "GenSigSendType" SG_ 1189 SnsrSoundrBattBackedCmdChirpTyp 0;
BA_ "GenSigSendType" SG_ 1189 SnsrSoundrBattBackedCmdChrgReq 0;
BA_ "GenSigSendType" SG_ 1189 SnsrSoundrBattBackedCmdSoundReq 0;
BA_ "GenSigSendType" SG_ 431 SteerLockChkSteerLockDataChk0 0;
BA_ "GenSigSendType" SG_ 431 SteerLockChkSteerLockDataChk1 0;
BA_ "GenSigSendType" SG_ 431 SteerLockChkSteerLockDataChk2 0;
BA_ "GenSigSendType" SG_ 431 SteerLockChkSteerLockDataChk3 0;
BA_ "GenSigSendType" SG_ 431 SteerLockChkSteerLockDataChk4 0;
BA_ "GenSigSendType" SG_ 431 SteerLockChkSteerLockDataChk5 0;
BA_ "GenSigSendType" SG_ 431 SteerLockChkSteerLockDataChk6 0;
BA_ "GenSigSendType" SG_ 431 SteerLockChkSts 0;
BA_ "GenSigSendType" SG_ 431 SteerLockReqCommand 0;
BA_ "GenSigSendType" SG_ 431 SteerLockReqSteerLockDataReq0 0;
BA_ "GenSigSendType" SG_ 431 SteerLockReqSteerLockDataReq1 0;
BA_ "GenSigSendType" SG_ 431 SteerLockReqSteerLockDataReq2 0;
BA_ "GenSigSendType" SG_ 431 SteerLockReqSteerLockDataReq3 0;
BA_ "GenSigSendType" SG_ 431 SteerLockReqSteerLockDataReq4 0;
BA_ "GenSigSendType" SG_ 431 SteerLockReqSteerLockDataReq5 0;
BA_ "GenSigSendType" SG_ 431 SteerLockReqSteerLockDataReq6 0;
BA_ "GenSigSendType" SG_ 922 StsOfLogoFolwLoBeam 0;
BA_ "GenSigSendType" SG_ 1189 SunRoofAndCurtPosnCmdOpenPerc 0;
BA_ "GenSigSendType" SG_ 1189 SunRoofAndCurtPosnCmdSel 0;
BA_ "GenSigSendType" SG_ 1189 SunRoofEna 0;
BA_ "GenSigSendType" SG_ 1189 TCSDcdcactvdReq 0;
BA_ "GenSigSendType" SG_ 1189 TCSUsgModReq 0;
BA_ "GenSigSendType" SG_ 1189 ThirdRowLeReadLiReq 0;
BA_ "GenSigSendType" SG_ 1189 ThirdRowRiReadLiReq 0;
BA_ "GenSigSendType" SG_ 1189 TrlrLiBrkActvt 0;
BA_ "GenSigSendType" SG_ 1189 TrlrLiFogActvt 0;
BA_ "GenSigSendType" SG_ 1189 TrlrLiPosnActvt 0;
BA_ "GenSigStartValue" SG_ 1189 TrlrLiPosnActvt 1;
BA_ "GenSigSendType" SG_ 1189 TrlrLiRvsgActvt 0;
BA_ "GenSigSendType" SG_ 1348 VFCVectorZCUDMBlockID 0;
BA_ "GenSigSendType" SG_ 1348 VFCVectorZCUDMVFCid0 0;
BA_ "GenSigSendType" SG_ 1348 VFCVectorZCUDMVFCid1 0;
BA_ "GenSigSendType" SG_ 1348 VFCVectorZCUDMVFCid10 0;
BA_ "GenSigSendType" SG_ 1348 VFCVectorZCUDMVFCid11 0;
BA_ "GenSigSendType" SG_ 1348 VFCVectorZCUDMVFCid12 0;
BA_ "GenSigSendType" SG_ 1348 VFCVectorZCUDMVFCid13 0;
BA_ "GenSigSendType" SG_ 1348 VFCVectorZCUDMVFCid14 0;
BA_ "GenSigSendType" SG_ 1348 VFCVectorZCUDMVFCid15 0;
BA_ "GenSigSendType" SG_ 1348 VFCVectorZCUDMVFCid16 0;
BA_ "GenSigSendType" SG_ 1348 VFCVectorZCUDMVFCid17 0;
BA_ "GenSigSendType" SG_ 1348 VFCVectorZCUDMVFCid18 0;
BA_ "GenSigSendType" SG_ 1348 VFCVectorZCUDMVFCid19 0;
BA_ "GenSigSendType" SG_ 1348 VFCVectorZCUDMVFCid2 0;
BA_ "GenSigSendType" SG_ 1348 VFCVectorZCUDMVFCid20 0;
BA_ "GenSigSendType" SG_ 1348 VFCVectorZCUDMVFCid21 0;
BA_ "GenSigSendType" SG_ 1348 VFCVectorZCUDMVFCid22 0;
BA_ "GenSigSendType" SG_ 1348 VFCVectorZCUDMVFCid23 0;
BA_ "GenSigSendType" SG_ 1348 VFCVectorZCUDMVFCid24 0;
BA_ "GenSigSendType" SG_ 1348 VFCVectorZCUDMVFCid25 0;
BA_ "GenSigSendType" SG_ 1348 VFCVectorZCUDMVFCid26 0;
BA_ "GenSigSendType" SG_ 1348 VFCVectorZCUDMVFCid27 0;
BA_ "GenSigSendType" SG_ 1348 VFCVectorZCUDMVFCid28 0;
BA_ "GenSigSendType" SG_ 1348 VFCVectorZCUDMVFCid29 0;
BA_ "GenSigSendType" SG_ 1348 VFCVectorZCUDMVFCid3 0;
BA_ "GenSigSendType" SG_ 1348 VFCVectorZCUDMVFCid30 0;
BA_ "GenSigSendType" SG_ 1348 VFCVectorZCUDMVFCid31 0;
BA_ "GenSigSendType" SG_ 1348 VFCVectorZCUDMVFCid32 0;
BA_ "GenSigSendType" SG_ 1348 VFCVectorZCUDMVFCid33 0;
BA_ "GenSigSendType" SG_ 1348 VFCVectorZCUDMVFCid34 0;
BA_ "GenSigSendType" SG_ 1348 VFCVectorZCUDMVFCid35 0;
BA_ "GenSigSendType" SG_ 1348 VFCVectorZCUDMVFCid36 0;
BA_ "GenSigSendType" SG_ 1348 VFCVectorZCUDMVFCid37 0;
BA_ "GenSigSendType" SG_ 1348 VFCVectorZCUDMVFCid38 0;
BA_ "GenSigSendType" SG_ 1348 VFCVectorZCUDMVFCid39 0;
BA_ "GenSigSendType" SG_ 1348 VFCVectorZCUDMVFCid4 0;
BA_ "GenSigSendType" SG_ 1348 VFCVectorZCUDMVFCid40 0;
BA_ "GenSigSendType" SG_ 1348 VFCVectorZCUDMVFCid41 0;
BA_ "GenSigSendType" SG_ 1348 VFCVectorZCUDMVFCid42 0;
BA_ "GenSigSendType" SG_ 1348 VFCVectorZCUDMVFCid43 0;
BA_ "GenSigSendType" SG_ 1348 VFCVectorZCUDMVFCid44 0;
BA_ "GenSigSendType" SG_ 1348 VFCVectorZCUDMVFCid45 0;
BA_ "GenSigSendType" SG_ 1348 VFCVectorZCUDMVFCid46 0;
BA_ "GenSigSendType" SG_ 1348 VFCVectorZCUDMVFCid47 0;
BA_ "GenSigSendType" SG_ 1348 VFCVectorZCUDMVFCid48 0;
BA_ "GenSigSendType" SG_ 1348 VFCVectorZCUDMVFCid49 0;
BA_ "GenSigSendType" SG_ 1348 VFCVectorZCUDMVFCid5 0;
BA_ "GenSigSendType" SG_ 1348 VFCVectorZCUDMVFCid50 0;
BA_ "GenSigSendType" SG_ 1348 VFCVectorZCUDMVFCid51 0;
BA_ "GenSigSendType" SG_ 1348 VFCVectorZCUDMVFCid52 0;
BA_ "GenSigSendType" SG_ 1348 VFCVectorZCUDMVFCid53 0;
BA_ "GenSigSendType" SG_ 1348 VFCVectorZCUDMVFCid54 0;
BA_ "GenSigSendType" SG_ 1348 VFCVectorZCUDMVFCid55 0;
BA_ "GenSigSendType" SG_ 1348 VFCVectorZCUDMVFCid56 0;
BA_ "GenSigSendType" SG_ 1348 VFCVectorZCUDMVFCid57 0;
BA_ "GenSigSendType" SG_ 1348 VFCVectorZCUDMVFCid58 0;
BA_ "GenSigSendType" SG_ 1348 VFCVectorZCUDMVFCid59 0;
BA_ "GenSigSendType" SG_ 1348 VFCVectorZCUDMVFCid6 0;
BA_ "GenSigSendType" SG_ 1348 VFCVectorZCUDMVFCid60 0;
BA_ "GenSigSendType" SG_ 1348 VFCVectorZCUDMVFCid61 0;
BA_ "GenSigSendType" SG_ 1348 VFCVectorZCUDMVFCid7 0;
BA_ "GenSigSendType" SG_ 1348 VFCVectorZCUDMVFCid8 0;
BA_ "GenSigSendType" SG_ 1348 VFCVectorZCUDMVFCid9 0;
BA_ "GenSigSendType" SG_ 1189 VcEvFehMsgHybridFlt 0;
BA_ "GenSigSendType" SG_ 1264 VcEvFehMsgRedPerf 0;
BA_ "GenSigSendType" SG_ 1189 VcEvFehMsgStopSafely 0;
BA_ "GenSigSendType" SG_ 1189 VcEvFunction21 0;
BA_ "GenSigSendType" SG_ 1189 VcEvPowerUpFail 0;
BA_ "GenSigSendType" SG_ 1189 VcEvPropStartInhibit 0;
BA_ "GenSigSendType" SG_ 1189 VcEvSymCC 0;
BA_ "GenSigSendType" SG_ 1189 VcEvSymRed 0;
BA_ "GenSigSendType" SG_ 1189 VcEvUnexpPowerDown 0;
BA_ "GenSigSendType" SG_ 1189 VcEvUnexpctClearDCA 0;
BA_ "GenSigSendType" SG_ 427 VoltKL15 0;
BA_ "GenSigSendType" SG_ 1284 WakeUpReasonsforZCUDM 0;
BA_ "GenSigSendType" SG_ 1189 WinDsblLeftSts 0;
BA_ "GenSigSendType" SG_ 1189 WinHwSwtDrvrReDoor 0;
BA_ "GenSigSendType" SG_ 431 WinWshrLvrCmd 0;
BA_ "GenSigSendType" SG_ 1189 WindCorrnValAmb 0;
BA_ "GenSigSendType" SG_ 1189 WindCorrnValFrnt 0;
BA_ "GenSigSendType" SG_ 1189 WindCorrnValHud 0;
BA_ "GenSigSendType" SG_ 922 WipgAutFrntMod 0;
BA_ "GenSigSendType" SG_ 1189 WipgPwrActvnNotSafeAcsyMode 0;
BA_ "GenSigSendType" SG_ 1189 WipgPwrActvnNotSafeDrvgMod 0;
BA_ "GenSigSendType" SG_ 1189 WipgPwrActvnSafeWipgPwrAcsyModSafe 0;
BA_ "GenSigStartValue" SG_ 1189 WipgPwrActvnSafeWipgPwrAcsyModSafe 1;
BA_ "GenSigSendType" SG_ 1189 WipgPwrActvnSafeWipgPwrDrvgModSafe 0;
BA_ "GenSigStartValue" SG_ 1189 WipgPwrActvnSafeWipgPwrDrvgModSafe 1;
BA_ "GenSigSendType" SG_ 1189 WiprActvMech 0;
BA_ "GenSigSendType" SG_ 1189 WiprInPrkgPosnLo 0;
BA_ "GenSigSendType" SG_ 1189 WiprInWipgArMech 0;
BA_ "GenSigSendType" SG_ 1189 WiprLvrComErrDetd 0;
BA_ "GenSigSendType" SG_ 922 WiprLvrDiagc 0;
BA_ "GenSigStartValue" SG_ 922 WiprLvrDiagc 3;
BA_ "GenSigSendType" SG_ 1189 WiprLvrNodErrDetd 0;
BA_ "GenSigSendType" SG_ 1189 WiprMotComErrDetd 0;
BA_ "GenSigSendType" SG_ 1189 WiprMotErr 0;
BA_ "GenSigSendType" SG_ 1189 WiprMotErrSafeMech 0;
BA_ "GenSigSendType" SG_ 1189 WiprMotFrntLvrCmdNotSafeLvrInHiSpdPosn 0;
BA_ "GenSigSendType" SG_ 1189 WiprMotFrntLvrCmdNotSafeLvrInIntlPosn 0;
BA_ "GenSigSendType" SG_ 1189 WiprMotFrntLvrCmdNotSafeLvrInLoSpdPosn 0;
BA_ "GenSigSendType" SG_ 1189 WiprMotFrntLvrCmdNotSafeLvrInSnglStrokePos 0;
BA_ "GenSigSendType" SG_ 1189 WiprMotFrntOffsAg 0;
BA_ "GenSigSendType" SG_ 1189 WiprMotIntlCmd 0;
BA_ "GenSigSendType" SG_ 1189 WiprMotNodErrDetd 0;
BA_ "GenSigSendType" SG_ 1189 WiprMotRelayMech 0;
BA_ "GenSigStartValue" SG_ 1189 WiprMotRelayMech 1;
BA_ "GenSigSendType" SG_ 1189 WiprPosnForSrvReq 0;
BA_ "GenSigSendType" SG_ 1189 WiprReInWipgAr 0;
BA_ "GenSigSendType" SG_ 1189 WiprWshrMgrErrDetd 0;
BA_ "GenSigSendType" SG_ 427 WrcActvFlg 0;
BA_ "GenSigSendType" SG_ 1189 WshngCycActv 0;
BA_ "GenSigSendType" SG_ 1189 WshngCycActvMech 0;
BA_ "GenSigSendType" SG_ 1189 WshrFldLvlDetdLo 0;
BA_ "GenSigSendType" SG_ 1189 WshrHeatgSig 0;
BA_ "GenSigSendType" SG_ 1189 WshrLvrPosnNotSafe 0;
BA_ "GenSigSendType" SG_ 1189 WshrLvrPosnSafe 0;
BA_ "GenSigStartValue" SG_ 1189 WshrLvrPosnSafe 1;
BA_ "GenSigSendType" SG_ 1189 XCUPcodeStatus 0;
BA_ "GenSigSendType" SG_ 427 XCUTempXcuMcuTemp 0;
BA_ "GenSigStartValue" SG_ 427 XCUTempXcuMcuTemp 40;
BA_ "GenSigSendType" SG_ 427 XCUTempXcuPcbTemp 0;
BA_ "GenSigStartValue" SG_ 427 XCUTempXcuPcbTemp 40;
BA_ "GenSigSendType" SG_ 427 XcuAccPadAnVolt 0;
BA_ "GenSigSendType" SG_ 427 XcuAccPwmDuty 0;
BA_ "GenSigSendType" SG_ 427 XcuCemWakupVolt 0;
BA_ "GenSigSendType" SG_ 427 XcuChargeNVolt 0;
BA_ "GenSigSendType" SG_ 427 XcuChargePVolt 0;
BA_ "GenSigSendType" SG_ 427 XcuCpuLoadAvgVal 0;
BA_ "GenSigSendType" SG_ 427 XcuCpuLoadMaxVal 0;
BA_ "GenSigSendType" SG_ 427 XcuCpuLoadMinVal 0;
BA_ "GenSigSendType" SG_ 427 XcuDcWakupVolt 0;
BA_ "GenSigSendType" SG_ 427 XcuDiagEnblSts 0;
BA_ "GenSigSendType" SG_ 427 XcuDseWtTqPropFrnt 0;
BA_ "GenSigStartValue" SG_ 427 XcuDseWtTqPropFrnt 8000;
BA_ "GenSigSendType" SG_ 427 XcuDseWtTqPropRear 0;
BA_ "GenSigStartValue" SG_ 427 XcuDseWtTqPropRear 8000;
BA_ "GenSigSendType" SG_ 427 XcuHvilDuty 0;
BA_ "GenSigSendType" SG_ 427 XcuLvBatt3Volt 0;
BA_ "GenSigSendType" SG_ 427 XcuPtSnr5v 0;
BA_ "GenSigSendType" SG_ 427 XcuPwmFanDuty 0;
BA_ "GenSigSendType" SG_ 427 XcuReslovSplyVolt 0;
BA_ "GenSigSendType" SG_ 427 XcuSfCEstWhTqFrntBrkTq 0;
BA_ "GenSigStartValue" SG_ 427 XcuSfCEstWhTqFrntBrkTq 8000;
BA_ "GenSigSendType" SG_ 427 XcuSfCEstWhTqFrntPropTq 0;
BA_ "GenSigStartValue" SG_ 427 XcuSfCEstWhTqFrntPropTq 8000;
BA_ "GenSigSendType" SG_ 427 XcuSfCEstWhTqReBrkTq 0;
BA_ "GenSigStartValue" SG_ 427 XcuSfCEstWhTqReBrkTq 8000;
BA_ "GenSigSendType" SG_ 427 XcuSfCEstWhTqRePropTq 0;
BA_ "GenSigStartValue" SG_ 427 XcuSfCEstWhTqRePropTq 8000;
BA_ "GenSigSendType" SG_ 427 XcuVcc5VSnr 0;
BA_ "GenSigSendType" SG_ 427 XcuVcc5vLsd 0;
BA_ "GenSigSendType" SG_ 427 XcuVqco5vT35584 0;
BA_ "GenSigSendType" SG_ 427 XcuVqt15vT35584 0;
BA_ "GenSigSendType" SG_ 427 XcuVqt25vT35584 0;
BA_ "GenSigSendType" SG_ 427 XcuVquc5vT35584 0;
BA_ "GenSigSendType" SG_ 427 XcuVqvr5vT35584 0;
BA_ "GenSigSendType" SG_ 427 XcuWakeupReqSrc 0;
BA_ "GenSigSendType" SG_ 1379 ZCUPdevelpsignalgroupRespFunctiondevpsignalgroup1 1;
BA_ "GenSigSendType" SG_ 1379 ZCUPdevelpsignalgroupRespFunctiondevpsignalgroup2 1;
BA_ "GenSigSendType" SG_ 1379 ZCUPdevelpsignalgroupRespFunctiondevpsignalgroup3 1;
BA_ "GenSigSendType" SG_ 1379 ZCUPdevelpsignalgroupRespFunctiondevpsignalgroup4 1;
BA_ "GenSigSendType" SG_ 1379 ZCUPdevelpsignalgroupRespFunctiondevpsignalgroup5 1;
BA_ "GenSigSendType" SG_ 1379 ZCUPdevelpsignalgroupRespFunctiondevpsignalgroup6 1;
BA_ "GenSigSendType" SG_ 1379 ZCUPdevelpsignalgroupRespFunctiondevpsignalgroup7 1;
BA_ "GenSigSendType" SG_ 1379 ZCUPdevelpsignalgroupRespFunctiondevpsignalgroup8 1;
VAL_ 427 ActnOfHiBeamDrv 0 "OnOff1_Off" 1 "OnOff1_On";
VAL_ 427 ActnOfLedPosnLamp 0 "OnOff1_Off" 1 "OnOff1_On";
VAL_ 427 ActnOfLedStopLampActnOfLedStopLamp 0 "OnOff1_Off" 1 "OnOff1_On";
VAL_ 427 ActnOfLoBeamDrvOnOff 0 "OnOff1_Off" 1 "OnOff1_On";
VAL_ 427 ActnOfStopLampDrv 0 "OnOff1_Off" 1 "OnOff1_On";
VAL_ 427 ActnOfStopLampPass 0 "OnOff1_Off" 1 "OnOff1_On";
VAL_ 427 ActvnOfAhbc 0 "OnOff1_Off" 1 "OnOff1_On";
VAL_ 427 ActvnOfRvsg 0 "OnOff1_Off" 1 "OnOff1_On";
VAL_ 427 AntithftActvnReq 0 "OnOff1_Off" 1 "OnOff1_On";
VAL_ 427 BattLoStsKey0 0 "KeyBattStsUkwn" 1 "KeyBattStsOk" 2 "KeyBattStsLo";
VAL_ 427 BattLoStsKey1 0 "KeyBattStsUkwn" 1 "KeyBattStsOk" 2 "KeyBattStsLo";
VAL_ 427 BattLoStsKey10 0 "KeyBattStsUkwn" 1 "KeyBattStsOk" 2 "KeyBattStsLo";
VAL_ 427 BattLoStsKey11 0 "KeyBattStsUkwn" 1 "KeyBattStsOk" 2 "KeyBattStsLo";
VAL_ 427 BattLoStsKey2 0 "KeyBattStsUkwn" 1 "KeyBattStsOk" 2 "KeyBattStsLo";
VAL_ 427 BattLoStsKey3 0 "KeyBattStsUkwn" 1 "KeyBattStsOk" 2 "KeyBattStsLo";
VAL_ 427 BattLoStsKey4 0 "KeyBattStsUkwn" 1 "KeyBattStsOk" 2 "KeyBattStsLo";
VAL_ 427 BattLoStsKey5 0 "KeyBattStsUkwn" 1 "KeyBattStsOk" 2 "KeyBattStsLo";
VAL_ 427 BattLoStsKey6 0 "KeyBattStsUkwn" 1 "KeyBattStsOk" 2 "KeyBattStsLo";
VAL_ 427 BattLoStsKey7 0 "KeyBattStsUkwn" 1 "KeyBattStsOk" 2 "KeyBattStsLo";
VAL_ 427 BattLoStsKey8 0 "KeyBattStsUkwn" 1 "KeyBattStsOk" 2 "KeyBattStsLo";
VAL_ 427 BattLoStsKey9 0 "KeyBattStsUkwn" 1 "KeyBattStsOk" 2 "KeyBattStsLo";
VAL_ 427 BexvStsExvBlkErr 0 "Err1_NoErr" 1 "Err1_Err";
VAL_ 427 BexvStsExvCalibSts 0 "ExvCalibSts_NotInitialized" 1 "ExvCalibSts_InitializationInProcess" 2 "ExvCalibSts_Initialized" 3 "ExvCalibSts_Reserved";
VAL_ 427 BexvStsExvElecStsErr 0 "ExvElecStsErr_NoError" 1 "ExvElecStsErr_OpenCircuit" 2 "ExvElecStsErr_ShortCircuit" 3 "ExvElecStsErr_OverTemperatureShutdown" 4 "ExvElecStsErr_IndeterminateElectricFault" 5 "ExvElecStsErr_Reserved";
VAL_ 427 BexvStsExvMovSts 0 "ExvMovSts_NotMove" 1 "ExvMovSts_Moving";
VAL_ 427 BexvStsExvOvrTempErr 0 "Err1_NoErr" 1 "Err1_Err";
VAL_ 427 BexvStsExvOvrTrvlErr 0 "Err1_NoErr" 1 "Err1_Err";
VAL_ 427 BexvStsExvPreHeatgSts 0 "OnOff1_Off" 1 "OnOff1_On";
VAL_ 427 BexvStsExvVoltgRangErr 0 "VoltgRangErr_NoErr" 1 "VoltgRangErr_UnderVoltageErr" 2 "VoltgRangErr_OverVoltageErr" 3 "VoltgRangErr_Reserved";
VAL_ 427 BLEKeyBtnTrStsAndKeyIdBLEBtnSts 0 "BLEBtnSts_NotPsd" 1 "BLEBtnSts_ShoPsd" 2 "BLEBtnSts_LongPsd";
VAL_ 427 BLEKeyBtnTrStsAndKeyIdKeyId3 0 "KeyId3_Key0" 1 "KeyId3_Key1" 2 "KeyId3_Key2" 3 "KeyId3_Key3" 4 "KeyId3_Key4" 5 "KeyId3_Key5" 6 "KeyId3_Key6" 7 "KeyId3_Key7" 8 "KeyId3_Key8" 9 "KeyId3_Key9" 10 "KeyId3_Key10" 11 "KeyId3_Key11" 12 "KeyId3_Key12" 13 "KeyId3_Key13" 14 "KeyId3_Key14" 15 "KeyId3_Key15";
VAL_ 427 BLEKeyReadStsToKeyRmnWrnKey0 0 "KeyPrsntSts1_KeyPrsntStsIdle" 1 "KeyPrsntSts1_KeyPrsntStsInProgs" 2 "KeyPrsntSts1_KeyPrsntStsNotPrsnt" 3 "KeyPrsntSts1_KeyPrsntStsPrsnt";
VAL_ 427 BLEKeyReadStsToKeyRmnWrnKey1 0 "KeyPrsntSts1_KeyPrsntStsIdle" 1 "KeyPrsntSts1_KeyPrsntStsInProgs" 2 "KeyPrsntSts1_KeyPrsntStsNotPrsnt" 3 "KeyPrsntSts1_KeyPrsntStsPrsnt";
VAL_ 427 BLEKeyReadStsToKeyRmnWrnKey10 0 "KeyPrsntSts1_KeyPrsntStsIdle" 1 "KeyPrsntSts1_KeyPrsntStsInProgs" 2 "KeyPrsntSts1_KeyPrsntStsNotPrsnt" 3 "KeyPrsntSts1_KeyPrsntStsPrsnt";
VAL_ 427 BLEKeyReadStsToKeyRmnWrnKey11 0 "KeyPrsntSts1_KeyPrsntStsIdle" 1 "KeyPrsntSts1_KeyPrsntStsInProgs" 2 "KeyPrsntSts1_KeyPrsntStsNotPrsnt" 3 "KeyPrsntSts1_KeyPrsntStsPrsnt";
VAL_ 427 BLEKeyReadStsToKeyRmnWrnKey12 0 "KeyPrsntSts1_KeyPrsntStsIdle" 1 "KeyPrsntSts1_KeyPrsntStsInProgs" 2 "KeyPrsntSts1_KeyPrsntStsNotPrsnt" 3 "KeyPrsntSts1_KeyPrsntStsPrsnt";
VAL_ 427 BLEKeyReadStsToKeyRmnWrnKey13 0 "KeyPrsntSts1_KeyPrsntStsIdle" 1 "KeyPrsntSts1_KeyPrsntStsInProgs" 2 "KeyPrsntSts1_KeyPrsntStsNotPrsnt" 3 "KeyPrsntSts1_KeyPrsntStsPrsnt";
VAL_ 427 BLEKeyReadStsToKeyRmnWrnKey14 0 "KeyPrsntSts1_KeyPrsntStsIdle" 1 "KeyPrsntSts1_KeyPrsntStsInProgs" 2 "KeyPrsntSts1_KeyPrsntStsNotPrsnt" 3 "KeyPrsntSts1_KeyPrsntStsPrsnt";
VAL_ 427 BLEKeyReadStsToKeyRmnWrnKey15 0 "KeyPrsntSts1_KeyPrsntStsIdle" 1 "KeyPrsntSts1_KeyPrsntStsInProgs" 2 "KeyPrsntSts1_KeyPrsntStsNotPrsnt" 3 "KeyPrsntSts1_KeyPrsntStsPrsnt";
VAL_ 427 BLEKeyReadStsToKeyRmnWrnKey2 0 "KeyPrsntSts1_KeyPrsntStsIdle" 1 "KeyPrsntSts1_KeyPrsntStsInProgs" 2 "KeyPrsntSts1_KeyPrsntStsNotPrsnt" 3 "KeyPrsntSts1_KeyPrsntStsPrsnt";
VAL_ 427 BLEKeyReadStsToKeyRmnWrnKey3 0 "KeyPrsntSts1_KeyPrsntStsIdle" 1 "KeyPrsntSts1_KeyPrsntStsInProgs" 2 "KeyPrsntSts1_KeyPrsntStsNotPrsnt" 3 "KeyPrsntSts1_KeyPrsntStsPrsnt";
VAL_ 427 BLEKeyReadStsToKeyRmnWrnKey4 0 "KeyPrsntSts1_KeyPrsntStsIdle" 1 "KeyPrsntSts1_KeyPrsntStsInProgs" 2 "KeyPrsntSts1_KeyPrsntStsNotPrsnt" 3 "KeyPrsntSts1_KeyPrsntStsPrsnt";
VAL_ 427 BLEKeyReadStsToKeyRmnWrnKey5 0 "KeyPrsntSts1_KeyPrsntStsIdle" 1 "KeyPrsntSts1_KeyPrsntStsInProgs" 2 "KeyPrsntSts1_KeyPrsntStsNotPrsnt" 3 "KeyPrsntSts1_KeyPrsntStsPrsnt";
VAL_ 427 BLEKeyReadStsToKeyRmnWrnKey6 0 "KeyPrsntSts1_KeyPrsntStsIdle" 1 "KeyPrsntSts1_KeyPrsntStsInProgs" 2 "KeyPrsntSts1_KeyPrsntStsNotPrsnt" 3 "KeyPrsntSts1_KeyPrsntStsPrsnt";
VAL_ 427 BLEKeyReadStsToKeyRmnWrnKey7 0 "KeyPrsntSts1_KeyPrsntStsIdle" 1 "KeyPrsntSts1_KeyPrsntStsInProgs" 2 "KeyPrsntSts1_KeyPrsntStsNotPrsnt" 3 "KeyPrsntSts1_KeyPrsntStsPrsnt";
VAL_ 427 BLEKeyReadStsToKeyRmnWrnKey8 0 "KeyPrsntSts1_KeyPrsntStsIdle" 1 "KeyPrsntSts1_KeyPrsntStsInProgs" 2 "KeyPrsntSts1_KeyPrsntStsNotPrsnt" 3 "KeyPrsntSts1_KeyPrsntStsPrsnt";
VAL_ 427 BLEKeyReadStsToKeyRmnWrnKey9 0 "KeyPrsntSts1_KeyPrsntStsIdle" 1 "KeyPrsntSts1_KeyPrsntStsInProgs" 2 "KeyPrsntSts1_KeyPrsntStsNotPrsnt" 3 "KeyPrsntSts1_KeyPrsntStsPrsnt";
VAL_ 427 BLEKeyReadStsToVMMKey0 0 "KeyPrsntSts1_KeyPrsntStsIdle" 1 "KeyPrsntSts1_KeyPrsntStsInProgs" 2 "KeyPrsntSts1_KeyPrsntStsNotPrsnt" 3 "KeyPrsntSts1_KeyPrsntStsPrsnt";
VAL_ 427 BLEKeyReadStsToVMMKey1 0 "KeyPrsntSts1_KeyPrsntStsIdle" 1 "KeyPrsntSts1_KeyPrsntStsInProgs" 2 "KeyPrsntSts1_KeyPrsntStsNotPrsnt" 3 "KeyPrsntSts1_KeyPrsntStsPrsnt";
VAL_ 427 BLEKeyReadStsToVMMKey10 0 "KeyPrsntSts1_KeyPrsntStsIdle" 1 "KeyPrsntSts1_KeyPrsntStsInProgs" 2 "KeyPrsntSts1_KeyPrsntStsNotPrsnt" 3 "KeyPrsntSts1_KeyPrsntStsPrsnt";
VAL_ 427 BLEKeyReadStsToVMMKey11 0 "KeyPrsntSts1_KeyPrsntStsIdle" 1 "KeyPrsntSts1_KeyPrsntStsInProgs" 2 "KeyPrsntSts1_KeyPrsntStsNotPrsnt" 3 "KeyPrsntSts1_KeyPrsntStsPrsnt";
VAL_ 427 BLEKeyReadStsToVMMKey12 0 "KeyPrsntSts1_KeyPrsntStsIdle" 1 "KeyPrsntSts1_KeyPrsntStsInProgs" 2 "KeyPrsntSts1_KeyPrsntStsNotPrsnt" 3 "KeyPrsntSts1_KeyPrsntStsPrsnt";
VAL_ 427 BLEKeyReadStsToVMMKey13 0 "KeyPrsntSts1_KeyPrsntStsIdle" 1 "KeyPrsntSts1_KeyPrsntStsInProgs" 2 "KeyPrsntSts1_KeyPrsntStsNotPrsnt" 3 "KeyPrsntSts1_KeyPrsntStsPrsnt";
VAL_ 427 BLEKeyReadStsToVMMKey14 0 "KeyPrsntSts1_KeyPrsntStsIdle" 1 "KeyPrsntSts1_KeyPrsntStsInProgs" 2 "KeyPrsntSts1_KeyPrsntStsNotPrsnt" 3 "KeyPrsntSts1_KeyPrsntStsPrsnt";
VAL_ 427 BLEKeyReadStsToVMMKey15 0 "KeyPrsntSts1_KeyPrsntStsIdle" 1 "KeyPrsntSts1_KeyPrsntStsInProgs" 2 "KeyPrsntSts1_KeyPrsntStsNotPrsnt" 3 "KeyPrsntSts1_KeyPrsntStsPrsnt";
VAL_ 427 BLEKeyReadStsToVMMKey2 0 "KeyPrsntSts1_KeyPrsntStsIdle" 1 "KeyPrsntSts1_KeyPrsntStsInProgs" 2 "KeyPrsntSts1_KeyPrsntStsNotPrsnt" 3 "KeyPrsntSts1_KeyPrsntStsPrsnt";
VAL_ 427 BLEKeyReadStsToVMMKey3 0 "KeyPrsntSts1_KeyPrsntStsIdle" 1 "KeyPrsntSts1_KeyPrsntStsInProgs" 2 "KeyPrsntSts1_KeyPrsntStsNotPrsnt" 3 "KeyPrsntSts1_KeyPrsntStsPrsnt";
VAL_ 427 BLEKeyReadStsToVMMKey4 0 "KeyPrsntSts1_KeyPrsntStsIdle" 1 "KeyPrsntSts1_KeyPrsntStsInProgs" 2 "KeyPrsntSts1_KeyPrsntStsNotPrsnt" 3 "KeyPrsntSts1_KeyPrsntStsPrsnt";
VAL_ 427 BLEKeyReadStsToVMMKey5 0 "KeyPrsntSts1_KeyPrsntStsIdle" 1 "KeyPrsntSts1_KeyPrsntStsInProgs" 2 "KeyPrsntSts1_KeyPrsntStsNotPrsnt" 3 "KeyPrsntSts1_KeyPrsntStsPrsnt";
VAL_ 427 BLEKeyReadStsToVMMKey6 0 "KeyPrsntSts1_KeyPrsntStsIdle" 1 "KeyPrsntSts1_KeyPrsntStsInProgs" 2 "KeyPrsntSts1_KeyPrsntStsNotPrsnt" 3 "KeyPrsntSts1_KeyPrsntStsPrsnt";
VAL_ 427 BLEKeyReadStsToVMMKey7 0 "KeyPrsntSts1_KeyPrsntStsIdle" 1 "KeyPrsntSts1_KeyPrsntStsInProgs" 2 "KeyPrsntSts1_KeyPrsntStsNotPrsnt" 3 "KeyPrsntSts1_KeyPrsntStsPrsnt";
VAL_ 427 BLEKeyReadStsToVMMKey8 0 "KeyPrsntSts1_KeyPrsntStsIdle" 1 "KeyPrsntSts1_KeyPrsntStsInProgs" 2 "KeyPrsntSts1_KeyPrsntStsNotPrsnt" 3 "KeyPrsntSts1_KeyPrsntStsPrsnt";
VAL_ 427 BLEKeyReadStsToVMMKey9 0 "KeyPrsntSts1_KeyPrsntStsIdle" 1 "KeyPrsntSts1_KeyPrsntStsInProgs" 2 "KeyPrsntSts1_KeyPrsntStsNotPrsnt" 3 "KeyPrsntSts1_KeyPrsntStsPrsnt";
VAL_ 427 BtnErsReq 0 "ErsCmd_ErsCmdNotSet" 1 "ErsCmd_ErsCmdOn" 2 "ErsCmd_ErsCmdOff";
VAL_ 427 BtnTrSts 0 "PsdNotPsd1_NotPsd" 1 "PsdNotPsd1_Psd";
VAL_ 427 CarLoctrAcoustReq 0 "AlrmAcoustReq_AlrmAcoustReqOff" 1 "AlrmAcoustReq_AlrmAcoustReq1";
VAL_ 427 CarLoctrAcoustSts 0 "Boolean_FALSE" 1 "Boolean_TRUE";
VAL_ 427 CarLoctrExtrLiSts 0 "Boolean_FALSE" 1 "Boolean_TRUE";
VAL_ 427 ChrgHndlStrtEna 0 "ChrgHndlStrtEna_PwrUpNotEna" 1 "ChrgHndlStrtEna_PwrUpEna";
VAL_ 427 VoltKL15 0 "OnOff1_Off" 1 "OnOff1_On";
VAL_ 922 BtnStsOHCIntrLiSwtAllOnSts 0 "BtnStsSngTyp_Idle" 1 "BtnStsSngTyp_BtnPsd";
VAL_ 922 BtnStsOHCIntrLiSwtAutOnSts 0 "BtnStsSngTyp_Idle" 1 "BtnStsSngTyp_BtnPsd";
VAL_ 922 BtnStsOHCLiBtnReadingLe 0 "BtnStsSngTyp_Idle" 1 "BtnStsSngTyp_BtnPsd";
VAL_ 922 BtnStsOHCLiBtnReadingRi 0 "BtnStsSngTyp_Idle" 1 "BtnStsSngTyp_BtnPsd";
VAL_ 922 BtnStsOHCRLiBtnReadingLe 0 "BtnStsSngTyp_Idle" 1 "BtnStsSngTyp_BtnPsd";
VAL_ 922 BtnStsOHCRLiBtnReadingRi 0 "BtnStsSngTyp_Idle" 1 "BtnStsSngTyp_BtnPsd";
VAL_ 922 BtnStsOHTRLiBtnReadingLe 0 "BtnStsSngTyp_Idle" 1 "BtnStsSngTyp_BtnPsd";
VAL_ 922 BtnStsOHTRLiBtnReadingRi 0 "BtnStsSngTyp_Idle" 1 "BtnStsSngTyp_BtnPsd";
VAL_ 922 IntrLiCmdGroupIntrLiActvn 0 "Boolean_FALSE" 1 "Boolean_TRUE";
VAL_ 922 IntrLiCmdGroupIntrLiRoofDim 0 "Boolean_FALSE" 1 "Boolean_TRUE";
VAL_ 922 IntrLiCmdGroupIntrLiRoofDmdOff 0 "Boolean_FALSE" 1 "Boolean_TRUE";
VAL_ 922 IntrMirrRespIntrMirrIntFailr 0 "FailrNoFailr1_NoFailr" 1 "FailrNoFailr1_Failr";
VAL_ 922 IntrMirrRespResdBoolean 0 "Boolean_FALSE" 1 "Boolean_TRUE";
VAL_ 922 LiLvrDiagc 0 "LiLvrDiagc_LiLvrNotConnect" 1 "LiLvrDiagc_LiLvrBtnStuck" 2 "LiLvrDiagc_LiLvrSwtUndefd" 3 "LiLvrDiagc_LiLvrOk";
VAL_ 922 OHCFrBtnErrStsIntrLiSwtAllOnSts 0 "BtnStsSngTyp_Idle" 1 "BtnStsSngTyp_BtnPsd";
VAL_ 922 OHCFrBtnErrStsIntrLiSwtAutOnSts 0 "BtnStsSngTyp_Idle" 1 "BtnStsSngTyp_BtnPsd";
VAL_ 922 OHCFrBtnErrStsLiBtnReadingLe 0 "BtnStsSngTyp_Idle" 1 "BtnStsSngTyp_BtnPsd";
VAL_ 922 OHCFrBtnErrStsLiBtnReadingRi 0 "BtnStsSngTyp_Idle" 1 "BtnStsSngTyp_BtnPsd";
VAL_ 922 OHCSecRowBtnErrStsLiBtnReadingLe 0 "BtnStsSngTyp_Idle" 1 "BtnStsSngTyp_BtnPsd";
VAL_ 922 OHCSecRowBtnErrStsLiBtnReadingRi 0 "BtnStsSngTyp_Idle" 1 "BtnStsSngTyp_BtnPsd";
VAL_ 922 OHCThirdRowBtnErrStsLiBtnReadingLe 0 "BtnStsSngTyp_Idle" 1 "BtnStsSngTyp_BtnPsd";
VAL_ 922 OHCThirdRowBtnErrStsLiBtnReadingRi 0 "BtnStsSngTyp_Idle" 1 "BtnStsSngTyp_BtnPsd";
VAL_ 922 RainSnsrDiagcRainSnsrHiTDetd 0 "OnOff1_Off" 1 "OnOff1_On";
VAL_ 922 RainSnsrDiagcRainSnsrHiVoltDetd 0 "OnOff1_Off" 1 "OnOff1_On";
VAL_ 922 RainSnsrErrCalErr 0 "OnOff1_Off" 1 "OnOff1_On";
VAL_ 922 RainSnsrErrCalErrActv 0 "OnOff1_Off" 1 "OnOff1_On";
VAL_ 922 RainSnsrErrRainDetnErr 0 "OnOff1_Off" 1 "OnOff1_On";
VAL_ 922 RainSnsrErrRainDetnErrActv 0 "OnOff1_Off" 1 "OnOff1_On";
VAL_ 922 ReadLiErrStsReadLiStsFirstRowLe 0 "Boolean_FALSE" 1 "Boolean_TRUE";
VAL_ 922 ReadLiErrStsReadLiStsFirstRowRi 0 "Boolean_FALSE" 1 "Boolean_TRUE";
VAL_ 922 ReadLiErrStsReadLiStsSecondRowLe 0 "Boolean_FALSE" 1 "Boolean_TRUE";
VAL_ 922 ReadLiErrStsReadLiStsSecondRowRi 0 "Boolean_FALSE" 1 "Boolean_TRUE";
VAL_ 922 ReadLiErrStsReadLiStsThirdRowLe 0 "Boolean_FALSE" 1 "Boolean_TRUE";
VAL_ 922 ReadLiErrStsReadLiStsThirdRowRi 0 "Boolean_FALSE" 1 "Boolean_TRUE";
VAL_ 922 StsOfLogoFolwLoBeam 0 "DevSts4_Off" 1 "DevSts4_On" 2 "DevSts4_Err" 3 "DevSts4_Resd";
VAL_ 922 WipgAutFrntMod 0 "WipgAutFrntMod_Off" 1 "WipgAutFrntMod_ImdtMod" 2 "WipgAutFrntMod_IntlMod" 3 "WipgAutFrntMod_ContnsMod";
VAL_ 922 WiprLvrDiagc 0 "WiprLvrDiagcTyp_WiprLvrNotConnect" 1 "WiprLvrDiagcTyp_WiprLvrBtnStuck" 2 "WiprLvrDiagcTyp_WiprLvrSwtundefd" 3 "WiprLvrDiagcTyp_WiprLvrOk";
VAL_ 431 CmprSpdIncrReq 0 "Validity_NotValid" 1 "Validity_Valid";
VAL_ 431 DecUsgModAut 0 "OnOff1_Off" 1 "OnOff1_On";
VAL_ 431 DecUsgModAut2 0 "OnOff1_Off" 1 "OnOff1_On";
VAL_ 431 DigKeyIntrVldDetd 0 "Boolean_FALSE" 1 "Boolean_TRUE";
VAL_ 431 DlyClsReq 0 "ReqSts1_NotReqd" 1 "ReqSts1_Reqd";
VAL_ 431 DoorDrvrAcsKeylsReq 0 "LockgCenReq2_Idle" 1 "LockgCenReq2_Unlck" 2 "LockgCenReq2_Lock";
VAL_ 431 DoorDrvrAcsKeylsSts 0 "PsdNotPsd1_NotPsd" 1 "PsdNotPsd1_Psd";
VAL_ 431 DoorDrvrHndlCmd 0 "DoorHndlCmd_Idle" 1 "DoorHndlCmd_Deploy" 2 "DoorHndlCmd_Retract";
VAL_ 431 DoorDrvrOpenLowReqOutdSwt1 0 "PsdNotPsd3_NoInfo1" 1 "PsdNotPsd3_Psd" 2 "PsdNotPsd3_NotPsd" 3 "PsdNotPsd3_NoInfo2";
VAL_ 431 DoorDrvrOpenReqInsdSwt1 0 "PsdNotPsd3_NoInfo1" 1 "PsdNotPsd3_Psd" 2 "PsdNotPsd3_NotPsd" 3 "PsdNotPsd3_NoInfo2";
VAL_ 431 DoorDrvrRelsReq 0 "OnOffSafe1_OnOffSafeInvld1" 1 "OnOffSafe1_OnOffSafeOn" 2 "OnOffSafe1_OnOffSafeOff" 3 "OnOffSafe1_OnOffSafeInvld2";
VAL_ 431 DoorLeReAcsKeylsReq 0 "LockgCenReq2_Idle" 1 "LockgCenReq2_Unlck" 2 "LockgCenReq2_Lock";
VAL_ 431 DoorLeReAcsKeylsSts 0 "PsdNotPsd1_NotPsd" 1 "PsdNotPsd1_Psd";
VAL_ 431 DoorLeReOpenLowReqOutdSwt1 0 "PsdNotPsd3_NoInfo1" 1 "PsdNotPsd3_Psd" 2 "PsdNotPsd3_NotPsd" 3 "PsdNotPsd3_NoInfo2";
VAL_ 431 DoorLeReOpenReqInsdSwt1 0 "PsdNotPsd3_NoInfo1" 1 "PsdNotPsd3_Psd" 2 "PsdNotPsd3_NotPsd" 3 "PsdNotPsd3_NoInfo2";
VAL_ 431 DoorPassAcsKeylsReq 0 "LockgCenReq2_Idle" 1 "LockgCenReq2_Unlck" 2 "LockgCenReq2_Lock";
VAL_ 431 DoorPassAcsKeylsSts 0 "PsdNotPsd1_NotPsd" 1 "PsdNotPsd1_Psd";
VAL_ 431 DoorRiReAcsKeylsReq 0 "LockgCenReq2_Idle" 1 "LockgCenReq2_Unlck" 2 "LockgCenReq2_Lock";
VAL_ 431 DoorRiReAcsKeylsSts 0 "PsdNotPsd1_NotPsd" 1 "PsdNotPsd1_Psd";
VAL_ 431 DrvrIntrLockSngSwt 0 "PsdNotPsd1_NotPsd" 1 "PsdNotPsd1_Psd";
VAL_ 431 EasyInOutDrvrReq 0 "EasyInOutDrvrReq_Idle" 1 "EasyInOutDrvrReq_Move" 2 "EasyInOutDrvrReq_Reset";
VAL_ 431 EngActvnMod1WdReq 0 "EngActvnMod1_WakeupFunctionNOTActiveANDExternalRequestNOTPresent" 1 "EngActvnMod1_WakeupFunctionNOTActiveANDExternalRequestPresent" 2 "EngActvnMod1_WakeupFunctionActiveANDExternalRequestNOTPresent" 3 "EngActvnMod1_WakeupFunctionActiveANDExternalRequestPresent";
VAL_ 431 ErsLockReqByKey 0 "Boolean_FALSE" 1 "Boolean_TRUE";
VAL_ 431 FacQlyForDoorDrvrSts 0 "GenQf1_UndefindDataAccur" 1 "GenQf1_TmpUndefdData" 2 "GenQf1_DataAccurNotWithinSpcn" 3 "GenQf1_AccurData";
VAL_ 431 FbOfPrkgLiShow 0 "FbOfPrkgLiShow_Off" 1 "FbOfPrkgLiShow_OnStatic" 2 "FbOfPrkgLiShow_OnDynamic" 3 "FbOfPrkgLiShow_Error";
VAL_ 431 GlvBoxIntrSwtSts 0 "PsdNotPsd1_NotPsd" 1 "PsdNotPsd1_Psd";
VAL_ 431 GrlAutoCalibReq 0 "Boolean_FALSE" 1 "Boolean_TRUE";
VAL_ 431 GrlHldTrqActive 0 "Boolean_FALSE" 1 "Boolean_TRUE";
VAL_ 431 GrlShttrDmdShttrCalEna 0 "ShttrCalEna_ShttrCalNotEnad" 1 "ShttrCalEna_ShttrCalEnad";
VAL_ 431 GrlShttrMoveActive 0 "VlvRunSts_NotMoving" 1 "VlvRunSts_Moving";
VAL_ 431 GrlShttrStsShttrActrFlt 0 "ShttrActrFlt_ShttrActrNoFlt" 1 "ShttrActrFlt_ShttrActrFlt";
VAL_ 431 GrlShttrStsShttrBlkd 0 "ShttrBlkd_ShttrNotBlkd" 1 "ShttrBlkd_ShttrBlkd";
VAL_ 431 GrlShttrStsShttrCalActv 0 "ShttrCalActv_NotActv" 1 "ShttrCalActv_Actv";
VAL_ 431 GrlShttrStsShttrCalIndcd 0 "ShttrCalIndcd_ShttrCalNotIndcd" 1 "ShttrCalIndcd_ShttrCalIndcd";
VAL_ 431 GrlShttrStsShttrElecErr 0 "ShttrElecErr_ShttrNoElecErr" 1 "ShttrElecErr_ShttrElecErr";
VAL_ 431 GrlShttrStsShttrSnsrFlt 0 "ShttrSnsrFlt_ShttrSnsrNoFlt" 1 "ShttrSnsrFlt_ShttrSnsrFlt";
VAL_ 431 GrlShttrStsShttrTErr 0 "ShttrTErr_ShttrTNoErr" 1 "ShttrTErr_ShttrTErr";
VAL_ 431 GrlShttrStsShttrULoErr 0 "ShttrULoErr_ShttrNoULoErr" 1 "ShttrULoErr_ShttrULoErr";
VAL_ 431 HoodSwt1 0 "DoorSts2_Ukwn" 1 "DoorSts2_Opend" 2 "DoorSts2_Clsd";
VAL_ 431 KeyDiReqKey0 0 "OnOff1_Off" 1 "OnOff1_On";
VAL_ 431 KeyDiReqKey1 0 "OnOff1_Off" 1 "OnOff1_On";
VAL_ 431 KeyDiReqKey10 0 "OnOff1_Off" 1 "OnOff1_On";
VAL_ 431 KeyDiReqKey11 0 "OnOff1_Off" 1 "OnOff1_On";
VAL_ 431 KeyDiReqKey2 0 "OnOff1_Off" 1 "OnOff1_On";
VAL_ 431 KeyDiReqKey3 0 "OnOff1_Off" 1 "OnOff1_On";
VAL_ 431 KeyDiReqKey4 0 "OnOff1_Off" 1 "OnOff1_On";
VAL_ 431 KeyDiReqKey5 0 "OnOff1_Off" 1 "OnOff1_On";
VAL_ 431 KeyDiReqKey6 0 "OnOff1_Off" 1 "OnOff1_On";
VAL_ 431 KeyDiReqKey7 0 "OnOff1_Off" 1 "OnOff1_On";
VAL_ 431 KeyDiReqKey8 0 "OnOff1_Off" 1 "OnOff1_On";
VAL_ 431 KeyDiReqKey9 0 "OnOff1_Off" 1 "OnOff1_On";
VAL_ 431 KeyReadReqFromKeyRmn 0 "KeyLocn1_KeyLocnIdle" 1 "KeyLocn1_KeyLocnAll" 2 "KeyLocn1_KeyLocnAllExt" 3 "KeyLocn1_KeyLocnDrvrExt" 4 "KeyLocn1_KeyLocnPassExt" 5 "KeyLocn1_KeyLocnTrExt" 6 "KeyLocn1_KeyLocnAllInt" 7 "KeyLocn1_KeyLocnDrvrInt" 8 "KeyLocn1_KeyLocnPassInt" 9 "KeyLocn1_KeyLocnResvInt" 10 "KeyLocn1_KeyLocnResvIntSimple";
VAL_ 431 KeyReadReqFromKeyWarn 0 "KeyLocn1_KeyLocnIdle" 1 "KeyLocn1_KeyLocnAll" 2 "KeyLocn1_KeyLocnAllExt" 3 "KeyLocn1_KeyLocnDrvrExt" 4 "KeyLocn1_KeyLocnPassExt" 5 "KeyLocn1_KeyLocnTrExt" 6 "KeyLocn1_KeyLocnAllInt" 7 "KeyLocn1_KeyLocnDrvrInt" 8 "KeyLocn1_KeyLocnPassInt" 9 "KeyLocn1_KeyLocnResvInt" 10 "KeyLocn1_KeyLocnResvIntSimple";
VAL_ 431 KeyReadStsToKeyRmnKey0 0 "KeyPrsntSts1_KeyPrsntStsIdle" 1 "KeyPrsntSts1_KeyPrsntStsInProgs" 2 "KeyPrsntSts1_KeyPrsntStsNotPrsnt" 3 "KeyPrsntSts1_KeyPrsntStsPrsnt";
VAL_ 431 KeyReadStsToKeyRmnKey1 0 "KeyPrsntSts1_KeyPrsntStsIdle" 1 "KeyPrsntSts1_KeyPrsntStsInProgs" 2 "KeyPrsntSts1_KeyPrsntStsNotPrsnt" 3 "KeyPrsntSts1_KeyPrsntStsPrsnt";
VAL_ 431 KeyReadStsToKeyRmnKey10 0 "KeyPrsntSts1_KeyPrsntStsIdle" 1 "KeyPrsntSts1_KeyPrsntStsInProgs" 2 "KeyPrsntSts1_KeyPrsntStsNotPrsnt" 3 "KeyPrsntSts1_KeyPrsntStsPrsnt";
VAL_ 431 KeyReadStsToKeyRmnKey11 0 "KeyPrsntSts1_KeyPrsntStsIdle" 1 "KeyPrsntSts1_KeyPrsntStsInProgs" 2 "KeyPrsntSts1_KeyPrsntStsNotPrsnt" 3 "KeyPrsntSts1_KeyPrsntStsPrsnt";
VAL_ 431 KeyReadStsToKeyRmnKey2 0 "KeyPrsntSts1_KeyPrsntStsIdle" 1 "KeyPrsntSts1_KeyPrsntStsInProgs" 2 "KeyPrsntSts1_KeyPrsntStsNotPrsnt" 3 "KeyPrsntSts1_KeyPrsntStsPrsnt";
VAL_ 431 KeyReadStsToKeyRmnKey3 0 "KeyPrsntSts1_KeyPrsntStsIdle" 1 "KeyPrsntSts1_KeyPrsntStsInProgs" 2 "KeyPrsntSts1_KeyPrsntStsNotPrsnt" 3 "KeyPrsntSts1_KeyPrsntStsPrsnt";
VAL_ 431 KeyReadStsToKeyRmnKey4 0 "KeyPrsntSts1_KeyPrsntStsIdle" 1 "KeyPrsntSts1_KeyPrsntStsInProgs" 2 "KeyPrsntSts1_KeyPrsntStsNotPrsnt" 3 "KeyPrsntSts1_KeyPrsntStsPrsnt";
VAL_ 431 KeyReadStsToKeyRmnKey5 0 "KeyPrsntSts1_KeyPrsntStsIdle" 1 "KeyPrsntSts1_KeyPrsntStsInProgs" 2 "KeyPrsntSts1_KeyPrsntStsNotPrsnt" 3 "KeyPrsntSts1_KeyPrsntStsPrsnt";
VAL_ 431 KeyReadStsToKeyRmnKey6 0 "KeyPrsntSts1_KeyPrsntStsIdle" 1 "KeyPrsntSts1_KeyPrsntStsInProgs" 2 "KeyPrsntSts1_KeyPrsntStsNotPrsnt" 3 "KeyPrsntSts1_KeyPrsntStsPrsnt";
VAL_ 431 KeyReadStsToKeyRmnKey7 0 "KeyPrsntSts1_KeyPrsntStsIdle" 1 "KeyPrsntSts1_KeyPrsntStsInProgs" 2 "KeyPrsntSts1_KeyPrsntStsNotPrsnt" 3 "KeyPrsntSts1_KeyPrsntStsPrsnt";
VAL_ 431 KeyReadStsToKeyRmnKey8 0 "KeyPrsntSts1_KeyPrsntStsIdle" 1 "KeyPrsntSts1_KeyPrsntStsInProgs" 2 "KeyPrsntSts1_KeyPrsntStsNotPrsnt" 3 "KeyPrsntSts1_KeyPrsntStsPrsnt";
VAL_ 431 KeyReadStsToKeyRmnKey9 0 "KeyPrsntSts1_KeyPrsntStsIdle" 1 "KeyPrsntSts1_KeyPrsntStsInProgs" 2 "KeyPrsntSts1_KeyPrsntStsNotPrsnt" 3 "KeyPrsntSts1_KeyPrsntStsPrsnt";
VAL_ 431 KeyReadStsToKeyWarnKey0 0 "KeyPrsntSts1_KeyPrsntStsIdle" 1 "KeyPrsntSts1_KeyPrsntStsInProgs" 2 "KeyPrsntSts1_KeyPrsntStsNotPrsnt" 3 "KeyPrsntSts1_KeyPrsntStsPrsnt";
VAL_ 431 KeyReadStsToKeyWarnKey1 0 "KeyPrsntSts1_KeyPrsntStsIdle" 1 "KeyPrsntSts1_KeyPrsntStsInProgs" 2 "KeyPrsntSts1_KeyPrsntStsNotPrsnt" 3 "KeyPrsntSts1_KeyPrsntStsPrsnt";
VAL_ 431 KeyReadStsToKeyWarnKey10 0 "KeyPrsntSts1_KeyPrsntStsIdle" 1 "KeyPrsntSts1_KeyPrsntStsInProgs" 2 "KeyPrsntSts1_KeyPrsntStsNotPrsnt" 3 "KeyPrsntSts1_KeyPrsntStsPrsnt";
VAL_ 431 KeyReadStsToKeyWarnKey11 0 "KeyPrsntSts1_KeyPrsntStsIdle" 1 "KeyPrsntSts1_KeyPrsntStsInProgs" 2 "KeyPrsntSts1_KeyPrsntStsNotPrsnt" 3 "KeyPrsntSts1_KeyPrsntStsPrsnt";
VAL_ 431 KeyReadStsToKeyWarnKey2 0 "KeyPrsntSts1_KeyPrsntStsIdle" 1 "KeyPrsntSts1_KeyPrsntStsInProgs" 2 "KeyPrsntSts1_KeyPrsntStsNotPrsnt" 3 "KeyPrsntSts1_KeyPrsntStsPrsnt";
VAL_ 431 KeyReadStsToKeyWarnKey3 0 "KeyPrsntSts1_KeyPrsntStsIdle" 1 "KeyPrsntSts1_KeyPrsntStsInProgs" 2 "KeyPrsntSts1_KeyPrsntStsNotPrsnt" 3 "KeyPrsntSts1_KeyPrsntStsPrsnt";
VAL_ 431 KeyReadStsToKeyWarnKey4 0 "KeyPrsntSts1_KeyPrsntStsIdle" 1 "KeyPrsntSts1_KeyPrsntStsInProgs" 2 "KeyPrsntSts1_KeyPrsntStsNotPrsnt" 3 "KeyPrsntSts1_KeyPrsntStsPrsnt";
VAL_ 431 KeyReadStsToKeyWarnKey5 0 "KeyPrsntSts1_KeyPrsntStsIdle" 1 "KeyPrsntSts1_KeyPrsntStsInProgs" 2 "KeyPrsntSts1_KeyPrsntStsNotPrsnt" 3 "KeyPrsntSts1_KeyPrsntStsPrsnt";
VAL_ 431 KeyReadStsToKeyWarnKey6 0 "KeyPrsntSts1_KeyPrsntStsIdle" 1 "KeyPrsntSts1_KeyPrsntStsInProgs" 2 "KeyPrsntSts1_KeyPrsntStsNotPrsnt" 3 "KeyPrsntSts1_KeyPrsntStsPrsnt";
VAL_ 431 KeyReadStsToKeyWarnKey7 0 "KeyPrsntSts1_KeyPrsntStsIdle" 1 "KeyPrsntSts1_KeyPrsntStsInProgs" 2 "KeyPrsntSts1_KeyPrsntStsNotPrsnt" 3 "KeyPrsntSts1_KeyPrsntStsPrsnt";
VAL_ 431 KeyReadStsToKeyWarnKey8 0 "KeyPrsntSts1_KeyPrsntStsIdle" 1 "KeyPrsntSts1_KeyPrsntStsInProgs" 2 "KeyPrsntSts1_KeyPrsntStsNotPrsnt" 3 "KeyPrsntSts1_KeyPrsntStsPrsnt";
VAL_ 431 KeyReadStsToKeyWarnKey9 0 "KeyPrsntSts1_KeyPrsntStsIdle" 1 "KeyPrsntSts1_KeyPrsntStsInProgs" 2 "KeyPrsntSts1_KeyPrsntStsNotPrsnt" 3 "KeyPrsntSts1_KeyPrsntStsPrsnt";
VAL_ 431 KeyReadStsToVmmKey0 0 "KeyPrsntSts1_KeyPrsntStsIdle" 1 "KeyPrsntSts1_KeyPrsntStsInProgs" 2 "KeyPrsntSts1_KeyPrsntStsNotPrsnt" 3 "KeyPrsntSts1_KeyPrsntStsPrsnt";
VAL_ 431 KeyReadStsToVmmKey1 0 "KeyPrsntSts1_KeyPrsntStsIdle" 1 "KeyPrsntSts1_KeyPrsntStsInProgs" 2 "KeyPrsntSts1_KeyPrsntStsNotPrsnt" 3 "KeyPrsntSts1_KeyPrsntStsPrsnt";
VAL_ 431 KeyReadStsToVmmKey10 0 "KeyPrsntSts1_KeyPrsntStsIdle" 1 "KeyPrsntSts1_KeyPrsntStsInProgs" 2 "KeyPrsntSts1_KeyPrsntStsNotPrsnt" 3 "KeyPrsntSts1_KeyPrsntStsPrsnt";
VAL_ 431 KeyReadStsToVmmKey11 0 "KeyPrsntSts1_KeyPrsntStsIdle" 1 "KeyPrsntSts1_KeyPrsntStsInProgs" 2 "KeyPrsntSts1_KeyPrsntStsNotPrsnt" 3 "KeyPrsntSts1_KeyPrsntStsPrsnt";
VAL_ 431 KeyReadStsToVmmKey2 0 "KeyPrsntSts1_KeyPrsntStsIdle" 1 "KeyPrsntSts1_KeyPrsntStsInProgs" 2 "KeyPrsntSts1_KeyPrsntStsNotPrsnt" 3 "KeyPrsntSts1_KeyPrsntStsPrsnt";
VAL_ 431 KeyReadStsToVmmKey3 0 "KeyPrsntSts1_KeyPrsntStsIdle" 1 "KeyPrsntSts1_KeyPrsntStsInProgs" 2 "KeyPrsntSts1_KeyPrsntStsNotPrsnt" 3 "KeyPrsntSts1_KeyPrsntStsPrsnt";
VAL_ 431 KeyReadStsToVmmKey4 0 "KeyPrsntSts1_KeyPrsntStsIdle" 1 "KeyPrsntSts1_KeyPrsntStsInProgs" 2 "KeyPrsntSts1_KeyPrsntStsNotPrsnt" 3 "KeyPrsntSts1_KeyPrsntStsPrsnt";
VAL_ 431 KeyReadStsToVmmKey5 0 "KeyPrsntSts1_KeyPrsntStsIdle" 1 "KeyPrsntSts1_KeyPrsntStsInProgs" 2 "KeyPrsntSts1_KeyPrsntStsNotPrsnt" 3 "KeyPrsntSts1_KeyPrsntStsPrsnt";
VAL_ 431 KeyReadStsToVmmKey6 0 "KeyPrsntSts1_KeyPrsntStsIdle" 1 "KeyPrsntSts1_KeyPrsntStsInProgs" 2 "KeyPrsntSts1_KeyPrsntStsNotPrsnt" 3 "KeyPrsntSts1_KeyPrsntStsPrsnt";
VAL_ 431 KeyReadStsToVmmKey7 0 "KeyPrsntSts1_KeyPrsntStsIdle" 1 "KeyPrsntSts1_KeyPrsntStsInProgs" 2 "KeyPrsntSts1_KeyPrsntStsNotPrsnt" 3 "KeyPrsntSts1_KeyPrsntStsPrsnt";
VAL_ 431 KeyReadStsToVmmKey8 0 "KeyPrsntSts1_KeyPrsntStsIdle" 1 "KeyPrsntSts1_KeyPrsntStsInProgs" 2 "KeyPrsntSts1_KeyPrsntStsNotPrsnt" 3 "KeyPrsntSts1_KeyPrsntStsPrsnt";
VAL_ 431 KeyReadStsToVmmKey9 0 "KeyPrsntSts1_KeyPrsntStsIdle" 1 "KeyPrsntSts1_KeyPrsntStsInProgs" 2 "KeyPrsntSts1_KeyPrsntStsNotPrsnt" 3 "KeyPrsntSts1_KeyPrsntStsPrsnt";
VAL_ 431 KeyReadStsToVMMNFCKey0 0 "KeyPrsntSts1_KeyPrsntStsIdle" 1 "KeyPrsntSts1_KeyPrsntStsInProgs" 2 "KeyPrsntSts1_KeyPrsntStsNotPrsnt" 3 "KeyPrsntSts1_KeyPrsntStsPrsnt";
VAL_ 431 KeyReadStsToVMMNFCKey1 0 "KeyPrsntSts1_KeyPrsntStsIdle" 1 "KeyPrsntSts1_KeyPrsntStsInProgs" 2 "KeyPrsntSts1_KeyPrsntStsNotPrsnt" 3 "KeyPrsntSts1_KeyPrsntStsPrsnt";
VAL_ 431 KeyReadStsToVMMNFCKey10 0 "KeyPrsntSts1_KeyPrsntStsIdle" 1 "KeyPrsntSts1_KeyPrsntStsInProgs" 2 "KeyPrsntSts1_KeyPrsntStsNotPrsnt" 3 "KeyPrsntSts1_KeyPrsntStsPrsnt";
VAL_ 431 KeyReadStsToVMMNFCKey11 0 "KeyPrsntSts1_KeyPrsntStsIdle" 1 "KeyPrsntSts1_KeyPrsntStsInProgs" 2 "KeyPrsntSts1_KeyPrsntStsNotPrsnt" 3 "KeyPrsntSts1_KeyPrsntStsPrsnt";
VAL_ 431 KeyReadStsToVMMNFCKey12 0 "KeyPrsntSts1_KeyPrsntStsIdle" 1 "KeyPrsntSts1_KeyPrsntStsInProgs" 2 "KeyPrsntSts1_KeyPrsntStsNotPrsnt" 3 "KeyPrsntSts1_KeyPrsntStsPrsnt";
VAL_ 431 KeyReadStsToVMMNFCKey13 0 "KeyPrsntSts1_KeyPrsntStsIdle" 1 "KeyPrsntSts1_KeyPrsntStsInProgs" 2 "KeyPrsntSts1_KeyPrsntStsNotPrsnt" 3 "KeyPrsntSts1_KeyPrsntStsPrsnt";
VAL_ 431 KeyReadStsToVMMNFCKey14 0 "KeyPrsntSts1_KeyPrsntStsIdle" 1 "KeyPrsntSts1_KeyPrsntStsInProgs" 2 "KeyPrsntSts1_KeyPrsntStsNotPrsnt" 3 "KeyPrsntSts1_KeyPrsntStsPrsnt";
VAL_ 431 KeyReadStsToVMMNFCKey15 0 "KeyPrsntSts1_KeyPrsntStsIdle" 1 "KeyPrsntSts1_KeyPrsntStsInProgs" 2 "KeyPrsntSts1_KeyPrsntStsNotPrsnt" 3 "KeyPrsntSts1_KeyPrsntStsPrsnt";
VAL_ 431 KeyReadStsToVMMNFCKey2 0 "KeyPrsntSts1_KeyPrsntStsIdle" 1 "KeyPrsntSts1_KeyPrsntStsInProgs" 2 "KeyPrsntSts1_KeyPrsntStsNotPrsnt" 3 "KeyPrsntSts1_KeyPrsntStsPrsnt";
VAL_ 431 KeyReadStsToVMMNFCKey3 0 "KeyPrsntSts1_KeyPrsntStsIdle" 1 "KeyPrsntSts1_KeyPrsntStsInProgs" 2 "KeyPrsntSts1_KeyPrsntStsNotPrsnt" 3 "KeyPrsntSts1_KeyPrsntStsPrsnt";
VAL_ 431 KeyReadStsToVMMNFCKey4 0 "KeyPrsntSts1_KeyPrsntStsIdle" 1 "KeyPrsntSts1_KeyPrsntStsInProgs" 2 "KeyPrsntSts1_KeyPrsntStsNotPrsnt" 3 "KeyPrsntSts1_KeyPrsntStsPrsnt";
VAL_ 431 KeyReadStsToVMMNFCKey5 0 "KeyPrsntSts1_KeyPrsntStsIdle" 1 "KeyPrsntSts1_KeyPrsntStsInProgs" 2 "KeyPrsntSts1_KeyPrsntStsNotPrsnt" 3 "KeyPrsntSts1_KeyPrsntStsPrsnt";
VAL_ 431 KeyReadStsToVMMNFCKey6 0 "KeyPrsntSts1_KeyPrsntStsIdle" 1 "KeyPrsntSts1_KeyPrsntStsInProgs" 2 "KeyPrsntSts1_KeyPrsntStsNotPrsnt" 3 "KeyPrsntSts1_KeyPrsntStsPrsnt";
VAL_ 431 KeyReadStsToVMMNFCKey7 0 "KeyPrsntSts1_KeyPrsntStsIdle" 1 "KeyPrsntSts1_KeyPrsntStsInProgs" 2 "KeyPrsntSts1_KeyPrsntStsNotPrsnt" 3 "KeyPrsntSts1_KeyPrsntStsPrsnt";
VAL_ 431 KeyReadStsToVMMNFCKey8 0 "KeyPrsntSts1_KeyPrsntStsIdle" 1 "KeyPrsntSts1_KeyPrsntStsInProgs" 2 "KeyPrsntSts1_KeyPrsntStsNotPrsnt" 3 "KeyPrsntSts1_KeyPrsntStsPrsnt";
VAL_ 431 KeyReadStsToVMMNFCKey9 0 "KeyPrsntSts1_KeyPrsntStsIdle" 1 "KeyPrsntSts1_KeyPrsntStsInProgs" 2 "KeyPrsntSts1_KeyPrsntStsNotPrsnt" 3 "KeyPrsntSts1_KeyPrsntStsPrsnt";
VAL_ 431 LiOprnMod 0 "LiOperMod_Night" 1 "LiOperMod_Day" 2 "LiOperMod_Twli" 3 "LiOperMod_Tnl";
VAL_ 431 MobDeBtnCarLctrSts 0 "PsdNotPsd1_NotPsd" 1 "PsdNotPsd1_Psd";
VAL_ 431 MobDeBtnPanicAlarmSts 0 "OnOffNoReq_NoReq" 1 "OnOffNoReq_On" 2 "OnOffNoReq_Off";
VAL_ 431 MobDevAVPReq 0 "ReqSts1_NotReqd" 1 "ReqSts1_Reqd";
VAL_ 431 MobDevBtnLockStsAndKeyIdKeyId3 0 "KeyId3_Key0" 1 "KeyId3_Key1" 2 "KeyId3_Key2" 3 "KeyId3_Key3" 4 "KeyId3_Key4" 5 "KeyId3_Key5" 6 "KeyId3_Key6" 7 "KeyId3_Key7" 8 "KeyId3_Key8" 9 "KeyId3_Key9" 10 "KeyId3_Key10" 11 "KeyId3_Key11" 12 "KeyId3_Key12" 13 "KeyId3_Key13" 14 "KeyId3_Key14" 15 "KeyId3_Key15";
VAL_ 431 MobDevBtnLockStsAndKeyIdPsdNotPsd 0 "PsdNotPsd_NotPsd" 1 "PsdNotPsd_Psd";
VAL_ 431 MobDevBtnTrReq 0 "TrReq_Idle" 1 "TrReq_Open" 2 "TrReq_Close" 3 "TrReq_Stop" 4 "TrReq_Enable" 5 "TrReq_Reserved1" 6 "TrReq_Reserved2" 7 "TrReq_Reserved3";
VAL_ 431 MobDevBtnUnlckStsAndKeyIdKeyId3 0 "KeyId3_Key0" 1 "KeyId3_Key1" 2 "KeyId3_Key2" 3 "KeyId3_Key3" 4 "KeyId3_Key4" 5 "KeyId3_Key5" 6 "KeyId3_Key6" 7 "KeyId3_Key7" 8 "KeyId3_Key8" 9 "KeyId3_Key9" 10 "KeyId3_Key10" 11 "KeyId3_Key11" 12 "KeyId3_Key12" 13 "KeyId3_Key13" 14 "KeyId3_Key14" 15 "KeyId3_Key15";
VAL_ 431 MobDevBtnUnlckStsAndKeyIdPsdNotPsd 0 "PsdNotPsd_NotPsd" 1 "PsdNotPsd_Psd";
VAL_ 431 MobDevChrgngLidOpnReq 0 "PsdNotPsd1_NotPsd" 1 "PsdNotPsd1_Psd";
VAL_ 431 MobDevKeyDiReqKeySts0 0 "OnOff1_Off" 1 "OnOff1_On";
VAL_ 431 MobDevKeyDiReqKeySts1 0 "OnOff1_Off" 1 "OnOff1_On";
VAL_ 431 MobDevKeyDiReqKeySts10 0 "OnOff1_Off" 1 "OnOff1_On";
VAL_ 431 MobDevKeyDiReqKeySts11 0 "OnOff1_Off" 1 "OnOff1_On";
VAL_ 431 MobDevKeyDiReqKeySts12 0 "OnOff1_Off" 1 "OnOff1_On";
VAL_ 431 MobDevKeyDiReqKeySts13 0 "OnOff1_Off" 1 "OnOff1_On";
VAL_ 431 MobDevKeyDiReqKeySts14 0 "OnOff1_Off" 1 "OnOff1_On";
VAL_ 431 MobDevKeyDiReqKeySts15 0 "OnOff1_Off" 1 "OnOff1_On";
VAL_ 431 MobDevKeyDiReqKeySts2 0 "OnOff1_Off" 1 "OnOff1_On";
VAL_ 431 MobDevKeyDiReqKeySts3 0 "OnOff1_Off" 1 "OnOff1_On";
VAL_ 431 MobDevKeyDiReqKeySts4 0 "OnOff1_Off" 1 "OnOff1_On";
VAL_ 431 MobDevKeyDiReqKeySts5 0 "OnOff1_Off" 1 "OnOff1_On";
VAL_ 431 MobDevKeyDiReqKeySts6 0 "OnOff1_Off" 1 "OnOff1_On";
VAL_ 431 MobDevKeyDiReqKeySts7 0 "OnOff1_Off" 1 "OnOff1_On";
VAL_ 431 MobDevKeyDiReqKeySts8 0 "OnOff1_Off" 1 "OnOff1_On";
VAL_ 431 MobDevKeyDiReqKeySts9 0 "OnOff1_Off" 1 "OnOff1_On";
VAL_ 431 MobDevKeyEnaStsKey0 0 "KeySts1_KeyStsIdle" 1 "KeySts1_KeyStsDi" 2 "KeySts1_KeyStsEna" 3 "KeySts1_KeyStsLimd";
VAL_ 431 MobDevKeyEnaStsKey1 0 "KeySts1_KeyStsIdle" 1 "KeySts1_KeyStsDi" 2 "KeySts1_KeyStsEna" 3 "KeySts1_KeyStsLimd";
VAL_ 431 MobDevKeyEnaStsKey10 0 "KeySts1_KeyStsIdle" 1 "KeySts1_KeyStsDi" 2 "KeySts1_KeyStsEna" 3 "KeySts1_KeyStsLimd";
VAL_ 431 MobDevKeyEnaStsKey11 0 "KeySts1_KeyStsIdle" 1 "KeySts1_KeyStsDi" 2 "KeySts1_KeyStsEna" 3 "KeySts1_KeyStsLimd";
VAL_ 431 MobDevKeyEnaStsKey12 0 "KeySts1_KeyStsIdle" 1 "KeySts1_KeyStsDi" 2 "KeySts1_KeyStsEna" 3 "KeySts1_KeyStsLimd";
VAL_ 431 MobDevKeyEnaStsKey13 0 "KeySts1_KeyStsIdle" 1 "KeySts1_KeyStsDi" 2 "KeySts1_KeyStsEna" 3 "KeySts1_KeyStsLimd";
VAL_ 431 MobDevKeyEnaStsKey14 0 "KeySts1_KeyStsIdle" 1 "KeySts1_KeyStsDi" 2 "KeySts1_KeyStsEna" 3 "KeySts1_KeyStsLimd";
VAL_ 431 MobDevKeyEnaStsKey15 0 "KeySts1_KeyStsIdle" 1 "KeySts1_KeyStsDi" 2 "KeySts1_KeyStsEna" 3 "KeySts1_KeyStsLimd";
VAL_ 431 MobDevKeyEnaStsKey2 0 "KeySts1_KeyStsIdle" 1 "KeySts1_KeyStsDi" 2 "KeySts1_KeyStsEna" 3 "KeySts1_KeyStsLimd";
VAL_ 431 MobDevKeyEnaStsKey3 0 "KeySts1_KeyStsIdle" 1 "KeySts1_KeyStsDi" 2 "KeySts1_KeyStsEna" 3 "KeySts1_KeyStsLimd";
VAL_ 431 MobDevKeyEnaStsKey4 0 "KeySts1_KeyStsIdle" 1 "KeySts1_KeyStsDi" 2 "KeySts1_KeyStsEna" 3 "KeySts1_KeyStsLimd";
VAL_ 431 MobDevKeyEnaStsKey5 0 "KeySts1_KeyStsIdle" 1 "KeySts1_KeyStsDi" 2 "KeySts1_KeyStsEna" 3 "KeySts1_KeyStsLimd";
VAL_ 431 MobDevKeyEnaStsKey6 0 "KeySts1_KeyStsIdle" 1 "KeySts1_KeyStsDi" 2 "KeySts1_KeyStsEna" 3 "KeySts1_KeyStsLimd";
VAL_ 431 MobDevKeyEnaStsKey7 0 "KeySts1_KeyStsIdle" 1 "KeySts1_KeyStsDi" 2 "KeySts1_KeyStsEna" 3 "KeySts1_KeyStsLimd";
VAL_ 431 MobDevKeyEnaStsKey8 0 "KeySts1_KeyStsIdle" 1 "KeySts1_KeyStsDi" 2 "KeySts1_KeyStsEna" 3 "KeySts1_KeyStsLimd";
VAL_ 431 MobDevKeyEnaStsKey9 0 "KeySts1_KeyStsIdle" 1 "KeySts1_KeyStsDi" 2 "KeySts1_KeyStsEna" 3 "KeySts1_KeyStsLimd";
VAL_ 431 MobDevOpenClsCmftReq 0 "OpenClsCmftReq1_NoCmftReq" 1 "OpenClsCmftReq1_OpenCmft" 2 "OpenClsCmftReq1_ClsCmft" 3 "OpenClsCmftReq1_StopCmft";
VAL_ 431 MobDevRoofOpnClsReq 0 "OpenClsCmftReq1_NoCmftReq" 1 "OpenClsCmftReq1_OpenCmft" 2 "OpenClsCmftReq1_ClsCmft" 3 "OpenClsCmftReq1_StopCmft";
VAL_ 431 MobDevVldUserStsToVMM 0 "Validity_NotValid" 1 "Validity_Valid";
VAL_ 431 MobDevWinOpnClsReq 0 "OpenClsCmftReq1_NoCmftReq" 1 "OpenClsCmftReq1_OpenCmft" 2 "OpenClsCmftReq1_ClsCmft" 3 "OpenClsCmftReq1_StopCmft";
VAL_ 431 NFCKeyReadStsToKeyRmnWrnKey0 0 "KeyPrsntSts1_KeyPrsntStsIdle" 1 "KeyPrsntSts1_KeyPrsntStsInProgs" 2 "KeyPrsntSts1_KeyPrsntStsNotPrsnt" 3 "KeyPrsntSts1_KeyPrsntStsPrsnt";
VAL_ 431 NFCKeyReadStsToKeyRmnWrnKey1 0 "KeyPrsntSts1_KeyPrsntStsIdle" 1 "KeyPrsntSts1_KeyPrsntStsInProgs" 2 "KeyPrsntSts1_KeyPrsntStsNotPrsnt" 3 "KeyPrsntSts1_KeyPrsntStsPrsnt";
VAL_ 431 NFCKeyReadStsToKeyRmnWrnKey10 0 "KeyPrsntSts1_KeyPrsntStsIdle" 1 "KeyPrsntSts1_KeyPrsntStsInProgs" 2 "KeyPrsntSts1_KeyPrsntStsNotPrsnt" 3 "KeyPrsntSts1_KeyPrsntStsPrsnt";
VAL_ 431 NFCKeyReadStsToKeyRmnWrnKey11 0 "KeyPrsntSts1_KeyPrsntStsIdle" 1 "KeyPrsntSts1_KeyPrsntStsInProgs" 2 "KeyPrsntSts1_KeyPrsntStsNotPrsnt" 3 "KeyPrsntSts1_KeyPrsntStsPrsnt";
VAL_ 431 NFCKeyReadStsToKeyRmnWrnKey12 0 "KeyPrsntSts1_KeyPrsntStsIdle" 1 "KeyPrsntSts1_KeyPrsntStsInProgs" 2 "KeyPrsntSts1_KeyPrsntStsNotPrsnt" 3 "KeyPrsntSts1_KeyPrsntStsPrsnt";
VAL_ 431 NFCKeyReadStsToKeyRmnWrnKey13 0 "KeyPrsntSts1_KeyPrsntStsIdle" 1 "KeyPrsntSts1_KeyPrsntStsInProgs" 2 "KeyPrsntSts1_KeyPrsntStsNotPrsnt" 3 "KeyPrsntSts1_KeyPrsntStsPrsnt";
VAL_ 431 NFCKeyReadStsToKeyRmnWrnKey14 0 "KeyPrsntSts1_KeyPrsntStsIdle" 1 "KeyPrsntSts1_KeyPrsntStsInProgs" 2 "KeyPrsntSts1_KeyPrsntStsNotPrsnt" 3 "KeyPrsntSts1_KeyPrsntStsPrsnt";
VAL_ 431 NFCKeyReadStsToKeyRmnWrnKey15 0 "KeyPrsntSts1_KeyPrsntStsIdle" 1 "KeyPrsntSts1_KeyPrsntStsInProgs" 2 "KeyPrsntSts1_KeyPrsntStsNotPrsnt" 3 "KeyPrsntSts1_KeyPrsntStsPrsnt";
VAL_ 431 NFCKeyReadStsToKeyRmnWrnKey2 0 "KeyPrsntSts1_KeyPrsntStsIdle" 1 "KeyPrsntSts1_KeyPrsntStsInProgs" 2 "KeyPrsntSts1_KeyPrsntStsNotPrsnt" 3 "KeyPrsntSts1_KeyPrsntStsPrsnt";
VAL_ 431 NFCKeyReadStsToKeyRmnWrnKey3 0 "KeyPrsntSts1_KeyPrsntStsIdle" 1 "KeyPrsntSts1_KeyPrsntStsInProgs" 2 "KeyPrsntSts1_KeyPrsntStsNotPrsnt" 3 "KeyPrsntSts1_KeyPrsntStsPrsnt";
VAL_ 431 NFCKeyReadStsToKeyRmnWrnKey4 0 "KeyPrsntSts1_KeyPrsntStsIdle" 1 "KeyPrsntSts1_KeyPrsntStsInProgs" 2 "KeyPrsntSts1_KeyPrsntStsNotPrsnt" 3 "KeyPrsntSts1_KeyPrsntStsPrsnt";
VAL_ 431 NFCKeyReadStsToKeyRmnWrnKey5 0 "KeyPrsntSts1_KeyPrsntStsIdle" 1 "KeyPrsntSts1_KeyPrsntStsInProgs" 2 "KeyPrsntSts1_KeyPrsntStsNotPrsnt" 3 "KeyPrsntSts1_KeyPrsntStsPrsnt";
VAL_ 431 NFCKeyReadStsToKeyRmnWrnKey6 0 "KeyPrsntSts1_KeyPrsntStsIdle" 1 "KeyPrsntSts1_KeyPrsntStsInProgs" 2 "KeyPrsntSts1_KeyPrsntStsNotPrsnt" 3 "KeyPrsntSts1_KeyPrsntStsPrsnt";
VAL_ 431 NFCKeyReadStsToKeyRmnWrnKey7 0 "KeyPrsntSts1_KeyPrsntStsIdle" 1 "KeyPrsntSts1_KeyPrsntStsInProgs" 2 "KeyPrsntSts1_KeyPrsntStsNotPrsnt" 3 "KeyPrsntSts1_KeyPrsntStsPrsnt";
VAL_ 431 NFCKeyReadStsToKeyRmnWrnKey8 0 "KeyPrsntSts1_KeyPrsntStsIdle" 1 "KeyPrsntSts1_KeyPrsntStsInProgs" 2 "KeyPrsntSts1_KeyPrsntStsNotPrsnt" 3 "KeyPrsntSts1_KeyPrsntStsPrsnt";
VAL_ 431 NFCKeyReadStsToKeyRmnWrnKey9 0 "KeyPrsntSts1_KeyPrsntStsIdle" 1 "KeyPrsntSts1_KeyPrsntStsInProgs" 2 "KeyPrsntSts1_KeyPrsntStsNotPrsnt" 3 "KeyPrsntSts1_KeyPrsntStsPrsnt";
VAL_ 431 OutdBriHwOutdBriSts 0 "OutdBriSts_Ukwn" 1 "OutdBriSts_Night" 2 "OutdBriSts_Day" 3 "OutdBriSts_Invld";
VAL_ 431 OutdBriSts 0 "OutdBriSts_Ukwn" 1 "OutdBriSts_Night" 2 "OutdBriSts_Day" 3 "OutdBriSts_Invld";
VAL_ 431 SteerLockChkSts 0 "AvlSts2_NotAvl" 1 "AvlSts2_Avl";
VAL_ 431 SteerLockReqCommand 0 "SteerLockReqCmd_SteerIdleCmd" 1 "SteerLockReqCmd_SteerUnlckCmd" 2 "SteerLockReqCmd_SteerLockCmd" 3 "SteerLockReqCmd_SteerResdCmd";
VAL_ 431 WinWshrLvrCmd 0 "WinWshrLvrCmd1_WinWshrOff" 1 "WinWshrLvrCmd1_FrntWshrCmd" 2 "WinWshrLvrCmd1_ReWshrCmd";
VAL_ 1189 SnsrInclnCmd 0 "SnsrArmReq_Disarm" 1 "SnsrArmReq_Arm";
VAL_ 1189 SnsrIntrScanCmdAirFanSts 0 "OnOff1_Off" 1 "OnOff1_On";
VAL_ 1189 SnsrIntrScanCmdArmReq 0 "SnsrArmReq_Disarm" 1 "SnsrArmReq_Arm";
VAL_ 1189 SnsrIntrScanCmdCurtRollUpDwn 0 "CurtRollUpDwn_Up" 1 "CurtRollUpDwn_Dwn";
VAL_ 1189 SnsrIntrScanCmdRoofPosn 0 "RoofPosn_Clsd" 1 "RoofPosn_Open";
VAL_ 1189 SnsrIntrScanCmdWinPosn 0 "OpendClsd2_Clsd" 1 "OpendClsd2_NotClsd";
VAL_ 1189 SnsrSoundrBattBackedCmdArmCmd 0 "SnsrArmReq_Disarm" 1 "SnsrArmReq_Arm";
VAL_ 1189 SnsrSoundrBattBackedCmdChrgReq 0 "ChrgReq1_StopChrg" 1 "ChrgReq1_StrtChrg";
VAL_ 1189 SnsrSoundrBattBackedCmdSoundReq 0 "OnOff1_Off" 1 "OnOff1_On";
VAL_ 1189 SunRoofAndCurtPosnCmdOpenPerc 0 "WinAndRoofAndCurtPosnTyp_PosnUkwn" 1 "WinAndRoofAndCurtPosnTyp_ClsFull" 2 "WinAndRoofAndCurtPosnTyp_PercOpen4" 3 "WinAndRoofAndCurtPosnTyp_PercOpen8" 4 "WinAndRoofAndCurtPosnTyp_PercOpen12" 5 "WinAndRoofAndCurtPosnTyp_PercOpen16" 6 "WinAndRoofAndCurtPosnTyp_PercOpen20" 7 "WinAndRoofAndCurtPosnTyp_PercOpen24" 8 "WinAndRoofAndCurtPosnTyp_PercOpen28" 9 "WinAndRoofAndCurtPosnTyp_PercOpen32" 10 "WinAndRoofAndCurtPosnTyp_PercOpen36" 11 "WinAndRoofAndCurtPosnTyp_PercOpen40" 12 "WinAndRoofAndCurtPosnTyp_PercOpen44" 13 "WinAndRoofAndCurtPosnTyp_PercOpen48" 14 "WinAndRoofAndCurtPosnTyp_PercOpen52" 15 "WinAndRoofAndCurtPosnTyp_PercOpen56" 16 "WinAndRoofAndCurtPosnTyp_PercOpen60" 17 "WinAndRoofAndCurtPosnTyp_PercOpen64" 18 "WinAndRoofAndCurtPosnTyp_PercOpen68" 19 "WinAndRoofAndCurtPosnTyp_PercOpen72" 20 "WinAndRoofAndCurtPosnTyp_PercOpen76" 21 "WinAndRoofAndCurtPosnTyp_PercOpen80" 22 "WinAndRoofAndCurtPosnTyp_PercOpen84" 23 "WinAndRoofAndCurtPosnTyp_PercOpen88" 24 "WinAndRoofAndCurtPosnTyp_PercOpen92" 25 "WinAndRoofAndCurtPosnTyp_PercOpen96" 26 "WinAndRoofAndCurtPosnTyp_OpenFull" 27 "WinAndRoofAndCurtPosnTyp_Resd1" 28 "WinAndRoofAndCurtPosnTyp_Resd2" 29 "WinAndRoofAndCurtPosnTyp_Resd3" 30 "WinAndRoofAndCurtPosnTyp_Resd4" 31 "WinAndRoofAndCurtPosnTyp_Movg";
VAL_ 1189 SunRoofAndCurtPosnCmdSel 0 "SunRoofOrCurt_None" 1 "SunRoofOrCurt_Curt" 2 "SunRoofOrCurt_SunRoof" 3 "SunRoofOrCurt_Both";
VAL_ 1189 SunRoofEna 0 "SunRoofAndCurtEnaTyp_Di" 1 "SunRoofAndCurtEnaTyp_LimdEna" 2 "SunRoofAndCurtEnaTyp_FullEna" 3 "SunRoofAndCurtEnaTyp_Resd";
VAL_ 1189 TCSDcdcactvdReq 0 "OnOffNoReq_NoReq" 1 "OnOffNoReq_On" 2 "OnOffNoReq_Off";
VAL_ 1189 TCSUsgModReq 0 "OnOff1_Off" 1 "OnOff1_On";
VAL_ 1189 TrlrLiBrkActvt 0 "OnOff1_Off" 1 "OnOff1_On";
VAL_ 1189 TrlrLiFogActvt 0 "OnOff1_Off" 1 "OnOff1_On";
VAL_ 1189 TrlrLiPosnActvt 0 "OnOffCrit1_NotVld1" 1 "OnOffCrit1_Off" 2 "OnOffCrit1_On" 3 "OnOffCrit1_NotVld2";
VAL_ 1189 TrlrLiRvsgActvt 0 "OnOff1_Off" 1 "OnOff1_On";
VAL_ 1189 WinDsblLeftSts 0 "OnOff1_Off" 1 "OnOff1_On";
VAL_ 1189 WinHwSwtDrvrReDoor 0 "WinPosnReq_Idle" 1 "WinPosnReq_UpMan" 2 "WinPosnReq_UpAut" 3 "WinPosnReq_DwnMan" 4 "WinPosnReq_DwnAut" 5 "WinPosnReq_NotDefd";
VAL_ 1189 WipgPwrActvnNotSafeAcsyMode 0 "OnOff1_Off" 1 "OnOff1_On";
VAL_ 1189 WipgPwrActvnNotSafeDrvgMod 0 "OnOff1_Off" 1 "OnOff1_On";
VAL_ 1189 WipgPwrActvnSafeWipgPwrAcsyModSafe 0 "OnOffCrit1_NotVld1" 1 "OnOffCrit1_Off" 2 "OnOffCrit1_On" 3 "OnOffCrit1_NotVld2";
VAL_ 1189 WipgPwrActvnSafeWipgPwrDrvgModSafe 0 "OnOffCrit1_NotVld1" 1 "OnOffCrit1_Off" 2 "OnOffCrit1_On" 3 "OnOffCrit1_NotVld2";
VAL_ 1189 WiprActvMech 0 "OnOff1_Off" 1 "OnOff1_On";
VAL_ 1189 WiprInPrkgPosnLo 0 "OnOff1_Off" 1 "OnOff1_On";
VAL_ 1189 WiprInWipgArMech 0 "OnOff1_Off" 1 "OnOff1_On";
VAL_ 1189 WiprLvrComErrDetd 0 "OnOff1_Off" 1 "OnOff1_On";
VAL_ 1189 WiprLvrNodErrDetd 0 "OnOff1_Off" 1 "OnOff1_On";
VAL_ 1189 WiprMotComErrDetd 0 "OnOff1_Off" 1 "OnOff1_On";
VAL_ 1189 WiprMotErr 0 "OnOff1_Off" 1 "OnOff1_On";
VAL_ 1189 WiprMotErrSafeMech 0 "OnOffCrit1_NotVld1" 1 "OnOffCrit1_Off" 2 "OnOffCrit1_On" 3 "OnOffCrit1_NotVld2";
VAL_ 1189 WiprMotFrntLvrCmdNotSafeLvrInHiSpdPosn 0 "OnOff1_Off" 1 "OnOff1_On";
VAL_ 1189 WiprMotFrntLvrCmdNotSafeLvrInIntlPosn 0 "OnOff1_Off" 1 "OnOff1_On";
VAL_ 1189 WiprMotFrntLvrCmdNotSafeLvrInLoSpdPosn 0 "OnOff1_Off" 1 "OnOff1_On";
VAL_ 1189 WiprMotFrntLvrCmdNotSafeLvrInSnglStrokePos 0 "OnOff1_Off" 1 "OnOff1_On";
VAL_ 1189 WiprMotIntlCmd 0 "WipgSpdIntlFromHmi_Posn0" 1 "WipgSpdIntlFromHmi_Posn1" 2 "WipgSpdIntlFromHmi_Posn2" 3 "WipgSpdIntlFromHmi_Posn3" 4 "WipgSpdIntlFromHmi_Posn4" 5 "WipgSpdIntlFromHmi_Posn5" 6 "WipgSpdIntlFromHmi_Posn6" 7 "WipgSpdIntlFromHmi_Posn7";
VAL_ 1189 WiprMotNodErrDetd 0 "OnOff1_Off" 1 "OnOff1_On";
VAL_ 1189 WiprMotRelayMech 0 "Boolean_FALSE" 1 "Boolean_TRUE";
VAL_ 1189 WiprPosnForSrvReq 0 "OnOff1_Off" 1 "OnOff1_On";
VAL_ 1189 WiprReInWipgAr 0 "OnOff1_Off" 1 "OnOff1_On";
VAL_ 1189 WiprWshrMgrErrDetd 0 "OnOff1_Off" 1 "OnOff1_On";
VAL_ 1189 WshngCycActv 0 "OnOff1_Off" 1 "OnOff1_On";
VAL_ 1189 WshngCycActvMech 0 "OnOff1_Off" 1 "OnOff1_On";
VAL_ 1189 WshrFldLvlDetdLo 0 "OnOff1_Off" 1 "OnOff1_On";
VAL_ 1189 WshrLvrPosnNotSafe 0 "OnOff1_Off" 1 "OnOff1_On";
VAL_ 1189 WshrLvrPosnSafe 0 "OnOffCrit1_NotVld1" 1 "OnOffCrit1_Off" 2 "OnOffCrit1_On" 3 "OnOffCrit1_NotVld2";
VAL_ 1348 VFCVectorZCUDMVFCid0 0 "VFCOnOff_Off" 1 "VFCOnOff_On";
VAL_ 1348 VFCVectorZCUDMVFCid1 0 "VFCOnOff_Off" 1 "VFCOnOff_On";
VAL_ 1348 VFCVectorZCUDMVFCid10 0 "VFCOnOff_Off" 1 "VFCOnOff_On";
VAL_ 1348 VFCVectorZCUDMVFCid11 0 "VFCOnOff_Off" 1 "VFCOnOff_On";
VAL_ 1348 VFCVectorZCUDMVFCid12 0 "VFCOnOff_Off" 1 "VFCOnOff_On";
VAL_ 1348 VFCVectorZCUDMVFCid13 0 "VFCOnOff_Off" 1 "VFCOnOff_On";
VAL_ 1348 VFCVectorZCUDMVFCid14 0 "VFCOnOff_Off" 1 "VFCOnOff_On";
VAL_ 1348 VFCVectorZCUDMVFCid15 0 "VFCOnOff_Off" 1 "VFCOnOff_On";
VAL_ 1348 VFCVectorZCUDMVFCid16 0 "VFCOnOff_Off" 1 "VFCOnOff_On";
VAL_ 1348 VFCVectorZCUDMVFCid17 0 "VFCOnOff_Off" 1 "VFCOnOff_On";
VAL_ 1348 VFCVectorZCUDMVFCid18 0 "VFCOnOff_Off" 1 "VFCOnOff_On";
VAL_ 1348 VFCVectorZCUDMVFCid19 0 "VFCOnOff_Off" 1 "VFCOnOff_On";
VAL_ 1348 VFCVectorZCUDMVFCid2 0 "VFCOnOff_Off" 1 "VFCOnOff_On";
VAL_ 1348 VFCVectorZCUDMVFCid20 0 "VFCOnOff_Off" 1 "VFCOnOff_On";
VAL_ 1348 VFCVectorZCUDMVFCid21 0 "VFCOnOff_Off" 1 "VFCOnOff_On";
VAL_ 1348 VFCVectorZCUDMVFCid22 0 "VFCOnOff_Off" 1 "VFCOnOff_On";
VAL_ 1348 VFCVectorZCUDMVFCid23 0 "VFCOnOff_Off" 1 "VFCOnOff_On";
VAL_ 1348 VFCVectorZCUDMVFCid24 0 "VFCOnOff_Off" 1 "VFCOnOff_On";
VAL_ 1348 VFCVectorZCUDMVFCid25 0 "VFCOnOff_Off" 1 "VFCOnOff_On";
VAL_ 1348 VFCVectorZCUDMVFCid26 0 "VFCOnOff_Off" 1 "VFCOnOff_On";
VAL_ 1348 VFCVectorZCUDMVFCid27 0 "VFCOnOff_Off" 1 "VFCOnOff_On";
VAL_ 1348 VFCVectorZCUDMVFCid28 0 "VFCOnOff_Off" 1 "VFCOnOff_On";
VAL_ 1348 VFCVectorZCUDMVFCid29 0 "VFCOnOff_Off" 1 "VFCOnOff_On";
VAL_ 1348 VFCVectorZCUDMVFCid3 0 "VFCOnOff_Off" 1 "VFCOnOff_On";
VAL_ 1348 VFCVectorZCUDMVFCid30 0 "VFCOnOff_Off" 1 "VFCOnOff_On";
VAL_ 1348 VFCVectorZCUDMVFCid31 0 "VFCOnOff_Off" 1 "VFCOnOff_On";
VAL_ 1348 VFCVectorZCUDMVFCid32 0 "VFCOnOff_Off" 1 "VFCOnOff_On";
VAL_ 1348 VFCVectorZCUDMVFCid33 0 "VFCOnOff_Off" 1 "VFCOnOff_On";
VAL_ 1348 VFCVectorZCUDMVFCid34 0 "VFCOnOff_Off" 1 "VFCOnOff_On";
VAL_ 1348 VFCVectorZCUDMVFCid35 0 "VFCOnOff_Off" 1 "VFCOnOff_On";
VAL_ 1348 VFCVectorZCUDMVFCid36 0 "VFCOnOff_Off" 1 "VFCOnOff_On";
VAL_ 1348 VFCVectorZCUDMVFCid37 0 "VFCOnOff_Off" 1 "VFCOnOff_On";
VAL_ 1348 VFCVectorZCUDMVFCid38 0 "VFCOnOff_Off" 1 "VFCOnOff_On";
VAL_ 1348 VFCVectorZCUDMVFCid39 0 "VFCOnOff_Off" 1 "VFCOnOff_On";
VAL_ 1348 VFCVectorZCUDMVFCid4 0 "VFCOnOff_Off" 1 "VFCOnOff_On";
VAL_ 1348 VFCVectorZCUDMVFCid40 0 "VFCOnOff_Off" 1 "VFCOnOff_On";
VAL_ 1348 VFCVectorZCUDMVFCid41 0 "VFCOnOff_Off" 1 "VFCOnOff_On";
VAL_ 1348 VFCVectorZCUDMVFCid42 0 "VFCOnOff_Off" 1 "VFCOnOff_On";
VAL_ 1348 VFCVectorZCUDMVFCid43 0 "VFCOnOff_Off" 1 "VFCOnOff_On";
VAL_ 1348 VFCVectorZCUDMVFCid44 0 "VFCOnOff_Off" 1 "VFCOnOff_On";
VAL_ 1348 VFCVectorZCUDMVFCid45 0 "VFCOnOff_Off" 1 "VFCOnOff_On";
VAL_ 1348 VFCVectorZCUDMVFCid46 0 "VFCOnOff_Off" 1 "VFCOnOff_On";
VAL_ 1348 VFCVectorZCUDMVFCid47 0 "VFCOnOff_Off" 1 "VFCOnOff_On";
VAL_ 1348 VFCVectorZCUDMVFCid48 0 "VFCOnOff_Off" 1 "VFCOnOff_On";
VAL_ 1348 VFCVectorZCUDMVFCid49 0 "VFCOnOff_Off" 1 "VFCOnOff_On";
VAL_ 1348 VFCVectorZCUDMVFCid5 0 "VFCOnOff_Off" 1 "VFCOnOff_On";
VAL_ 1348 VFCVectorZCUDMVFCid50 0 "VFCOnOff_Off" 1 "VFCOnOff_On";
VAL_ 1348 VFCVectorZCUDMVFCid51 0 "VFCOnOff_Off" 1 "VFCOnOff_On";
VAL_ 1348 VFCVectorZCUDMVFCid52 0 "VFCOnOff_Off" 1 "VFCOnOff_On";
VAL_ 1348 VFCVectorZCUDMVFCid53 0 "VFCOnOff_Off" 1 "VFCOnOff_On";
VAL_ 1348 VFCVectorZCUDMVFCid54 0 "VFCOnOff_Off" 1 "VFCOnOff_On";
VAL_ 1348 VFCVectorZCUDMVFCid55 0 "VFCOnOff_Off" 1 "VFCOnOff_On";
VAL_ 1348 VFCVectorZCUDMVFCid56 0 "VFCOnOff_Off" 1 "VFCOnOff_On";
VAL_ 1348 VFCVectorZCUDMVFCid57 0 "VFCOnOff_Off" 1 "VFCOnOff_On";
VAL_ 1348 VFCVectorZCUDMVFCid58 0 "VFCOnOff_Off" 1 "VFCOnOff_On";
VAL_ 1348 VFCVectorZCUDMVFCid59 0 "VFCOnOff_Off" 1 "VFCOnOff_On";
VAL_ 1348 VFCVectorZCUDMVFCid6 0 "VFCOnOff_Off" 1 "VFCOnOff_On";
VAL_ 1348 VFCVectorZCUDMVFCid60 0 "VFCOnOff_Off" 1 "VFCOnOff_On";
VAL_ 1348 VFCVectorZCUDMVFCid61 0 "VFCOnOff_Off" 1 "VFCOnOff_On";
VAL_ 1348 VFCVectorZCUDMVFCid7 0 "VFCOnOff_Off" 1 "VFCOnOff_On";
VAL_ 1348 VFCVectorZCUDMVFCid8 0 "VFCOnOff_Off" 1 "VFCOnOff_On";
VAL_ 1348 VFCVectorZCUDMVFCid9 0 "VFCOnOff_Off" 1 "VFCOnOff_On";
VAL_ 1284 WakeUpReasonsforZCUDM 0 "WakeupReasons_667949" 1 "WakeupReasons_667950" 2 "WakeupReasons_169654" 3 "WakeupReasons_667951" 4 "WakeupReasons_168965" 5 "WakeupReasons_197643" 6 "WakeupReasons_264933" 7 "WakeupReasons_45654" 8 "WakeupReasons_22058" 9 "WakeupReasons_49446" 10 "WakeupReasons_22060" 11 "WakeupReasons_269740" 12 "WakeupReasons_269735" 13 "WakeupReasons_269739" 14 "WakeupReasons_658500" 15 "WakeupReasons_21901" 16 "WakeupReasons_45793" 17 "WakeupReasons_45794" 18 "WakeupReasons_22005" 19 "WakeupReasons_22013" 20 "WakeupReasons_22100" 21 "WakeupReasons_45659" 22 "WakeupReasons_45657" 23 "WakeupReasons_140084" 24 "WakeupReasons_21973" 25 "WakeupReasons_91253" 26 "WakeupReasons_88123" 27 "WakeupReasons_88125" 28 "WakeupReasons_321583" 29 "WakeupReasons_74188" 30 "WakeupReasons_667945" 31 "WakeupReasons_169655" 32 "WakeupReasons_667948" 33 "WakeupReasons_168966" 34 "WakeupReasons_170865" 35 "WakeupReasons_197642" 36 "WakeupReasons_264876" 37 "WakeupReasons_191050" 38 "WakeupReasons_182033" 39 "WakeupReasons_200937" 40 "WakeupReasons_170807" 41 "WakeupReasons_319139" 42 "WakeupReasons_100298" 43 "WakeupReasons_100275" 44 "WakeupReasons_100300" 45 "WakeupReasons_100278" 46 "WakeupReasons_100281" 47 "WakeupReasons_265333" 48 "WakeupReasons_108776" 49 "WakeupReasons_176921" 50 "WakeupReasons_197826" 51 "WakeupReasons_185670" 52 "WakeupReasons_161066" 53 "WakeupReasons_200156" 54 "WakeupReasons_225696" 55 "WakeupReasons_21997" 56 "WakeupReasons_45656" 57 "WakeupReasons_266860" 58 "WakeupReasons_169894" 59 "WakeupReasons_320282" 60 "WakeupReasons_319422" 61 "WakeupReasons_320277" 62 "WakeupReasons_355601" 63 "WakeupReasons_360904" 64 "WakeupReasons_361505" 65 "WakeupReasons_361509" 66 "WakeupReasons_645094" 67 "WakeupReasons_68676" 68 "WakeupReasons_360008" 69 "WakeupReasons_109382" 70 "WakeupReasons_119273" 71 "WakeupReasons_224065" 72 "WakeupReasons_68644" 73 "WakeupReasons_109364" 74 "WakeupReasons_68481" 75 "WakeupReasons_224061" 76 "WakeupReasons_360006" 77 "WakeupReasons_138997" 78 "WakeupReasons_634696" 79 "WakeupReasons_645810" 80 "WakeupReasons_297868" 81 "WakeupReasons_315364" 82 "WakeupReasons_109367" 83 "WakeupReasons_320126" 84 "WakeupReasons_109387" 85 "WakeupReasons_634710" 86 "WakeupReasons_338820" 87 "WakeupReasons_67182" 88 "WakeupReasons_152237" 89 "WakeupReasons_145707" 90 "WakeupReasons_199172" 91 "WakeupReasons_144897" 92 "WakeupReasons_186489" 93 "WakeupReasons_144970" 94 "WakeupReasons_152786" 95 "WakeupReasons_264932" 96 "WakeupReasons_264934" 97 "WakeupReasons_356190" 98 "WakeupReasons_145688" 99 "WakeupReasons_95444" 100 "WakeupReasons_169945" 101 "WakeupReasons_140678" 102 "WakeupReasons_222553" 103 "WakeupReasons_224831" 104 "WakeupReasons_201815" 105 "WakeupReasons_45864" 106 "WakeupReasons_659549" 107 "WakeupReasons_45866" 108 "WakeupReasons_45867" 109 "WakeupReasons_169884" 110 "WakeupReasons_264962" 111 "WakeupReasons_201348" 112 "WakeupReasons_320287" 113 "WakeupReasons_156412" 114 "WakeupReasons_133749" 115 "WakeupReasons_355409" 116 "WakeupReasons_636692" 117 "WakeupReasons_533044" 118 "WakeupReasons_106774" 119 "WakeupReasons_145311" 120 "WakeupReasons_145319" 121 "WakeupReasons_152774" 122 "WakeupReasons_145330" 123 "WakeupReasons_145388" 124 "WakeupReasons_145399" 125 "WakeupReasons_145362" 126 "WakeupReasons_145385" 127 "WakeupReasons_145373" 128 "WakeupReasons_145288" 129 "WakeupReasons_145419" 130 "WakeupReasons_145454" 131 "WakeupReasons_145462" 132 "WakeupReasons_269156" 133 "WakeupReasons_300427" 134 "WakeupReasons_220322" 135 "WakeupReasons_224617" 136 "WakeupReasons_224634" 137 "WakeupReasons_300682" 138 "WakeupReasons_264958" 139 "WakeupReasons_160597" 140 "WakeupReasons_160602" 141 "WakeupReasons_108841" 142 "WakeupReasons_265569" 143 "WakeupReasons_526429" 144 "WakeupReasons_514545" 145 "WakeupReasons_265232" 146 "WakeupReasons_644550" 147 "WakeupReasons_317616" 148 "WakeupReasons_354791" 149 "WakeupReasons_320631" 150 "WakeupReasons_337565" 151 "WakeupReasons_532007" 152 "WakeupReasons_514503" 153 "WakeupReasons_299117" 154 "WakeupReasons_340667" 155 "WakeupReasons_321845" 156 "WakeupReasons_179103" 157 "WakeupReasons_108810" 158 "WakeupReasons_322857" 159 "WakeupReasons_658603" 160 "WakeupReasons_197648" 161 "WakeupReasons_160596" 162 "WakeupReasons_361272" 163 "WakeupReasons_361279" 164 "WakeupReasons_265305" 165 "WakeupReasons_265328" 166 "WakeupReasons_265330" 167 "WakeupReasons_298808" 168 "WakeupReasons_515804" 169 "WakeupReasons_514502" 170 "WakeupReasons_645753" 171 "WakeupReasons_646109" 172 "WakeupReasons_299547" 173 "WakeupReasons_318342" 174 "WakeupReasons_360543" 175 "WakeupReasons_356549" 176 "WakeupReasons_198484" 177 "WakeupReasons_300681" 178 "WakeupReasons_359211" 179 "WakeupReasons_534077" 180 "WakeupReasons_525705" 181 "WakeupReasons_360299" 182 "WakeupReasons_526445" 183 "WakeupReasons_534145" 184 "WakeupReasons_192030" 185 "WakeupReasons_652361" 186 "WakeupReasons_355214" 187 "WakeupReasons_321317" 188 "WakeupReasons_359187" 189 "WakeupReasons_321057" 190 "WakeupReasons_321319" 191 "WakeupReasons_321323" 192 "WakeupReasons_321077" 193 "WakeupReasons_320895" 194 "WakeupReasons_655340" 195 "WakeupReasons_636556" 196 "WakeupReasons_108834" 197 "WakeupReasons_265937" 198 "WakeupReasons_533050" 199 "WakeupReasons_526426" 200 "WakeupReasons_264712" 201 "WakeupReasons_319401" 202 "WakeupReasons_643973" 203 "WakeupReasons_223715" 204 "WakeupReasons_199159" 205 "WakeupReasons_318382" 206 "WakeupReasons_226967" 207 "WakeupReasons_531743" 208 "WakeupReasons_360542" 209 "WakeupReasons_264726" 210 "WakeupReasons_535214" 211 "WakeupReasons_335068" 212 "WakeupReasons_316796" 213 "WakeupReasons_526438" 214 "WakeupReasons_198433" 215 "WakeupReasons_225961" 216 "WakeupReasons_197665" 217 "WakeupReasons_224550" 218 "WakeupReasons_667962" 219 "WakeupReasons_667953" 220 "WakeupReasons_110885" 221 "WakeupReasons_224552" 222 "WakeupReasons_224553" 223 "WakeupReasons_652546" 224 "WakeupReasons_331194" 225 "WakeupReasons_667820" 226 "WakeupReasons_659350" 227 "WakeupReasons_101706" 228 "WakeupReasons_101725" 229 "WakeupReasons_101728" 230 "WakeupReasons_101727" 231 "WakeupReasons_166267" 232 "WakeupReasons_156440" 233 "WakeupReasons_95949" 234 "WakeupReasons_112799" 235 "WakeupReasons_146470" 236 "WakeupReasons_176748" 237 "WakeupReasons_223920" 238 "WakeupReasons_668531" 239 "WakeupReasons_670087" 240 "WakeupReasons_668529" 241 "WakeupReasons_45858" 242 "WakeupReasons_315981" 243 "WakeupReasons_533370" 244 "WakeupReasons_533371" 245 "WakeupReasons_533372" 246 "WakeupReasons_241902" 247 "WakeupReasons_359559" 248 "WakeupReasons_516327" 249 "WakeupReasons_533872" 250 "WakeupReasons_45856" 251 "WakeupReasons_45853" 252 "WakeupReasons_45854" 253 "WakeupReasons_45852" 254 "WakeupReasons_45851" 255 "WakeupReasons_45850" 256 "WakeupReasons_45849" 257 "WakeupReasons_636801" 258 "WakeupReasons_109466" 259 "WakeupReasons_109467" 260 "WakeupReasons_670345" 261 "WakeupReasons_NMPDUReceived" 262 "WakeupReasons_358832" 263 "WakeupReasons_200683" 264 "WakeupReasons_198452" 265 "WakeupReasons_185457" 266 "WakeupReasons_185490" 267 "WakeupReasons_4471" 268 "WakeupReasons_269034" 269 "WakeupReasons_215560" 270 "WakeupReasons_312881" 271 "WakeupReasons_269140" 272 "WakeupReasons_197653" 273 "WakeupReasons_337991" 274 "WakeupReasons_658188" 275 "WakeupReasons_674953" 276 "WakeupReasons_675064" 277 "WakeupReasons_674958" 278 "WakeupReasons_675494" 279 "WakeupReasons_675837" 280 "WakeupReasons_667879" 281 "WakeupReasons_667947" 282 "WakeupReasons_676265" 283 "WakeupReasons_669465" 284 "WakeupReasons_670928" 285 "WakeupReasons_669447" 286 "WakeupReasons_667922" 287 "WakeupReasons_670753" 288 "WakeupReasons_668395" 289 "WakeupReasons_668393" 290 "WakeupReasons_667850" 291 "WakeupReasons_667848" 292 "WakeupReasons_311279" 293 "WakeupReasons_182918" 294 "WakeupReasons_667988" 295 "WakeupReasons_532555" 296 "WakeupReasons_532556" 297 "WakeupReasons_113348" 298 "WakeupReasons_193474" 299 "WakeupReasons_667871" 300 "WakeupReasons_670966" 301 "WakeupReasons_667985" 302 "WakeupReasons_670354" 303 "WakeupReasons_46017" 304 "WakeupReasons_675742" 305 "WakeupReasons_106669" 306 "WakeupReasons_80609" 307 "WakeupReasons_199714" 308 "WakeupReasons_200090" 309 "WakeupReasons_139075" 310 "WakeupReasons_268983" 311 "WakeupReasons_265131" 312 "WakeupReasons_263473" 313 "WakeupReasons_45887" 314 "WakeupReasons_69678" 315 "WakeupReasons_69679" 316 "WakeupReasons_45897" 317 "WakeupReasons_45898" 318 "WakeupReasons_80608" 319 "WakeupReasons_45869" 320 "WakeupReasons_45870" 321 "WakeupReasons_45872" 322 "WakeupReasons_45875" 323 "WakeupReasons_45871" 324 "WakeupReasons_45876" 325 "WakeupReasons_667980" 326 "WakeupReasons_45877" 327 "WakeupReasons_667973" 328 "WakeupReasons_670962" 329 "WakeupReasons_45888" 330 "WakeupReasons_45890" 331 "WakeupReasons_667869" 332 "WakeupReasons_45846" 333 "WakeupReasons_45847" 334 "WakeupReasons_45848" 335 "WakeupReasons_262872" 336 "WakeupReasons_127924" 337 "WakeupReasons_127926" 338 "WakeupReasons_674223" 339 "WakeupReasons_667982" 340 "WakeupReasons_657121" 341 "WakeupReasons_265745" 342 "WakeupReasons_657120" 343 "WakeupReasons_675564" 344 "WakeupReasons_197644" 345 "WakeupReasons_264943" 346 "WakeupReasons_264697" 347 "WakeupReasons_69216" 348 "WakeupReasons_128671" 349 "WakeupReasons_356598" 350 "WakeupReasons_675745" 351 "WakeupReasons_667983" 352 "WakeupReasons_667987" 353 "WakeupReasons_75103" 354 "WakeupReasons_305818" 355 "WakeupReasons_670942" 356 "WakeupReasons_532932" 357 "WakeupReasons_532933" 358 "WakeupReasons_83199" 359 "WakeupReasons_45900" 360 "WakeupReasons_88458" 361 "WakeupReasons_329457" 362 "WakeupReasons_45902" 363 "WakeupReasons_224211" 364 "WakeupReasons_667981" 365 "WakeupReasons_667874" 366 "WakeupReasons_46020" 367 "WakeupReasons_667842" 368 "WakeupReasons_145161" 369 "WakeupReasons_233755" 370 "WakeupReasons_297056" 371 "WakeupReasons_264691" 372 "WakeupReasons_262871" 373 "WakeupReasons_264964" 374 "WakeupReasons_667872" 375 "WakeupReasons_45655" 376 "WakeupReasons_177214" 377 "WakeupReasons_671005" 378 "WakeupReasons_680712" 379 "WakeupReasons_669822" 380 "WakeupReasons_668523" 381 "WakeupReasons_680974" 382 "WakeupReasons_680975" 383 "WakeupReasons_681028" 384 "WakeupReasons_670462" 385 "WakeupReasons_681134" 386 "WakeupReasons_681031" 387 "WakeupReasons_681711" 388 "WakeupReasons_682034" 389 "WakeupReasons_674839" 390 "WakeupReasons_681915" 391 "WakeupReasons_682032" 392 "WakeupReasons_682037" 393 "WakeupReasons_682688" 394 "WakeupReasons_681789" 395 "WakeupReasons_682023" 396 "WakeupReasons_681023" 397 "WakeupReasons_676285" 398 "WakeupReasons_682077" 399 "WakeupReasons_682076" 400 "WakeupReasons_682078" 401 "WakeupReasons_682153" 402 "WakeupReasons_682155" 403 "WakeupReasons_682152" 404 "WakeupReasons_682154" 405 "WakeupReasons_682074";
SIG_GROUP_ 427 ActnOfLedStopLamp 1 : ActnOfLedStopLampActnOfLedStopLamp ActnOfLedStopLampChks ActnOfLedStopLampCntr;
SIG_GROUP_ 427 ActnOfLoBeamDrv 1 : ActnOfLoBeamDrvChks ActnOfLoBeamDrvCntr ActnOfLoBeamDrvOnOff;
SIG_GROUP_ 427 BattLoSts 1 : BattLoStsKey0 BattLoStsKey1 BattLoStsKey10 BattLoStsKey11 BattLoStsKey2 BattLoStsKey3 BattLoStsKey4 BattLoStsKey5 BattLoStsKey6 BattLoStsKey7 BattLoStsKey8 BattLoStsKey9;
SIG_GROUP_ 427 BexvSts 1 : BexvStsExvActrPosn BexvStsExvBlkErr BexvStsExvCalibSts BexvStsExvElecStsErr BexvStsExvMovSts BexvStsExvOvrTempErr BexvStsExvOvrTrvlErr BexvStsExvPreHeatgSts BexvStsExvVoltgRangErr;
SIG_GROUP_ 427 BLEKeyBtnTrStsAndKeyId 1 : BLEKeyBtnTrStsAndKeyIdBLEBtnSts BLEKeyBtnTrStsAndKeyIdKeyId3;
SIG_GROUP_ 427 BLEKeyReadStsToKeyRmnWrn 1 : BLEKeyReadStsToKeyRmnWrnKey0 BLEKeyReadStsToKeyRmnWrnKey1 BLEKeyReadStsToKeyRmnWrnKey10 BLEKeyReadStsToKeyRmnWrnKey11 BLEKeyReadStsToKeyRmnWrnKey12 BLEKeyReadStsToKeyRmnWrnKey13 BLEKeyReadStsToKeyRmnWrnKey14 BLEKeyReadStsToKeyRmnWrnKey15 BLEKeyReadStsToKeyRmnWrnKey2 BLEKeyReadStsToKeyRmnWrnKey3 BLEKeyReadStsToKeyRmnWrnKey4 BLEKeyReadStsToKeyRmnWrnKey5 BLEKeyReadStsToKeyRmnWrnKey6 BLEKeyReadStsToKeyRmnWrnKey7 BLEKeyReadStsToKeyRmnWrnKey8 BLEKeyReadStsToKeyRmnWrnKey9;
SIG_GROUP_ 427 BLEKeyReadStsToVMM 1 : BLEKeyReadStsToVMMKey0 BLEKeyReadStsToVMMKey1 BLEKeyReadStsToVMMKey10 BLEKeyReadStsToVMMKey11 BLEKeyReadStsToVMMKey12 BLEKeyReadStsToVMMKey13 BLEKeyReadStsToVMMKey14 BLEKeyReadStsToVMMKey15 BLEKeyReadStsToVMMKey2 BLEKeyReadStsToVMMKey3 BLEKeyReadStsToVMMKey4 BLEKeyReadStsToVMMKey5 BLEKeyReadStsToVMMKey6 BLEKeyReadStsToVMMKey7 BLEKeyReadStsToVMMKey8 BLEKeyReadStsToVMMKey9;
SIG_GROUP_ 922 BtnStsOHC 1 : BtnStsOHCIntrLiSwtAllOnSts BtnStsOHCIntrLiSwtAutOnSts BtnStsOHCLiBtnReadingLe BtnStsOHCLiBtnReadingRi;
SIG_GROUP_ 922 BtnStsOHCR 1 : BtnStsOHCRLiBtnReadingLe BtnStsOHCRLiBtnReadingRi;
SIG_GROUP_ 922 BtnStsOHTR 1 : BtnStsOHTRLiBtnReadingLe BtnStsOHTRLiBtnReadingRi;
SIG_GROUP_ 1189 EtpZeroCrc 1 : EtpZeroCrc1 EtpZeroCrc2 EtpZeroCrcEtpZeroCrc;
SIG_GROUP_ 1189 EtpZeroDegrVal 1 : EtpZeroDegrVal1 EtpZeroDegrVal2 EtpZeroDegrValEtpZeroDegrVal;
SIG_GROUP_ 1189 EtpZeroSuccessFlag 1 : EtpZeroSuccessFlag1 EtpZeroSuccessFlag2 EtpZeroSuccessFlagEtpZeroSuccessFlag;
SIG_GROUP_ 431 GrlShttrDmd 1 : GrlShttrDmdShttrCalEna GrlShttrDmdShttrPosnReq;
SIG_GROUP_ 431 GrlShttrSts 1 : GrlShttrStsShttrActrFlt GrlShttrStsShttrBlkd GrlShttrStsShttrCalActv GrlShttrStsShttrCalIndcd GrlShttrStsShttrElecErr GrlShttrStsShttrPosnRaw GrlShttrStsShttrSnsrFlt GrlShttrStsShttrTErr GrlShttrStsShttrULoErr;
SIG_GROUP_ 922 IntrLiCmdGroup 1 : IntrLiCmdGroupIntrLiActvn IntrLiCmdGroupIntrLiRoofDim IntrLiCmdGroupIntrLiRoofDmdOff;
SIG_GROUP_ 922 IntrMirrResp 1 : IntrMirrRespIntrMirrDimPerc IntrMirrRespIntrMirrIntFailr IntrMirrRespResdBoolean IntrMirrRespResdUInt6;
SIG_GROUP_ 431 KeyDiReq 1 : KeyDiReqKey0 KeyDiReqKey1 KeyDiReqKey10 KeyDiReqKey11 KeyDiReqKey2 KeyDiReqKey3 KeyDiReqKey4 KeyDiReqKey5 KeyDiReqKey6 KeyDiReqKey7 KeyDiReqKey8 KeyDiReqKey9;
SIG_GROUP_ 431 KeyReadStsToKeyRmn 1 : KeyReadStsToKeyRmnKey0 KeyReadStsToKeyRmnKey1 KeyReadStsToKeyRmnKey10 KeyReadStsToKeyRmnKey11 KeyReadStsToKeyRmnKey2 KeyReadStsToKeyRmnKey3 KeyReadStsToKeyRmnKey4 KeyReadStsToKeyRmnKey5 KeyReadStsToKeyRmnKey6 KeyReadStsToKeyRmnKey7 KeyReadStsToKeyRmnKey8 KeyReadStsToKeyRmnKey9;
SIG_GROUP_ 431 KeyReadStsToKeyWarn 1 : KeyReadStsToKeyWarnKey0 KeyReadStsToKeyWarnKey1 KeyReadStsToKeyWarnKey10 KeyReadStsToKeyWarnKey11 KeyReadStsToKeyWarnKey2 KeyReadStsToKeyWarnKey3 KeyReadStsToKeyWarnKey4 KeyReadStsToKeyWarnKey5 KeyReadStsToKeyWarnKey6 KeyReadStsToKeyWarnKey7 KeyReadStsToKeyWarnKey8 KeyReadStsToKeyWarnKey9;
SIG_GROUP_ 431 KeyReadStsToVmm 1 : KeyReadStsToVmmKey0 KeyReadStsToVmmKey1 KeyReadStsToVmmKey10 KeyReadStsToVmmKey11 KeyReadStsToVmmKey2 KeyReadStsToVmmKey3 KeyReadStsToVmmKey4 KeyReadStsToVmmKey5 KeyReadStsToVmmKey6 KeyReadStsToVmmKey7 KeyReadStsToVmmKey8 KeyReadStsToVmmKey9;
SIG_GROUP_ 431 KeyReadStsToVMMNFC 1 : KeyReadStsToVMMNFCKey0 KeyReadStsToVMMNFCKey1 KeyReadStsToVMMNFCKey10 KeyReadStsToVMMNFCKey11 KeyReadStsToVMMNFCKey12 KeyReadStsToVMMNFCKey13 KeyReadStsToVMMNFCKey14 KeyReadStsToVMMNFCKey15 KeyReadStsToVMMNFCKey2 KeyReadStsToVMMNFCKey3 KeyReadStsToVMMNFCKey4 KeyReadStsToVMMNFCKey5 KeyReadStsToVMMNFCKey6 KeyReadStsToVMMNFCKey7 KeyReadStsToVMMNFCKey8 KeyReadStsToVMMNFCKey9;
SIG_GROUP_ 431 MobDevBtnLockStsAndKeyId 1 : MobDevBtnLockStsAndKeyIdKeyId3 MobDevBtnLockStsAndKeyIdPsdNotPsd;
SIG_GROUP_ 431 MobDevBtnUnlckStsAndKeyId 1 : MobDevBtnUnlckStsAndKeyIdKeyId3 MobDevBtnUnlckStsAndKeyIdPsdNotPsd;
SIG_GROUP_ 431 MobDevKeyDiReq 1 : MobDevKeyDiReqKeySts0 MobDevKeyDiReqKeySts1 MobDevKeyDiReqKeySts10 MobDevKeyDiReqKeySts11 MobDevKeyDiReqKeySts12 MobDevKeyDiReqKeySts13 MobDevKeyDiReqKeySts14 MobDevKeyDiReqKeySts15 MobDevKeyDiReqKeySts2 MobDevKeyDiReqKeySts3 MobDevKeyDiReqKeySts4 MobDevKeyDiReqKeySts5 MobDevKeyDiReqKeySts6 MobDevKeyDiReqKeySts7 MobDevKeyDiReqKeySts8 MobDevKeyDiReqKeySts9;
SIG_GROUP_ 431 MobDevKeyEnaSts 1 : MobDevKeyEnaStsKey0 MobDevKeyEnaStsKey1 MobDevKeyEnaStsKey10 MobDevKeyEnaStsKey11 MobDevKeyEnaStsKey12 MobDevKeyEnaStsKey13 MobDevKeyEnaStsKey14 MobDevKeyEnaStsKey15 MobDevKeyEnaStsKey2 MobDevKeyEnaStsKey3 MobDevKeyEnaStsKey4 MobDevKeyEnaStsKey5 MobDevKeyEnaStsKey6 MobDevKeyEnaStsKey7 MobDevKeyEnaStsKey8 MobDevKeyEnaStsKey9;
SIG_GROUP_ 431 NFCKeyReadStsToKeyRmnWrn 1 : NFCKeyReadStsToKeyRmnWrnKey0 NFCKeyReadStsToKeyRmnWrnKey1 NFCKeyReadStsToKeyRmnWrnKey10 NFCKeyReadStsToKeyRmnWrnKey11 NFCKeyReadStsToKeyRmnWrnKey12 NFCKeyReadStsToKeyRmnWrnKey13 NFCKeyReadStsToKeyRmnWrnKey14 NFCKeyReadStsToKeyRmnWrnKey15 NFCKeyReadStsToKeyRmnWrnKey2 NFCKeyReadStsToKeyRmnWrnKey3 NFCKeyReadStsToKeyRmnWrnKey4 NFCKeyReadStsToKeyRmnWrnKey5 NFCKeyReadStsToKeyRmnWrnKey6 NFCKeyReadStsToKeyRmnWrnKey7 NFCKeyReadStsToKeyRmnWrnKey8 NFCKeyReadStsToKeyRmnWrnKey9;
SIG_GROUP_ 922 OHCFrBtnErrSts 1 : OHCFrBtnErrStsIntrLiSwtAllOnSts OHCFrBtnErrStsIntrLiSwtAutOnSts OHCFrBtnErrStsLiBtnReadingLe OHCFrBtnErrStsLiBtnReadingRi;
SIG_GROUP_ 922 OHCSecRowBtnErrSts 1 : OHCSecRowBtnErrStsLiBtnReadingLe OHCSecRowBtnErrStsLiBtnReadingRi;
SIG_GROUP_ 922 OHCThirdRowBtnErrSts 1 : OHCThirdRowBtnErrStsLiBtnReadingLe OHCThirdRowBtnErrStsLiBtnReadingRi;
SIG_GROUP_ 431 OutdBri 1 : OutdBriChks OutdBriCntr OutdBriSts;
SIG_GROUP_ 431 OutdBriHw 1 : OutdBriHwChks OutdBriHwCntr OutdBriHwOutdBriSts;
SIG_GROUP_ 922 RainSnsrDiagc 1 : RainSnsrDiagcRainSnsrHiTDetd RainSnsrDiagcRainSnsrHiVoltDetd;
SIG_GROUP_ 922 RainSnsrErr 1 : RainSnsrErrCalErr RainSnsrErrCalErrActv RainSnsrErrRainDetnErr RainSnsrErrRainDetnErrActv;
SIG_GROUP_ 922 ReadLiErrSts 1 : ReadLiErrStsReadLiStsFirstRowLe ReadLiErrStsReadLiStsFirstRowRi ReadLiErrStsReadLiStsSecondRowLe ReadLiErrStsReadLiStsSecondRowRi ReadLiErrStsReadLiStsThirdRowLe ReadLiErrStsReadLiStsThirdRowRi;
SIG_GROUP_ 922 ReadLiIntensityVal 1 : ReadLiIntensityValZone1 ReadLiIntensityValZone2 ReadLiIntensityValZone3 ReadLiIntensityValZone4 ReadLiIntensityValZone5 ReadLiIntensityValZone6;
SIG_GROUP_ 1189 SnsrIntrScanCmd 1 : SnsrIntrScanCmdAirFanSts SnsrIntrScanCmdArmReq SnsrIntrScanCmdCurtRollUpDwn SnsrIntrScanCmdRoofPosn SnsrIntrScanCmdTemp SnsrIntrScanCmdWinPosn;
SIG_GROUP_ 1189 SnsrSoundrBattBackedCmd 1 : SnsrSoundrBattBackedCmdArmCmd SnsrSoundrBattBackedCmdChirpTyp SnsrSoundrBattBackedCmdChrgReq SnsrSoundrBattBackedCmdSoundReq;
SIG_GROUP_ 431 SteerLockChk 1 : SteerLockChkSteerLockDataChk0 SteerLockChkSteerLockDataChk1 SteerLockChkSteerLockDataChk2 SteerLockChkSteerLockDataChk3 SteerLockChkSteerLockDataChk4 SteerLockChkSteerLockDataChk5 SteerLockChkSteerLockDataChk6 SteerLockChkSts;
SIG_GROUP_ 431 SteerLockReq 1 : SteerLockReqCommand SteerLockReqSteerLockDataReq0 SteerLockReqSteerLockDataReq1 SteerLockReqSteerLockDataReq2 SteerLockReqSteerLockDataReq3 SteerLockReqSteerLockDataReq4 SteerLockReqSteerLockDataReq5 SteerLockReqSteerLockDataReq6;
SIG_GROUP_ 1189 SunRoofAndCurtPosnCmd 1 : SunRoofAndCurtPosnCmdOpenPerc SunRoofAndCurtPosnCmdSel;
SIG_GROUP_ 1348 VFCVectorZCUDM 1 : VFCVectorZCUDMBlockID VFCVectorZCUDMVFCid0 VFCVectorZCUDMVFCid1 VFCVectorZCUDMVFCid10 VFCVectorZCUDMVFCid11 VFCVectorZCUDMVFCid12 VFCVectorZCUDMVFCid13 VFCVectorZCUDMVFCid14 VFCVectorZCUDMVFCid15 VFCVectorZCUDMVFCid16 VFCVectorZCUDMVFCid17 VFCVectorZCUDMVFCid18 VFCVectorZCUDMVFCid19 VFCVectorZCUDMVFCid2 VFCVectorZCUDMVFCid20 VFCVectorZCUDMVFCid21 VFCVectorZCUDMVFCid22 VFCVectorZCUDMVFCid23 VFCVectorZCUDMVFCid24 VFCVectorZCUDMVFCid25 VFCVectorZCUDMVFCid26 VFCVectorZCUDMVFCid27 VFCVectorZCUDMVFCid28 VFCVectorZCUDMVFCid29 VFCVectorZCUDMVFCid3 VFCVectorZCUDMVFCid30 VFCVectorZCUDMVFCid31 VFCVectorZCUDMVFCid32 VFCVectorZCUDMVFCid33 VFCVectorZCUDMVFCid34 VFCVectorZCUDMVFCid35 VFCVectorZCUDMVFCid36 VFCVectorZCUDMVFCid37 VFCVectorZCUDMVFCid38 VFCVectorZCUDMVFCid39 VFCVectorZCUDMVFCid4 VFCVectorZCUDMVFCid40 VFCVectorZCUDMVFCid41 VFCVectorZCUDMVFCid42 VFCVectorZCUDMVFCid43 VFCVectorZCUDMVFCid44 VFCVectorZCUDMVFCid45 VFCVectorZCUDMVFCid46 VFCVectorZCUDMVFCid47 VFCVectorZCUDMVFCid48 VFCVectorZCUDMVFCid49 VFCVectorZCUDMVFCid5 VFCVectorZCUDMVFCid50 VFCVectorZCUDMVFCid51 VFCVectorZCUDMVFCid52 VFCVectorZCUDMVFCid53 VFCVectorZCUDMVFCid54 VFCVectorZCUDMVFCid55 VFCVectorZCUDMVFCid56 VFCVectorZCUDMVFCid57 VFCVectorZCUDMVFCid58 VFCVectorZCUDMVFCid59 VFCVectorZCUDMVFCid6 VFCVectorZCUDMVFCid60 VFCVectorZCUDMVFCid61 VFCVectorZCUDMVFCid7 VFCVectorZCUDMVFCid8 VFCVectorZCUDMVFCid9;
SIG_GROUP_ 1189 WindCorrnVal 1 : WindCorrnValAmb WindCorrnValFrnt WindCorrnValHud;
SIG_GROUP_ 1189 WipgPwrActvnNotSafe 1 : WipgPwrActvnNotSafeAcsyMode WipgPwrActvnNotSafeDrvgMod;
SIG_GROUP_ 1189 WipgPwrActvnSafe 1 : WipgPwrActvnSafeWipgPwrAcsyModSafe WipgPwrActvnSafeWipgPwrDrvgModSafe;
SIG_GROUP_ 1189 WiprMotFrntLvrCmdNotSafe 1 : WiprMotFrntLvrCmdNotSafeLvrInHiSpdPosn WiprMotFrntLvrCmdNotSafeLvrInIntlPosn WiprMotFrntLvrCmdNotSafeLvrInLoSpdPosn WiprMotFrntLvrCmdNotSafeLvrInSnglStrokePos;
SIG_GROUP_ 427 XcuAcc 1 : XcuAccPadAnVolt XcuAccPwmDuty;
SIG_GROUP_ 427 XcuCharge 1 : XcuChargeNVolt XcuChargePVolt;
SIG_GROUP_ 427 XcuCpuLoad 1 : XcuCpuLoadAvgVal XcuCpuLoadMaxVal XcuCpuLoadMinVal;
SIG_GROUP_ 427 XcuDseWtTqProp 1 : XcuDseWtTqPropFrnt XcuDseWtTqPropRear;
SIG_GROUP_ 427 XcuSfCEstWhTq 1 : XcuSfCEstWhTqFrntBrkTq XcuSfCEstWhTqFrntPropTq XcuSfCEstWhTqReBrkTq XcuSfCEstWhTqRePropTq;
SIG_GROUP_ 427 XCUTemp 1 : XCUTempXcuMcuTemp XCUTempXcuPcbTemp;
SIG_GROUP_ 427 XcuV 1 : XcuVcc5vLsd XcuVcc5VSnr XcuVqco5vT35584 XcuVqt15vT35584 XcuVqt25vT35584 XcuVquc5vT35584 XcuVqvr5vT35584;
SIG_GROUP_ 1379 ZCUPdevelpsignalgroupResp 1 : ZCUPdevelpsignalgroupRespFunctiondevpsignalgroup1 ZCUPdevelpsignalgroupRespFunctiondevpsignalgroup2 ZCUPdevelpsignalgroupRespFunctiondevpsignalgroup3 ZCUPdevelpsignalgroupRespFunctiondevpsignalgroup4 ZCUPdevelpsignalgroupRespFunctiondevpsignalgroup5 ZCUPdevelpsignalgroupRespFunctiondevpsignalgroup6 ZCUPdevelpsignalgroupRespFunctiondevpsignalgroup7 ZCUPdevelpsignalgroupRespFunctiondevpsignalgroup8;
